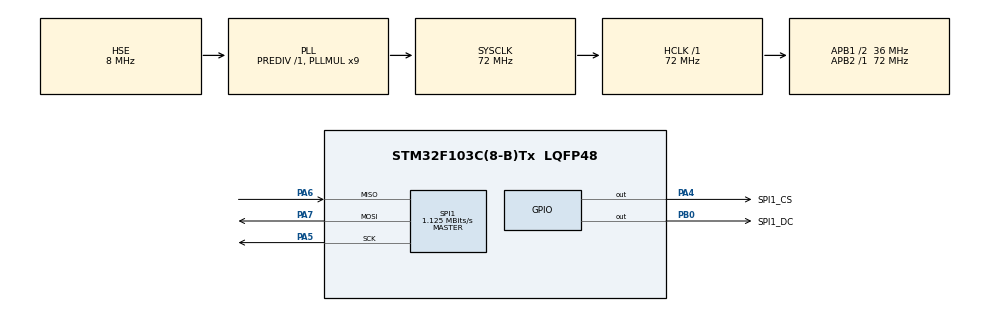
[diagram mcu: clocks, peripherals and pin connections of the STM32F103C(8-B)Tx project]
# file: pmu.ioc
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Mcu.Family=STM32F1
Mcu.Name=STM32F103C(8-B)Tx
Mcu.Package=LQFP48
NVIC.PriorityGroup=NVIC_PRIORITYGROUP_4
PA13.Mode=Serial_Wire
PA13.Signal=SYS_JTMS-SWDIO
PA14.Mode=Serial_Wire
PA14.Signal=SYS_JTCK-SWCLK
PA4.GPIO_Label=SPI1_CS
PA4.PinState=GPIO_PIN_RESET
PA4.Signal=GPIO_Output
PA5.Mode=Full_Duplex_Master
PA5.Signal=SPI1_SCK
PA6.Mode=Full_Duplex_Master
PA6.Signal=SPI1_MISO
PA7.Mode=Full_Duplex_Master
PA7.Signal=SPI1_MOSI
PB0.GPIO_Label=SPI1_DC
PB0.Signal=GPIO_Output
PD0-OSC_IN.Mode=HSE-External-Oscillator
PD0-OSC_IN.Signal=RCC_OSC_IN
PD1-OSC_OUT.Mode=HSE-External-Oscillator
PD1-OSC_OUT.Signal=RCC_OSC_OUT
ProjectManager.HeapSize=0x200
ProjectManager.StackSize=0x400
ProjectManager.TargetToolchain=MDK-ARM V5.32
RCC.AHBFreq_Value=72000000
RCC.APB1CLKDivider=RCC_HCLK_DIV2
RCC.APB1Freq_Value=36000000
RCC.APB1TimFreq_Value=72000000
RCC.APB2Freq_Value=72000000
RCC.APB2TimFreq_Value=72000000
RCC.HCLKFreq_Value=72000000
RCC.PLLMUL=RCC_PLL_MUL9
RCC.PLLSourceVirtual=RCC_PLLSOURCE_HSE
RCC.SYSCLKFreq_VALUE=72000000
RCC.SYSCLKSource=RCC_SYSCLKSOURCE_PLLCLK
RCC.USBFreq_Value=72000000
SPI1.BaudRatePrescaler=SPI_BAUDRATEPRESCALER_64
SPI1.CalculateBaudRate=1.125 MBits/s
SPI1.Direction=SPI_DIRECTION_2LINES
SPI1.Mode=SPI_MODE_MASTER
SPI1.VirtualType=VM_MASTER
board=custom

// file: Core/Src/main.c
/* USER CODE BEGIN Header */
/**
  ******************************************************************************
  * @file           : main.c
  * @brief          : Main program body
  ******************************************************************************
  * @attention
  *
  * Copyright (c) 2022 STMicroelectronics.
  * All rights reserved.
  *
  * This software is licensed under terms that can be found in the LICENSE file
  * in the root directory of this software component.
  * If no LICENSE file comes with this software, it is provided AS-IS.
  *
  ******************************************************************************
  */
/* USER CODE END Header */
#include "main.h"
#include "spi.h"
#include "gpio.h"

/* USER CODE BEGIN Includes */
//#include "struct_typedef.h"
/* USER CODE END Includes */

void SystemClock_Config(void);

/* USER CODE BEGIN 0 */
const unsigned uint8_t gImage_1[32768] = { /* 0X10,0X10,0X00,0X80,0X00,0X80,0X01,0X1B, */
0X49,0XE5,0X41,0XA5,0X41,0XA5,0X41,0XA5,0X41,0X84,0X39,0X43,0X39,0X44,0X39,0X64,
0X39,0X44,0X31,0X23,0X39,0X44,0X39,0X44,0X39,0X44,0X39,0X44,0X39,0X44,0X39,0X64,
0X31,0X23,0X31,0X23,0X31,0X23,0X31,0X23,0X31,0X23,0X31,0X23,0X31,0X43,0X39,0X64,
0X39,0X64,0X31,0X23,0X31,0X23,0X31,0X23,0X39,0X44,0X39,0X44,0X31,0X23,0X39,0X23,
0X41,0X85,0X41,0X64,0X39,0X64,0X39,0X64,0X41,0X64,0X39,0X64,0X39,0X84,0X39,0X84,
0X41,0X84,0X41,0XA5,0X39,0X84,0X31,0X43,0X31,0X43,0X31,0X43,0X31,0X43,0X31,0X43,
0X31,0X23,0X31,0X02,0X29,0X02,0X31,0X43,0X39,0X64,0X39,0X64,0X39,0X64,0X41,0X84,
0X41,0X64,0X39,0X23,0X39,0X43,0X39,0X23,0X39,0X64,0X39,0X64,0X39,0X64,0X39,0X43,
0X39,0X64,0X39,0X64,0X39,0X44,0X39,0X44,0X39,0X44,0X31,0X23,0X31,0X44,0X31,0X23,
0X31,0X03,0X31,0X03,0X31,0X23,0X31,0X23,0X31,0X23,0X31,0X23,0X31,0X03,0X31,0X23,
0X28,0XE2,0X20,0X81,0X28,0XE2,0X31,0X03,0X31,0X23,0X31,0X23,0X31,0X03,0X29,0X02,
0X31,0X03,0X31,0X03,0X29,0X03,0X29,0X03,0X29,0X02,0X29,0X03,0X31,0X03,0X31,0X23,
0X31,0X23,0X31,0X03,0X31,0X23,0X31,0X03,0X31,0X23,0X31,0X03,0X29,0X03,0X29,0X02,
0X29,0X02,0X29,0X23,0X21,0X22,0X29,0X23,0X29,0X23,0X29,0X03,0X29,0X03,0X20,0XE2,
0X20,0XC2,0X28,0XE2,0X29,0X02,0X39,0X64,0X39,0X44,0X31,0X44,0X29,0X03,0X28,0XE2,
0X28,0XE2,0X20,0XA1,0X20,0XA1,0X28,0XC2,0X28,0XE2,0X28,0XE2,0X28,0XE2,0X28,0XE2,
0X49,0XC5,0X39,0X64,0X39,0X63,0X39,0X64,0X39,0X43,0X31,0X23,0X31,0X03,0X31,0X03,
0X31,0X23,0X31,0X03,0X31,0X03,0X31,0X23,0X31,0X23,0X31,0X23,0X31,0X23,0X31,0X03,
0X29,0X02,0X28,0XE2,0X29,0X02,0X28,0XE2,0X28,0XE2,0X29,0X03,0X31,0X03,0X31,0X23,
0X39,0X44,0X31,0X23,0X39,0X23,0X39,0X23,0X39,0X44,0X31,0X23,0X31,0X03,0X31,0X03,
0X39,0X44,0X39,0X44,0X31,0X23,0X31,0X23,0X31,0X23,0X31,0X23,0X31,0X23,0X31,0X43,
0X31,0X23,0X31,0X43,0X31,0X23,0X31,0X23,0X29,0X02,0X31,0X23,0X31,0X23,0X29,0X02,
0X20,0XC1,0X20,0XC1,0X20,0XA1,0X31,0X02,0X31,0X03,0X31,0X43,0X41,0X84,0X39,0X43,
0X31,0X03,0X39,0X43,0X39,0X44,0X39,0X43,0X31,0X23,0X31,0X23,0X31,0X02,0X31,0X02,
0X31,0X03,0X31,0X03,0X31,0X02,0X31,0X02,0X31,0X03,0X28,0XE2,0X28,0XE2,0X28,0XE2,
0X28,0XC2,0X28,0XE2,0X28,0XE2,0X28,0XE2,0X28,0XE2,0X28,0XE2,0X28,0XE2,0X28,0XE2,
0X20,0XA1,0X10,0X40,0X20,0XA1,0X28,0XE2,0X28,0XE2,0X28,0XE2,0X20,0XC2,0X20,0XA1,
0X20,0XA1,0X28,0XC2,0X28,0XE2,0X28,0XE2,0X28,0XC2,0X28,0XE2,0X28,0XE2,0X28,0XE2,
0X28,0XE2,0X28,0XE2,0X28,0XE2,0X28,0XC2,0X20,0XC2,0X20,0XA1,0X20,0XA1,0X20,0XA1,
0X20,0XA1,0X20,0XA1,0X18,0XA1,0X18,0XC1,0X18,0XC1,0X18,0XC1,0X18,0XA1,0X20,0XA1,
0X18,0X80,0X20,0XC1,0X28,0XE2,0X31,0X03,0X29,0X03,0X28,0XE2,0X20,0XC2,0X28,0XE2,
0X28,0XE2,0X28,0XC2,0X20,0XA1,0X18,0X81,0X18,0X81,0X20,0X81,0X20,0X81,0X20,0XA1,
0X41,0X84,0X39,0X63,0X39,0X64,0X39,0X64,0X39,0X43,0X31,0X23,0X31,0X23,0X31,0X03,
0X31,0X03,0X31,0X03,0X31,0X23,0X31,0X23,0X31,0X03,0X31,0X23,0X39,0X23,0X31,0X03,
0X28,0XE2,0X28,0XE2,0X28,0XE2,0X29,0X03,0X29,0X02,0X29,0X02,0X31,0X03,0X31,0X23,
0X31,0X23,0X31,0X03,0X31,0X23,0X31,0X23,0X31,0X23,0X31,0X23,0X28,0XE2,0X28,0XE2,
0X39,0X44,0X39,0X44,0X31,0X23,0X39,0X23,0X39,0X23,0X31,0X23,0X31,0X23,0X31,0X43,
0X39,0X44,0X31,0X43,0X31,0X23,0X29,0X02,0X31,0X23,0X31,0X23,0X31,0X43,0X31,0X23,
0X28,0XE2,0X20,0XA1,0X20,0XA1,0X29,0X02,0X31,0X23,0X20,0XE1,0X52,0X67,0X29,0X23,
0X31,0X03,0X31,0X23,0X39,0X43,0X31,0X23,0X39,0X43,0X39,0X43,0X31,0X03,0X31,0X23,
0X31,0X03,0X31,0X03,0X31,0X03,0X31,0X03,0X31,0X03,0X31,0X02,0X31,0X03,0X28,0XE3,
0X28,0XE2,0X28,0XE2,0X28,0XE2,0X28,0XE2,0X28,0XE2,0X28,0XE2,0X28,0XE2,0X28,0XE2,
0X20,0XA1,0X10,0X40,0X20,0XA1,0X28,0XE2,0X28,0XE2,0X28,0XE2,0X20,0XC1,0X20,0XA1,
0X20,0XA1,0X28,0XE2,0X28,0XE2,0X28,0XE2,0X28,0XC2,0X28,0XE2,0X28,0XE2,0X28,0XE2,
0X28,0XE2,0X28,0XE2,0X28,0XE2,0X28,0XE2,0X20,0XC2,0X20,0XC2,0X20,0XC2,0X20,0XA1,
0X20,0XA1,0X20,0XA1,0X20,0XC1,0X18,0XE2,0X18,0XC2,0X20,0XC1,0X20,0XC1,0X20,0XA1,
0X18,0X81,0X18,0XA1,0X20,0XE2,0X31,0X03,0X29,0X03,0X28,0XE2,0X28,0XC2,0X20,0XC2,
0X20,0XA1,0X20,0X81,0X20,0X81,0X18,0XA1,0X18,0XA1,0X18,0XA1,0X18,0X81,0X18,0X81,
0X41,0X84,0X41,0X84,0X39,0X43,0X39,0X64,0X39,0X43,0X31,0X23,0X31,0X23,0X30,0XE2,
0X31,0X03,0X31,0X03,0X31,0X23,0X31,0X23,0X31,0X03,0X31,0X23,0X31,0X23,0X31,0X23,
0X31,0X03,0X28,0XE2,0X28,0XE2,0X28,0XE2,0X29,0X02,0X29,0X02,0X31,0X03,0X31,0X23,
0X31,0X23,0X31,0X03,0X31,0X23,0X31,0X23,0X31,0X03,0X31,0X23,0X28,0XE2,0X30,0XE2,
0X39,0X44,0X39,0X44,0X39,0X44,0X39,0X44,0X39,0X44,0X31,0X23,0X31,0X23,0X31,0X43,
0X39,0X44,0X31,0X43,0X31,0X23,0X29,0X02,0X31,0X23,0X31,0X23,0X31,0X43,0X29,0X02,
0X29,0X02,0X20,0XC1,0X18,0XA1,0X29,0X02,0X39,0X84,0X6B,0XAC,0X63,0X8B,0X29,0X43,
0X29,0X22,0X31,0X23,0X31,0X23,0X31,0X03,0X39,0X43,0X39,0X43,0X31,0X03,0X31,0X23,
0X31,0X23,0X31,0X23,0X31,0X03,0X31,0X03,0X31,0X03,0X31,0X02,0X28,0XE2,0X28,0XE2,
0X28,0XE2,0X28,0XE2,0X28,0XE2,0X28,0XE2,0X28,0XE2,0X28,0XE2,0X28,0XE2,0X28,0XE2,
0X20,0X81,0X10,0X20,0X20,0X81,0X28,0XE2,0X28,0XE2,0X28,0XE2,0X28,0XE2,0X20,0XC1,
0X28,0XC2,0X28,0XE2,0X28,0XE2,0X28,0XC2,0X28,0XC2,0X28,0XE2,0X28,0XE2,0X28,0XE2,
0X28,0XE2,0X28,0XE2,0X28,0XE2,0X28,0XC2,0X20,0XC2,0X20,0XC2,0X20,0XC2,0X20,0XA1,
0X20,0XC1,0X18,0XC1,0X18,0XC1,0X18,0XC1,0X18,0XC1,0X18,0XA1,0X18,0XA1,0X18,0XA1,
0X10,0X60,0X18,0X81,0X20,0XE2,0X29,0X03,0X29,0X03,0X29,0X03,0X28,0XE2,0X28,0XC2,
0X20,0XC2,0X20,0XA1,0X20,0XA1,0X18,0XA1,0X18,0XA1,0X18,0XA1,0X18,0X81,0X18,0X81,
0X41,0X84,0X39,0X44,0X39,0X44,0X39,0X44,0X39,0X43,0X31,0X23,0X31,0X23,0X31,0X02,
0X31,0X23,0X31,0X23,0X31,0X23,0X31,0X23,0X39,0X23,0X31,0X23,0X39,0X23,0X31,0X23,
0X31,0X23,0X29,0X03,0X28,0XE2,0X28,0XE2,0X28,0XE2,0X28,0XE2,0X31,0X03,0X31,0X23,
0X31,0X23,0X31,0X03,0X31,0X23,0X31,0X23,0X31,0X23,0X31,0X03,0X28,0XE2,0X29,0X02,
0X39,0X44,0X39,0X44,0X39,0X44,0X39,0X44,0X39,0X44,0X39,0X44,0X31,0X43,0X31,0X43,
0X39,0X43,0X39,0X44,0X39,0X23,0X31,0X03,0X31,0X23,0X31,0X23,0X31,0X23,0X31,0X03,
0X28,0XE2,0X20,0XA1,0X18,0XA1,0X29,0X23,0X29,0XC5,0X7C,0XAF,0X5B,0X8C,0X29,0XE6,
0X29,0X43,0X31,0X23,0X39,0X23,0X31,0X23,0X39,0X44,0X31,0X23,0X31,0X23,0X31,0X23,
0X31,0X03,0X31,0X03,0X39,0X03,0X31,0X03,0X31,0X23,0X31,0X03,0X28,0XE2,0X28,0XE2,
0X28,0XE2,0X28,0XC2,0X28,0XE2,0X28,0XE2,0X28,0XE2,0X28,0XE2,0X28,0XE2,0X28,0XE2,
0X18,0XA1,0X10,0X40,0X20,0X81,0X28,0XC2,0X28,0XC2,0X28,0XC2,0X20,0XC2,0X20,0XA1,
0X20,0XA1,0X20,0XC2,0X20,0XC1,0X20,0XC1,0X28,0XC2,0X28,0XE2,0X28,0XC2,0X28,0XE2,
0X28,0XE2,0X28,0XE2,0X28,0XC2,0X20,0XA1,0X28,0XC2,0X28,0XC2,0X20,0XC2,0X20,0XC1,
0X18,0XC1,0X18,0XC1,0X18,0XC1,0X18,0XA1,0X18,0XA2,0X18,0XA2,0X18,0XA2,0X18,0XA2,
0X10,0X61,0X18,0X81,0X29,0X03,0X31,0X23,0X29,0X03,0X29,0X03,0X28,0XE2,0X20,0XC2,
0X20,0XC2,0X18,0XA1,0X18,0XC1,0X18,0XC2,0X18,0XC2,0X18,0XA2,0X18,0XA1,0X18,0X81,
0X41,0X84,0X39,0X44,0X39,0X64,0X39,0X64,0X39,0X44,0X39,0X23,0X31,0X23,0X31,0X02,
0X31,0X03,0X31,0X03,0X31,0X03,0X31,0X23,0X31,0X23,0X31,0X23,0X31,0X03,0X31,0X03,
0X31,0X23,0X29,0X03,0X28,0XE2,0X28,0XE2,0X28,0XE2,0X29,0X03,0X31,0X03,0X31,0X23,
0X31,0X23,0X31,0X03,0X31,0X23,0X31,0X23,0X31,0X23,0X31,0X23,0X29,0X02,0X29,0X03,
0X31,0X44,0X39,0X44,0X39,0X44,0X39,0X44,0X39,0X44,0X31,0X43,0X31,0X23,0X39,0X44,
0X39,0X44,0X39,0X44,0X31,0X43,0X31,0X23,0X29,0X23,0X31,0X44,0X31,0X44,0X31,0X23,
0X29,0X02,0X20,0XC1,0X18,0XA1,0X29,0X23,0X31,0XE5,0X63,0XED,0X43,0X2A,0X53,0X2B,
0X31,0X84,0X39,0X23,0X39,0X03,0X39,0X23,0X39,0X23,0X39,0X03,0X31,0X03,0X31,0X03,
0X31,0X03,0X31,0X03,0X31,0X03,0X31,0X03,0X31,0X23,0X31,0X03,0X28,0XE3,0X28,0XE3,
0X28,0XE2,0X28,0XC2,0X28,0XE2,0X28,0XE2,0X28,0XE2,0X28,0XE2,0X28,0XE2,0X28,0XE2,
0X18,0XA1,0X10,0X40,0X18,0X81,0X28,0XE2,0X28,0XE2,0X20,0XC2,0X20,0XA2,0X20,0XA1,
0X20,0XA1,0X20,0XA2,0X20,0XA1,0X20,0XA1,0X20,0XC2,0X28,0XC2,0X28,0XC2,0X28,0XE2,
0X28,0XE2,0X28,0XE2,0X28,0XE2,0X20,0XC1,0X20,0XC2,0X20,0XC1,0X20,0XA1,0X18,0XA1,
0X18,0XC1,0X18,0XC1,0X18,0XC1,0X18,0XA1,0X18,0XA1,0X18,0XA2,0X18,0XA2,0X18,0XA1,
0X18,0X81,0X18,0X81,0X29,0X03,0X31,0X23,0X31,0X23,0X29,0X03,0X28,0XE2,0X20,0XE2,
0X18,0XA1,0X18,0XA1,0X18,0XA1,0X18,0XA1,0X18,0XA2,0X18,0XA2,0X18,0XA1,0X18,0XA1,
0X39,0X64,0X39,0X44,0X39,0X64,0X39,0X44,0X39,0X64,0X39,0X23,0X31,0X23,0X31,0X03,
0X31,0X03,0X31,0X03,0X31,0X03,0X31,0X03,0X31,0X03,0X39,0X23,0X39,0X23,0X31,0X23,
0X31,0X23,0X31,0X03,0X28,0XE2,0X28,0XE2,0X29,0X03,0X31,0X03,0X31,0X23,0X31,0X43,
0X31,0X23,0X31,0X23,0X39,0X23,0X31,0X23,0X39,0X23,0X31,0X23,0X31,0X23,0X31,0X23,
0X31,0X44,0X39,0X44,0X31,0X23,0X31,0X43,0X39,0X44,0X39,0X44,0X31,0X43,0X39,0X64,
0X39,0X64,0X39,0X44,0X31,0X43,0X29,0X02,0X29,0X23,0X31,0X43,0X31,0X23,0X31,0X23,
0X29,0X03,0X18,0XC1,0X18,0XA1,0X21,0X22,0X4A,0XA8,0X4B,0X29,0X4B,0X8B,0X42,0XE9,
0X39,0XC5,0X31,0X23,0X31,0X03,0X39,0X24,0X39,0X23,0X31,0X03,0X30,0XE2,0X39,0X24,
0X31,0X23,0X29,0X03,0X31,0X23,0X31,0X03,0X31,0X03,0X31,0X03,0X28,0XE2,0X28,0XE2,
0X28,0XE2,0X28,0XE2,0X28,0XE2,0X28,0XE2,0X28,0XE2,0X28,0XE2,0X28,0XE2,0X28,0XE2,
0X20,0XA1,0X10,0X40,0X18,0X81,0X28,0XC2,0X28,0XE2,0X20,0XC2,0X28,0XC2,0X20,0XA1,
0X20,0XC2,0X28,0XC2,0X20,0XC1,0X20,0XC1,0X28,0XC2,0X28,0XC2,0X28,0XE2,0X28,0XE2,
0X28,0XE2,0X28,0XE2,0X20,0XC2,0X20,0XC2,0X20,0XC2,0X20,0XC1,0X20,0XA1,0X20,0XA1,
0X20,0XC1,0X18,0XC1,0X18,0XC1,0X20,0XC1,0X20,0XA1,0X20,0XA2,0X18,0XA2,0X18,0XA2,
0X18,0X81,0X10,0X61,0X20,0XE3,0X31,0X03,0X31,0X03,0X29,0X03,0X28,0XE2,0X20,0XC2,
0X18,0XA1,0X18,0XA1,0X18,0XC1,0X18,0XA2,0X18,0X81,0X18,0XA2,0X18,0X81,0X18,0XA1,
0X39,0X64,0X39,0X44,0X39,0X64,0X39,0X64,0X39,0X64,0X31,0X23,0X31,0X23,0X31,0X03,
0X31,0X23,0X31,0X23,0X31,0X03,0X31,0X03,0X31,0X23,0X31,0X23,0X39,0X44,0X31,0X23,
0X31,0X23,0X31,0X23,0X29,0X02,0X28,0XE2,0X28,0XE2,0X29,0X02,0X31,0X03,0X31,0X23,
0X31,0X23,0X31,0X23,0X31,0X23,0X31,0X23,0X31,0X23,0X31,0X23,0X31,0X23,0X31,0X23,
0X39,0X44,0X31,0X44,0X39,0X64,0X39,0X64,0X39,0X44,0X31,0X43,0X39,0X44,0X39,0X64,
0X39,0X64,0X39,0X64,0X31,0X23,0X31,0X43,0X31,0X63,0X31,0X43,0X31,0X43,0X31,0X23,
0X29,0X02,0X18,0XC1,0X18,0XA1,0X21,0X43,0X74,0X0E,0X43,0X29,0X3B,0X09,0X4B,0X2B,
0X42,0X47,0X31,0X64,0X31,0X23,0X31,0X23,0X31,0X43,0X31,0X43,0X31,0X03,0X31,0X64,
0X31,0X84,0X29,0X23,0X31,0X64,0X31,0X23,0X31,0X03,0X30,0XE2,0X28,0XE2,0X28,0XE2,
0X28,0XE3,0X28,0XE3,0X28,0XE2,0X28,0XE2,0X28,0XE2,0X28,0XE2,0X28,0XE2,0X28,0XE2,
0X20,0XC1,0X10,0X40,0X18,0X60,0X28,0XC2,0X28,0XE2,0X20,0XC2,0X20,0XC2,0X20,0XA1,
0X20,0XA2,0X28,0XC2,0X28,0XC2,0X28,0XC2,0X28,0XE2,0X28,0XC2,0X28,0XE2,0X28,0XE2,
0X28,0XE2,0X28,0XE2,0X20,0XE2,0X20,0XE2,0X20,0XC2,0X20,0XC1,0X20,0XA1,0X20,0XA1,
0X20,0XC1,0X20,0XC1,0X18,0XC1,0X20,0XC1,0X20,0XC1,0X18,0X81,0X18,0XA1,0X18,0XA2,
0X18,0XA1,0X18,0X61,0X20,0XE3,0X29,0X03,0X31,0X23,0X31,0X23,0X28,0XC2,0X20,0XC1,
0X20,0XC2,0X20,0XC2,0X18,0XC1,0X18,0XA2,0X18,0X81,0X18,0XA2,0X20,0X81,0X18,0X81,
0X41,0X85,0X41,0X64,0X39,0X64,0X39,0X64,0X39,0X64,0X31,0X23,0X31,0X03,0X31,0X03,
0X31,0X23,0X31,0X23,0X31,0X23,0X31,0X23,0X31,0X23,0X31,0X23,0X39,0X44,0X31,0X03,
0X31,0X23,0X31,0X23,0X29,0X03,0X28,0XE3,0X31,0X03,0X31,0X03,0X31,0X23,0X31,0X23,
0X31,0X23,0X31,0X23,0X31,0X23,0X31,0X23,0X31,0X03,0X30,0XE3,0X31,0X23,0X39,0X44,
0X39,0X64,0X39,0X64,0X39,0X44,0X39,0X44,0X31,0X44,0X31,0X23,0X31,0X44,0X39,0X64,
0X39,0X64,0X39,0X64,0X31,0X84,0X29,0X84,0X29,0XA4,0X29,0X84,0X31,0XA4,0X29,0X23,
0X29,0X02,0X20,0XE2,0X20,0XC1,0X21,0X43,0X6C,0X0D,0X4B,0X6B,0X43,0X6B,0X43,0X4A,
0X52,0XEA,0X39,0XA5,0X31,0X43,0X31,0X64,0X29,0X43,0X21,0X22,0X31,0XA4,0X53,0X0A,
0X73,0XED,0X8C,0X6F,0X21,0X02,0X31,0X03,0X31,0X03,0X31,0X03,0X28,0XE2,0X28,0XE2,
0X28,0XC2,0X28,0XC2,0X28,0XE2,0X28,0XC2,0X28,0XC2,0X28,0XE2,0X28,0XE2,0X28,0XE2,
0X20,0XC2,0X10,0X60,0X10,0X40,0X20,0XA1,0X28,0XC2,0X20,0XC2,0X20,0XA1,0X20,0XA1,
0X20,0XC2,0X28,0XC2,0X28,0XE2,0X28,0XC2,0X28,0XE3,0X28,0XE2,0X28,0XC2,0X28,0XC2,
0X28,0XC2,0X28,0XE2,0X28,0XC2,0X20,0XC2,0X20,0XC1,0X20,0XC1,0X20,0XC1,0X20,0XA1,
0X20,0XA1,0X20,0XA1,0X20,0XA1,0X20,0XA1,0X20,0XA1,0X20,0XA1,0X20,0XA1,0X18,0X81,
0X18,0X81,0X18,0X61,0X20,0XE3,0X28,0XE2,0X31,0X23,0X28,0XE2,0X28,0XC2,0X28,0XC2,
0X20,0XA2,0X20,0XA2,0X20,0XA2,0X18,0XC2,0X18,0X81,0X18,0X82,0X20,0XA2,0X18,0X81,
0X41,0X85,0X41,0X85,0X39,0X64,0X39,0X64,0X39,0X64,0X31,0X23,0X31,0X23,0X31,0X23,
0X31,0X23,0X31,0X23,0X31,0X23,0X31,0X23,0X31,0X23,0X31,0X23,0X39,0X23,0X31,0X23,
0X31,0X23,0X31,0X43,0X31,0X23,0X29,0X03,0X31,0X03,0X31,0X03,0X31,0X23,0X31,0X03,
0X31,0X03,0X31,0X03,0X31,0X03,0X31,0X03,0X31,0X03,0X28,0XE2,0X31,0X23,0X31,0X23,
0X39,0X44,0X39,0X64,0X39,0X44,0X39,0X44,0X39,0X44,0X39,0X44,0X39,0X64,0X39,0X64,
0X39,0X64,0X39,0X64,0X5A,0XC9,0X74,0X2E,0X74,0X6F,0X74,0X6F,0X63,0XAC,0X3A,0X47,
0X29,0X84,0X21,0X02,0X18,0XC1,0X21,0X43,0X63,0XED,0X4B,0X4B,0X4B,0X6B,0X43,0X4A,
0X5B,0X8C,0X39,0XC5,0X29,0X43,0X29,0X43,0X31,0X84,0X4A,0XA9,0X84,0X90,0X5B,0XCC,
0X5B,0X4B,0X3A,0X06,0X29,0X43,0X31,0X23,0X31,0X03,0X31,0X03,0X29,0X03,0X28,0XE3,
0X28,0XE3,0X28,0XE2,0X28,0XE2,0X28,0XE2,0X28,0XC2,0X28,0XE2,0X28,0XC2,0X28,0XC2,
0X20,0XA2,0X18,0X80,0X10,0X40,0X20,0XC2,0X28,0XE2,0X28,0XC2,0X20,0XC2,0X20,0XA1,
0X20,0XA1,0X20,0XC2,0X28,0XE2,0X28,0XC2,0X28,0XC2,0X28,0XC2,0X28,0XC2,0X28,0XC2,
0X28,0XC2,0X28,0XE2,0X28,0XC2,0X20,0XC2,0X20,0XA1,0X20,0XA1,0X20,0XA1,0X20,0XA1,
0X20,0XA1,0X20,0XA1,0X20,0XA1,0X20,0XA1,0X20,0XA1,0X20,0XA1,0X20,0XA1,0X20,0XA2,
0X18,0X61,0X18,0X61,0X20,0XC2,0X28,0XE2,0X31,0X23,0X28,0XE2,0X28,0XE2,0X28,0XC2,
0X20,0XC2,0X20,0XA2,0X20,0XA2,0X18,0XC2,0X18,0XA2,0X18,0XA2,0X18,0XA2,0X18,0X82,
0X41,0X85,0X39,0X64,0X39,0X44,0X39,0X64,0X39,0X44,0X39,0X23,0X31,0X23,0X31,0X23,
0X31,0X03,0X31,0X23,0X39,0X44,0X39,0X44,0X31,0X23,0X39,0X23,0X39,0X43,0X39,0X44,
0X31,0X23,0X31,0X43,0X31,0X23,0X31,0X03,0X31,0X23,0X31,0X03,0X31,0X03,0X31,0X23,
0X31,0X23,0X31,0X03,0X29,0X03,0X31,0X03,0X31,0X03,0X28,0XE3,0X31,0X03,0X29,0X03,
0X31,0X23,0X39,0X64,0X39,0X64,0X39,0X64,0X39,0X64,0X39,0X44,0X39,0X44,0X39,0X64,
0X39,0X64,0X39,0X64,0X31,0X84,0X5B,0X6B,0X85,0X31,0X74,0XCF,0X6C,0XAF,0X6C,0X8F,
0X6C,0X6E,0X53,0X4A,0X19,0X42,0X32,0X26,0X53,0XAC,0X43,0X4B,0X3B,0X0A,0X43,0X2A,
0X4B,0X2A,0X42,0X68,0X31,0XA5,0X29,0X64,0X73,0XEE,0X5B,0XAC,0X43,0X4A,0X4B,0X4A,
0X53,0X0A,0X21,0X43,0X31,0X43,0X31,0X03,0X31,0X23,0X31,0X23,0X31,0X23,0X31,0X03,
0X29,0X03,0X28,0XE2,0X28,0XC2,0X28,0XC2,0X28,0XC2,0X28,0XE2,0X28,0XE2,0X28,0XE2,
0X28,0XE2,0X10,0X60,0X18,0X60,0X28,0XE2,0X28,0XE2,0X28,0XE2,0X20,0XC2,0X20,0XC2,
0X20,0XC2,0X20,0XC2,0X20,0XC2,0X20,0XA1,0X28,0XE2,0X28,0XC2,0X20,0XC2,0X28,0XC2,
0X28,0XE2,0X28,0XE2,0X20,0XC1,0X20,0XA1,0X20,0XA1,0X20,0XA1,0X20,0XA1,0X20,0XA1,
0X20,0XA1,0X20,0XA1,0X20,0XA1,0X20,0XA1,0X20,0XA1,0X20,0XA1,0X20,0XA1,0X20,0XA1,
0X18,0X80,0X18,0X60,0X20,0XC2,0X28,0XE2,0X29,0X03,0X28,0XE2,0X28,0XE2,0X28,0XE2,
0X28,0XC2,0X18,0XA2,0X18,0XA2,0X18,0XA2,0X18,0XA2,0X18,0X82,0X18,0X82,0X18,0X61,
0X41,0X85,0X39,0X64,0X39,0X44,0X39,0X64,0X39,0X64,0X39,0X44,0X31,0X23,0X31,0X23,
0X31,0X03,0X31,0X23,0X31,0X23,0X31,0X23,0X31,0X23,0X39,0X23,0X39,0X43,0X39,0X44,
0X31,0X23,0X31,0X43,0X31,0X23,0X31,0X03,0X31,0X03,0X31,0X03,0X31,0X03,0X31,0X23,
0X31,0X23,0X31,0X03,0X28,0XE3,0X29,0X03,0X28,0XE3,0X28,0XE2,0X29,0X03,0X29,0X03,
0X28,0XE2,0X31,0X03,0X39,0X64,0X39,0X64,0X39,0X64,0X39,0X44,0X39,0X44,0X39,0X64,
0X39,0X64,0X31,0X84,0X31,0X84,0X21,0X83,0X74,0X4E,0X6C,0XCF,0X6C,0XAF,0X64,0X6E,
0X64,0X2D,0X5C,0X2D,0X64,0X6E,0X5B,0XCC,0X4B,0XAB,0X43,0X4A,0X43,0X4B,0X43,0X4A,
0X4B,0X4A,0X4B,0X4A,0X53,0X4B,0X74,0X4F,0X53,0X8B,0X4B,0X6B,0X3B,0X2A,0X5B,0X6B,
0X31,0XA5,0X31,0X44,0X28,0XE2,0X31,0X03,0X31,0X03,0X29,0X23,0X31,0X03,0X31,0X03,
0X29,0X03,0X28,0XE2,0X28,0XC2,0X28,0XC2,0X28,0XE2,0X28,0XE2,0X28,0XE2,0X28,0XE2,
0X28,0XE2,0X18,0X80,0X18,0X60,0X20,0XC2,0X28,0XE2,0X20,0XC2,0X20,0XC2,0X20,0XC2,
0X20,0XC2,0X20,0XC2,0X20,0XA2,0X28,0XC2,0X28,0XC2,0X20,0XC2,0X20,0XA1,0X28,0XE2,
0X28,0XE2,0X28,0XE2,0X20,0XC1,0X20,0XA1,0X20,0XA1,0X20,0XA1,0X20,0XA1,0X20,0XA1,
0X20,0XA1,0X20,0XA1,0X20,0XA1,0X20,0XA1,0X20,0XA1,0X20,0XA1,0X20,0XA1,0X20,0XC2,
0X18,0X81,0X18,0X60,0X20,0XC1,0X28,0XE2,0X28,0XE2,0X28,0XE2,0X28,0XE2,0X28,0XE2,
0X28,0XE3,0X20,0XA2,0X18,0XA2,0X18,0XA2,0X18,0XA2,0X18,0X82,0X18,0X82,0X18,0X81,
0X41,0X85,0X39,0X64,0X39,0X44,0X39,0X64,0X39,0X64,0X39,0X44,0X31,0X23,0X31,0X23,
0X31,0X23,0X31,0X23,0X31,0X23,0X31,0X03,0X31,0X23,0X31,0X23,0X39,0X44,0X39,0X44,
0X39,0X23,0X39,0X44,0X31,0X44,0X31,0X23,0X31,0X23,0X31,0X23,0X31,0X23,0X31,0X23,
0X31,0X23,0X29,0X03,0X31,0X23,0X29,0X03,0X28,0XE2,0X28,0XE2,0X29,0X02,0X29,0X03,
0X28,0XE2,0X29,0X23,0X31,0X64,0X31,0X44,0X31,0X44,0X39,0X64,0X31,0X44,0X39,0X64,
0X41,0X64,0X39,0X64,0X39,0X64,0X31,0X84,0X31,0XE5,0X74,0XAF,0X64,0X4E,0X5C,0X0C,
0X4B,0X8B,0X5C,0X0C,0X4B,0XAB,0X4B,0X8B,0X43,0X6B,0X3A,0XE9,0X43,0X2A,0X4B,0X4B,
0X43,0X2A,0X43,0X2A,0X53,0X8C,0X4B,0X4B,0X3A,0XE9,0X43,0X2A,0X43,0X0A,0X52,0XC9,
0X39,0X44,0X39,0X44,0X28,0XE2,0X28,0XE2,0X29,0X03,0X29,0X03,0X29,0X03,0X29,0X03,
0X29,0X03,0X28,0XE2,0X28,0XE2,0X28,0XE2,0X28,0XE2,0X28,0XC2,0X28,0XC2,0X28,0XC2,
0X28,0XE2,0X18,0X81,0X10,0X40,0X20,0XA1,0X28,0XE2,0X20,0XC2,0X20,0XA1,0X20,0XA1,
0X20,0XA1,0X20,0XC2,0X28,0XC2,0X20,0XA1,0X28,0XC2,0X20,0XA1,0X20,0XA1,0X20,0XA2,
0X28,0XE2,0X28,0XC2,0X20,0XC2,0X20,0XA1,0X20,0XA1,0X20,0XC2,0X20,0XC2,0X20,0XA1,
0X20,0XA1,0X20,0XA1,0X20,0XC2,0X20,0XA1,0X20,0XA1,0X20,0XA2,0X20,0XA2,0X20,0XA1,
0X18,0X81,0X18,0X60,0X20,0XC2,0X28,0XE2,0X28,0XE2,0X29,0X02,0X28,0XE2,0X28,0XE2,
0X28,0XE2,0X20,0XA2,0X18,0XA2,0X18,0XA1,0X20,0XC2,0X18,0XA2,0X18,0XA2,0X18,0XA2,
0X41,0X85,0X39,0X44,0X39,0X64,0X39,0X64,0X39,0X64,0X39,0X44,0X31,0X23,0X31,0X23,
0X31,0X23,0X31,0X03,0X31,0X23,0X31,0X03,0X31,0X23,0X31,0X23,0X31,0X23,0X39,0X44,
0X39,0X23,0X39,0X44,0X39,0X64,0X31,0X23,0X31,0X43,0X31,0X23,0X31,0X23,0X31,0X23,
0X31,0X23,0X29,0X03,0X31,0X23,0X29,0X03,0X28,0XE2,0X28,0XE2,0X21,0X02,0X29,0X23,
0X29,0X03,0X29,0X23,0X31,0X44,0X31,0X44,0X31,0X44,0X39,0X64,0X31,0X44,0X39,0X64,
0X41,0X64,0X39,0X64,0X39,0X44,0X39,0X64,0X31,0X84,0X3A,0X67,0X6C,0X4E,0X4B,0X8A,
0X4B,0XAB,0X43,0X29,0X53,0XAB,0X4B,0XAB,0X43,0X4B,0X43,0X4B,0X43,0X2A,0X43,0X4B,
0X43,0X0A,0X43,0X6B,0X43,0X4B,0X43,0X4A,0X3B,0X0A,0X43,0X2A,0X4B,0X0A,0X31,0XC6,
0X31,0X24,0X31,0X23,0X28,0XE2,0X28,0XE3,0X31,0X03,0X31,0X03,0X29,0X03,0X29,0X03,
0X28,0XE2,0X28,0XE2,0X28,0XE2,0X28,0XE2,0X28,0XE2,0X28,0XC2,0X28,0XC2,0X28,0XE2,
0X28,0XE2,0X18,0X81,0X10,0X40,0X20,0XA1,0X28,0XC2,0X28,0XC2,0X20,0XA1,0X20,0XA1,
0X20,0XA1,0X20,0XC2,0X20,0XA2,0X20,0XA1,0X28,0XC2,0X20,0XA1,0X20,0XA1,0X20,0XA2,
0X28,0XC2,0X20,0XC2,0X20,0XC2,0X20,0XA1,0X20,0XA1,0X20,0XA1,0X20,0XA1,0X20,0XA1,
0X18,0X81,0X20,0X81,0X20,0XA1,0X20,0XA1,0X20,0XA1,0X20,0XA1,0X20,0X81,0X20,0XA1,
0X18,0X81,0X18,0X80,0X20,0XE2,0X28,0XE2,0X28,0XE2,0X29,0X02,0X28,0XE2,0X28,0XE2,
0X28,0XE2,0X20,0XA1,0X18,0X61,0X18,0XA1,0X20,0XA2,0X18,0XA2,0X18,0XA2,0X18,0X82,
0X39,0X64,0X39,0X64,0X39,0X44,0X39,0X44,0X39,0X64,0X39,0X44,0X39,0X44,0X31,0X23,
0X31,0X23,0X31,0X23,0X31,0X03,0X31,0X03,0X31,0X03,0X31,0X23,0X39,0X23,0X39,0X64,
0X39,0X44,0X39,0X44,0X39,0X64,0X31,0X03,0X29,0X03,0X31,0X23,0X31,0X23,0X31,0X03,
0X29,0X03,0X29,0X03,0X29,0X03,0X29,0X03,0X29,0X03,0X29,0X02,0X21,0X02,0X29,0X43,
0X29,0X23,0X29,0X43,0X31,0X43,0X31,0X43,0X31,0X44,0X39,0X64,0X39,0X64,0X39,0X64,
0X41,0X85,0X39,0X85,0X39,0X64,0X39,0X44,0X31,0X64,0X29,0X84,0X5B,0X6B,0X53,0XAB,
0X53,0XAB,0X53,0XCB,0X43,0X29,0X43,0X6A,0X4B,0X8B,0X43,0X2A,0X43,0X2A,0X3B,0X0A,
0X43,0X2A,0X43,0X0A,0X43,0X2B,0X3A,0XC9,0X43,0X2A,0X43,0X0A,0X4A,0XC9,0X29,0X44,
0X31,0X24,0X31,0X23,0X29,0X03,0X29,0X03,0X29,0X03,0X31,0X23,0X31,0X03,0X31,0X03,
0X28,0XE2,0X28,0XE2,0X28,0XE2,0X28,0XE2,0X28,0XE2,0X28,0XE2,0X28,0XE2,0X28,0XE2,
0X28,0XE2,0X18,0X81,0X10,0X40,0X20,0XC2,0X28,0XC2,0X28,0XC2,0X20,0XC2,0X20,0XA1,
0X20,0XA1,0X20,0XC2,0X20,0XC2,0X20,0XA2,0X20,0XC2,0X20,0XA1,0X20,0XA2,0X20,0XC2,
0X20,0XA2,0X20,0XA1,0X20,0XA1,0X20,0XA1,0X20,0XA1,0X20,0X81,0X18,0X81,0X18,0XA1,
0X18,0XA1,0X20,0XC1,0X18,0XA1,0X20,0XC1,0X18,0XA1,0X18,0XA1,0X18,0XA1,0X18,0XA1,
0X18,0X81,0X10,0X60,0X20,0XA1,0X28,0XE2,0X29,0X02,0X28,0XE2,0X20,0XC2,0X28,0XC2,
0X28,0XE2,0X20,0XC2,0X18,0X81,0X18,0X81,0X18,0XA1,0X18,0XA1,0X20,0XC2,0X18,0XA2,
0X39,0X64,0X39,0X64,0X39,0X44,0X39,0X44,0X39,0X64,0X39,0X44,0X39,0X23,0X31,0X03,
0X31,0X23,0X31,0X23,0X31,0X03,0X31,0X03,0X31,0X23,0X31,0X23,0X39,0X23,0X39,0X44,
0X39,0X44,0X39,0X44,0X31,0X44,0X31,0X23,0X29,0X02,0X29,0X03,0X31,0X23,0X31,0X23,
0X31,0X23,0X29,0X03,0X29,0X03,0X29,0X03,0X29,0X03,0X29,0X03,0X21,0X02,0X29,0X43,
0X29,0X23,0X29,0X43,0X31,0X43,0X31,0X23,0X31,0X44,0X39,0X64,0X31,0X44,0X39,0X64,
0X41,0X64,0X39,0X84,0X39,0X64,0X39,0X64,0X39,0X64,0X31,0X64,0X42,0X67,0X5B,0XAB,
0X4B,0X8B,0X43,0X4A,0X4B,0X8B,0X53,0XCC,0X43,0X4B,0X4B,0X6B,0X43,0X2A,0X43,0X0A,
0X43,0X2A,0X43,0X0A,0X4B,0X4B,0X43,0X2A,0X43,0X2A,0X42,0XEA,0X3A,0X27,0X31,0X65,
0X31,0X24,0X31,0X23,0X29,0X23,0X29,0X03,0X29,0X23,0X31,0X23,0X31,0X03,0X31,0X03,
0X28,0XE2,0X28,0XE2,0X28,0XE2,0X28,0XE2,0X28,0XE2,0X28,0XE2,0X28,0XE2,0X28,0XE2,
0X28,0XE2,0X18,0X81,0X10,0X40,0X20,0XC2,0X28,0XC2,0X28,0XC2,0X20,0XC2,0X20,0XA1,
0X20,0XA1,0X20,0XA1,0X20,0XA2,0X20,0XA1,0X20,0XA2,0X20,0XA1,0X20,0XC2,0X20,0XC2,
0X20,0XA1,0X20,0XA1,0X20,0XA1,0X20,0XA1,0X20,0X81,0X18,0X81,0X18,0X81,0X18,0X81,
0X18,0X81,0X20,0XC1,0X18,0XA1,0X18,0XC1,0X18,0XC1,0X18,0XA1,0X18,0XA1,0X20,0XA1,
0X18,0XA1,0X10,0X60,0X20,0XA1,0X28,0XE2,0X29,0X02,0X28,0XE2,0X28,0XE2,0X28,0XE2,
0X28,0XE2,0X28,0XE2,0X18,0X81,0X18,0X81,0X18,0XA1,0X18,0X81,0X18,0XA2,0X18,0XA2,
0X41,0X85,0X39,0X64,0X39,0X64,0X39,0X44,0X39,0X64,0X39,0X44,0X31,0X44,0X31,0X23,
0X31,0X23,0X29,0X03,0X31,0X23,0X31,0X03,0X31,0X23,0X31,0X23,0X31,0X44,0X31,0X24,
0X31,0X24,0X39,0X44,0X31,0X23,0X31,0X23,0X31,0X03,0X28,0XE2,0X28,0XE2,0X29,0X03,
0X31,0X23,0X29,0X03,0X29,0X03,0X28,0XE2,0X29,0X03,0X31,0X23,0X29,0X23,0X29,0X23,
0X29,0X23,0X31,0X23,0X31,0X23,0X31,0X43,0X31,0X44,0X31,0X64,0X31,0X43,0X39,0X64,
0X41,0X84,0X41,0X64,0X39,0X64,0X41,0X64,0X39,0X64,0X41,0XA5,0X39,0XC5,0X5B,0X6B,
0X4B,0X6B,0X4B,0X6B,0X43,0X4A,0X4B,0X4A,0X4B,0X4B,0X43,0X4A,0X43,0X4A,0X43,0X2A,
0X3B,0X09,0X3A,0XE9,0X43,0X2A,0X43,0X2A,0X43,0X2A,0X43,0X0A,0X31,0XE6,0X39,0X65,
0X31,0X24,0X21,0X23,0X29,0X43,0X29,0X64,0X39,0XA5,0X31,0X44,0X31,0X23,0X31,0X23,
0X29,0X03,0X29,0X03,0X28,0XE2,0X28,0XE2,0X28,0XE2,0X28,0XE2,0X28,0XE2,0X28,0XC2,
0X29,0X03,0X20,0XA1,0X10,0X40,0X20,0XC2,0X20,0XC2,0X28,0XE2,0X20,0XA1,0X20,0XA1,
0X20,0XA1,0X20,0XA1,0X20,0XA1,0X20,0XA1,0X20,0XA1,0X20,0XA1,0X20,0XA1,0X20,0XA1,
0X20,0XA2,0X20,0XA1,0X20,0XA2,0X18,0XA2,0X20,0XA2,0X18,0X81,0X18,0X81,0X18,0XA1,
0X18,0XA1,0X18,0XA1,0X18,0XA2,0X18,0XA2,0X18,0XA1,0X20,0XA2,0X20,0XA1,0X18,0XA1,
0X18,0X81,0X10,0X40,0X20,0XA1,0X20,0XE2,0X28,0XE2,0X28,0XE2,0X28,0XE2,0X28,0XE2,
0X28,0XE2,0X20,0XE2,0X18,0XA1,0X18,0XA1,0X18,0XA2,0X18,0XA2,0X20,0XA2,0X20,0XA2,
0X39,0X64,0X39,0X64,0X39,0X64,0X39,0X44,0X41,0X64,0X39,0X44,0X31,0X43,0X29,0X23,
0X29,0X03,0X29,0X02,0X31,0X03,0X31,0X03,0X31,0X03,0X31,0X23,0X31,0X23,0X31,0X23,
0X31,0X23,0X31,0X44,0X31,0X44,0X31,0X23,0X29,0X03,0X28,0XE2,0X28,0XE2,0X29,0X03,
0X31,0X23,0X31,0X03,0X28,0XE2,0X28,0XE2,0X31,0X03,0X31,0X23,0X29,0X23,0X29,0X03,
0X29,0X23,0X31,0X23,0X31,0X23,0X31,0X44,0X31,0X44,0X31,0X43,0X31,0X43,0X39,0X64,
0X41,0X84,0X39,0X84,0X39,0XA4,0X31,0X84,0X39,0X64,0X41,0XC5,0X29,0X84,0X63,0XAC,
0X53,0X8B,0X4B,0X8B,0X4B,0X8B,0X4B,0X6B,0X4B,0X6B,0X4B,0X8B,0X43,0X2A,0X43,0X2A,
0X43,0X2A,0X43,0X0A,0X3B,0X09,0X3B,0X09,0X43,0X0A,0X43,0X0A,0X29,0X85,0X29,0X24,
0X4A,0X68,0X63,0X8B,0X6B,0XCD,0X74,0X0E,0X73,0XCD,0X5A,0XEA,0X31,0X23,0X31,0X23,
0X29,0X03,0X28,0XE2,0X28,0XE2,0X28,0XE2,0X28,0XE2,0X28,0XE2,0X28,0XE2,0X28,0XE2,
0X28,0XE2,0X20,0XA1,0X10,0X40,0X20,0XC2,0X20,0XC2,0X20,0XC2,0X20,0XA1,0X20,0XA1,
0X20,0XA1,0X20,0XA1,0X20,0XA1,0X20,0X81,0X20,0XA1,0X20,0XA1,0X20,0XA1,0X20,0XC2,
0X28,0XC2,0X20,0XA1,0X20,0XA2,0X18,0XA2,0X18,0X81,0X18,0X82,0X20,0XA2,0X20,0XA1,
0X18,0X80,0X18,0X81,0X18,0X81,0X18,0X82,0X18,0XA1,0X20,0XA2,0X18,0XA1,0X18,0XA1,
0X18,0X81,0X10,0X40,0X18,0XA1,0X20,0XE2,0X28,0XC2,0X28,0XC2,0X28,0XE2,0X28,0XE2,
0X28,0XE2,0X20,0XE2,0X18,0XA1,0X18,0XA2,0X18,0XA2,0X20,0XA2,0X20,0XA2,0X20,0XA2,
0X39,0X44,0X39,0X64,0X39,0X64,0X39,0X64,0X41,0X64,0X39,0X64,0X31,0X43,0X29,0X23,
0X29,0X23,0X29,0X03,0X29,0X03,0X31,0X23,0X31,0X03,0X31,0X03,0X31,0X23,0X39,0X44,
0X31,0X23,0X31,0X44,0X31,0X44,0X31,0X44,0X29,0X03,0X28,0XE2,0X28,0XE2,0X29,0X03,
0X31,0X23,0X31,0X03,0X28,0XE2,0X28,0XE2,0X31,0X23,0X31,0X23,0X29,0X23,0X29,0X03,
0X29,0X23,0X29,0X23,0X29,0X23,0X31,0X64,0X31,0X44,0X31,0X23,0X31,0X23,0X31,0X43,
0X42,0X06,0X5B,0X2A,0X7C,0X4E,0X8C,0XD0,0X74,0X0D,0X5B,0X4A,0X3A,0X66,0X4B,0X4A,
0X53,0XEC,0X4B,0X8B,0X43,0X4A,0X4B,0X6B,0X4B,0X6B,0X43,0X2A,0X43,0X2A,0X3A,0XE9,
0X43,0X4A,0X43,0X2A,0X43,0X0A,0X4B,0X4B,0X43,0X2A,0X3A,0XE9,0X4A,0XEA,0X63,0XCD,
0X64,0X0D,0X53,0XCB,0X4B,0X2A,0X53,0X6B,0X63,0X8C,0X42,0X27,0X29,0X03,0X29,0X03,
0X29,0X03,0X29,0X03,0X28,0XE2,0X28,0XE2,0X28,0XE2,0X28,0XE2,0X28,0XE2,0X28,0XE2,
0X28,0XE2,0X20,0XA1,0X10,0X40,0X20,0XC2,0X20,0XC2,0X20,0XC2,0X20,0XA1,0X20,0XA1,
0X20,0XA1,0X20,0XA1,0X20,0X81,0X18,0X81,0X20,0XA1,0X20,0XA1,0X20,0X81,0X20,0XC2,
0X28,0XE2,0X20,0XA1,0X20,0XA1,0X18,0XA2,0X18,0X81,0X18,0X81,0X18,0XA2,0X18,0XA1,
0X18,0XA1,0X18,0XA1,0X20,0XA2,0X18,0XA2,0X18,0XA2,0X20,0XA2,0X18,0XA1,0X18,0XA1,
0X18,0X81,0X10,0X40,0X18,0X81,0X20,0XC2,0X28,0XC2,0X28,0XC2,0X28,0XE2,0X28,0XC2,
0X28,0XE2,0X28,0XC2,0X20,0XA2,0X18,0XA2,0X18,0XA2,0X20,0XA2,0X20,0XA2,0X20,0XA2,
0X39,0X64,0X39,0X64,0X39,0X64,0X39,0X64,0X39,0X64,0X39,0X64,0X29,0X23,0X21,0X02,
0X29,0X23,0X29,0X03,0X29,0X02,0X29,0X03,0X31,0X03,0X29,0X03,0X31,0X03,0X31,0X23,
0X31,0X03,0X31,0X23,0X31,0X44,0X31,0X23,0X31,0X23,0X28,0XE2,0X29,0X03,0X29,0X03,
0X31,0X23,0X29,0X03,0X28,0XE2,0X29,0X03,0X31,0X23,0X31,0X23,0X29,0X23,0X29,0X23,
0X29,0X03,0X29,0X03,0X31,0X23,0X31,0X44,0X31,0X44,0X31,0X23,0X31,0X23,0X39,0X84,
0X7C,0X4E,0X7C,0XD0,0X7C,0XF0,0X74,0XAF,0X6C,0X6E,0X63,0XEC,0X5C,0X0C,0X5C,0X2D,
0X53,0XEC,0X4B,0X8B,0X4B,0X8B,0X4B,0X6B,0X4B,0X8C,0X43,0X2A,0X43,0X0A,0X43,0X2A,
0X4B,0X4B,0X4B,0X6B,0X43,0X2A,0X43,0X0A,0X43,0X2A,0X43,0X2A,0X3A,0XE9,0X43,0X2A,
0X3B,0X4A,0X3B,0X49,0X4B,0X4A,0X53,0X2A,0X32,0X06,0X21,0X23,0X29,0X03,0X28,0XE2,
0X28,0XE2,0X28,0XE2,0X28,0XE2,0X28,0XE2,0X28,0XE2,0X28,0XC2,0X28,0XE2,0X28,0XE2,
0X20,0XC2,0X20,0XA1,0X10,0X40,0X20,0XA1,0X20,0XA1,0X20,0XA1,0X20,0XA1,0X20,0XA1,
0X20,0XA1,0X20,0XA1,0X20,0XA1,0X18,0X60,0X20,0XA1,0X20,0XA1,0X20,0X81,0X20,0X81,
0X28,0XC2,0X20,0XA1,0X20,0XA2,0X18,0XA1,0X18,0XA1,0X18,0X81,0X18,0X81,0X18,0X81,
0X18,0X80,0X18,0X81,0X18,0X81,0X18,0XA2,0X18,0XA2,0X18,0XA1,0X18,0XA1,0X18,0X81,
0X18,0X81,0X18,0X60,0X18,0XA1,0X20,0XC1,0X28,0XC2,0X28,0XC2,0X28,0XE2,0X28,0XE2,
0X28,0XA1,0X28,0XE2,0X20,0XA2,0X18,0XA2,0X18,0XA2,0X18,0XA2,0X18,0XA2,0X20,0XA2,
0X39,0X64,0X39,0X64,0X39,0X64,0X39,0X64,0X39,0X64,0X39,0X64,0X31,0X43,0X29,0X23,
0X29,0X23,0X29,0X23,0X29,0X23,0X29,0X03,0X29,0X03,0X31,0X23,0X31,0X23,0X31,0X23,
0X31,0X44,0X39,0X44,0X31,0X44,0X31,0X23,0X31,0X23,0X29,0X02,0X29,0X03,0X29,0X03,
0X29,0X03,0X28,0XE2,0X28,0XE2,0X29,0X03,0X31,0X23,0X31,0X23,0X29,0X23,0X29,0X23,
0X29,0X23,0X29,0X03,0X31,0X23,0X31,0X44,0X31,0X64,0X31,0X43,0X31,0X23,0X31,0X84,
0X32,0X05,0X85,0X10,0X74,0XCF,0X64,0X8E,0X5C,0X2D,0X53,0XEC,0X43,0X4A,0X43,0X4A,
0X4B,0X8B,0X4B,0XAB,0X43,0X4A,0X4B,0X6B,0X43,0X2A,0X43,0X2A,0X43,0X2A,0X43,0X2A,
0X3B,0X0A,0X43,0X2A,0X43,0X0A,0X3A,0XE9,0X3A,0XE9,0X43,0X2A,0X43,0X2A,0X43,0X6A,
0X3B,0X29,0X43,0X49,0X4A,0XE9,0X19,0X02,0X29,0X43,0X29,0X02,0X29,0X03,0X28,0XE2,
0X28,0XE2,0X28,0XE2,0X28,0XE2,0X28,0XE2,0X28,0XE2,0X28,0XC2,0X28,0XE2,0X28,0XE2,
0X20,0XC2,0X20,0XC2,0X10,0X40,0X20,0XA1,0X20,0XC2,0X20,0XA1,0X20,0XA1,0X20,0XA1,
0X20,0XC2,0X20,0XC2,0X20,0XA1,0X20,0XA1,0X20,0X81,0X20,0XA1,0X20,0XA1,0X20,0XA1,
0X28,0XC2,0X20,0XA1,0X20,0XA1,0X18,0XA1,0X18,0XA1,0X18,0X81,0X18,0X80,0X18,0X61,
0X18,0X60,0X18,0X81,0X18,0X81,0X18,0XA2,0X18,0XA2,0X18,0XA1,0X18,0XA1,0X18,0XA1,
0X18,0XA1,0X18,0X60,0X18,0XA1,0X20,0XC1,0X28,0XC2,0X28,0XC2,0X28,0XE2,0X30,0XE2,
0X20,0XA1,0X28,0XC2,0X20,0XA2,0X20,0XA2,0X18,0XA2,0X20,0XA2,0X20,0XA2,0X20,0XA2,
0X41,0X85,0X39,0X64,0X41,0X85,0X41,0X64,0X39,0X85,0X39,0X64,0X31,0X44,0X29,0X02,
0X29,0X03,0X31,0X23,0X29,0X23,0X29,0X03,0X31,0X23,0X31,0X23,0X29,0X03,0X31,0X23,
0X31,0X23,0X31,0X43,0X31,0X23,0X31,0X23,0X31,0X23,0X29,0X02,0X29,0X03,0X28,0XE2,
0X28,0XE3,0X28,0XE2,0X29,0X03,0X29,0X03,0X31,0X23,0X31,0X23,0X31,0X23,0X31,0X23,
0X31,0X03,0X31,0X23,0X31,0X23,0X31,0X23,0X31,0X43,0X31,0X43,0X31,0X43,0X31,0X43,
0X31,0X64,0X31,0XC4,0X74,0X4E,0X74,0XCF,0X74,0XAF,0X5C,0X0D,0X4B,0X8B,0X43,0X8B,
0X43,0X6A,0X4B,0X8B,0X43,0X4A,0X43,0X2A,0X4B,0X6B,0X4B,0X6B,0X43,0X2A,0X3A,0XE9,
0X4B,0X6B,0X43,0X4A,0X43,0X2A,0X3A,0XE9,0X4B,0X4B,0X3A,0XE9,0X43,0X29,0X43,0X29,
0X43,0X4A,0X4B,0X4A,0X21,0X63,0X21,0X03,0X29,0X03,0X29,0X03,0X28,0XE2,0X28,0XE2,
0X28,0XE2,0X28,0XE2,0X28,0XE2,0X28,0XE2,0X28,0XE2,0X20,0XC2,0X28,0XC2,0X20,0XC2,
0X20,0XA1,0X20,0XA1,0X10,0X40,0X18,0XA1,0X20,0XC2,0X20,0XA2,0X20,0XA1,0X20,0XA1,
0X20,0XA1,0X20,0XA1,0X20,0XA1,0X20,0XA1,0X18,0X81,0X20,0X81,0X20,0XA1,0X20,0XA1,
0X20,0XC2,0X20,0XA1,0X20,0XA1,0X18,0XA1,0X18,0XA1,0X18,0X81,0X18,0X81,0X18,0XA1,
0X18,0X81,0X18,0XA1,0X18,0XA1,0X18,0XA1,0X18,0XA1,0X18,0XA1,0X18,0XA1,0X18,0XA1,
0X18,0XA1,0X18,0X60,0X18,0X81,0X20,0XA1,0X28,0XE2,0X28,0XE2,0X28,0XE2,0X28,0XC2,
0X20,0XA1,0X28,0XC2,0X20,0XA1,0X20,0XA1,0X18,0X81,0X20,0XA2,0X20,0XA2,0X20,0XA2,
0X41,0X85,0X39,0X44,0X39,0X64,0X39,0X44,0X39,0X64,0X39,0X44,0X31,0X23,0X29,0X03,
0X29,0X23,0X31,0X23,0X31,0X23,0X31,0X23,0X31,0X23,0X29,0X03,0X31,0X23,0X31,0X03,
0X31,0X23,0X31,0X23,0X29,0X03,0X31,0X23,0X31,0X23,0X28,0XE2,0X28,0XE2,0X28,0XE2,
0X28,0XE2,0X28,0XE2,0X29,0X03,0X29,0X03,0X31,0X23,0X31,0X23,0X31,0X44,0X31,0X03,
0X29,0X03,0X29,0X03,0X29,0X03,0X31,0X23,0X31,0X43,0X31,0X43,0X31,0X23,0X31,0X43,
0X31,0X64,0X39,0X64,0X31,0X64,0X4A,0XE8,0X6C,0X2D,0X5C,0X2D,0X53,0XAB,0X3B,0X4A,
0X4B,0XAB,0X43,0X4A,0X43,0X2A,0X4B,0X6B,0X43,0X2A,0X4B,0X6B,0X43,0X2A,0X43,0X4B,
0X43,0X4B,0X4B,0X6B,0X4B,0X4B,0X43,0X2A,0X4B,0X6B,0X43,0X2A,0X3B,0X29,0X4B,0X2A,
0X53,0X2A,0X21,0X84,0X21,0X02,0X20,0XE2,0X29,0X03,0X29,0X03,0X28,0XE2,0X28,0XE2,
0X28,0XC2,0X20,0XC2,0X20,0XC2,0X20,0XC2,0X28,0XE2,0X20,0XA1,0X20,0XC2,0X20,0XC2,
0X20,0XA1,0X20,0XA1,0X10,0X40,0X18,0X81,0X20,0XA1,0X20,0XA1,0X20,0XA1,0X20,0XA1,
0X20,0XA1,0X20,0XA1,0X20,0XA1,0X20,0X81,0X18,0X60,0X20,0XA1,0X20,0XA1,0X20,0X81,
0X20,0XA1,0X20,0XA1,0X20,0XC2,0X20,0XC1,0X20,0XE2,0X18,0X81,0X18,0XA1,0X18,0X81,
0X18,0X80,0X20,0XA1,0X18,0XA1,0X18,0X81,0X18,0X81,0X18,0X81,0X18,0X81,0X18,0XA1,
0X18,0XA1,0X10,0X60,0X18,0X80,0X20,0XA1,0X20,0XA1,0X20,0XA1,0X20,0X81,0X20,0XA1,
0X20,0XA1,0X28,0XE2,0X20,0XA1,0X20,0XA1,0X18,0X81,0X20,0XA2,0X20,0XA2,0X20,0XA2,
0X39,0X64,0X39,0X64,0X39,0X44,0X39,0X44,0X39,0X64,0X39,0X44,0X31,0X43,0X29,0X23,
0X31,0X43,0X29,0X23,0X29,0X03,0X29,0X23,0X31,0X23,0X31,0X23,0X31,0X23,0X31,0X03,
0X31,0X03,0X31,0X23,0X31,0X23,0X29,0X03,0X31,0X23,0X29,0X02,0X28,0XC2,0X20,0XC2,
0X28,0XE2,0X28,0XC2,0X28,0XE2,0X28,0XE2,0X31,0X23,0X31,0X23,0X31,0X23,0X31,0X23,
0X29,0X03,0X31,0X03,0X31,0X23,0X31,0X23,0X31,0X43,0X39,0X23,0X31,0X23,0X31,0X43,
0X39,0X64,0X39,0X64,0X39,0X84,0X31,0XA4,0X42,0XC8,0X64,0X4E,0X53,0XCC,0X4B,0XAB,
0X43,0X6A,0X43,0X6A,0X43,0X6A,0X43,0X4A,0X43,0X4A,0X4B,0X6B,0X4B,0X6B,0X43,0X4A,
0X43,0X4A,0X4B,0X4B,0X43,0X2A,0X43,0X0A,0X43,0X2A,0X43,0X2A,0X43,0X4A,0X43,0X09,
0X32,0X26,0X21,0X83,0X29,0X64,0X31,0X64,0X29,0X03,0X29,0X02,0X28,0XE2,0X28,0XE2,
0X28,0XE2,0X28,0XC2,0X20,0XC2,0X20,0XC2,0X20,0XC1,0X20,0XA1,0X20,0XC2,0X20,0XC2,
0X20,0XA1,0X20,0XA1,0X10,0X40,0X10,0X60,0X20,0XA1,0X20,0XA1,0X20,0XA1,0X20,0XA1,
0X20,0XA1,0X20,0XA1,0X20,0XA1,0X18,0X81,0X18,0X81,0X20,0XA1,0X20,0XA1,0X20,0XA1,
0X20,0XA1,0X20,0XA1,0X20,0XA1,0X20,0XA1,0X20,0XA1,0X18,0X60,0X18,0X81,0X18,0XA1,
0X18,0X81,0X18,0XA1,0X18,0X81,0X18,0X81,0X18,0X81,0X18,0X60,0X20,0XA1,0X18,0XA1,
0X18,0X81,0X10,0X60,0X18,0X81,0X20,0XA1,0X20,0XA1,0X20,0XA1,0X20,0XA1,0X20,0XC1,
0X20,0XC1,0X28,0XE2,0X20,0XA1,0X20,0XA1,0X18,0XA1,0X20,0XA2,0X20,0XA2,0X20,0XA2,
0X39,0X64,0X39,0X64,0X39,0X44,0X39,0X44,0X39,0X64,0X39,0X44,0X31,0X23,0X31,0X23,
0X29,0X23,0X29,0X23,0X29,0X03,0X29,0X03,0X31,0X23,0X31,0X23,0X29,0X03,0X31,0X23,
0X31,0X23,0X31,0X23,0X31,0X23,0X29,0X03,0X31,0X03,0X29,0X02,0X28,0XE2,0X28,0XC2,
0X28,0XE2,0X28,0XE2,0X29,0X03,0X29,0X03,0X29,0X03,0X31,0X03,0X31,0X23,0X31,0X23,
0X31,0X03,0X31,0X23,0X31,0X23,0X31,0X23,0X31,0X23,0X39,0X23,0X39,0X23,0X31,0X43,
0X39,0X64,0X31,0X84,0X31,0X84,0X31,0XC4,0X4A,0XC8,0X64,0X2D,0X53,0XAB,0X4B,0X8A,
0X43,0X6A,0X43,0X6A,0X43,0X4A,0X4B,0X6B,0X43,0X4A,0X4B,0X4A,0X43,0X4A,0X43,0X4A,
0X43,0X4A,0X43,0X2A,0X43,0X0A,0X4B,0X6B,0X53,0X8C,0X53,0X8B,0X53,0XAB,0X4B,0X4A,
0X42,0XC8,0X53,0X4A,0X63,0X8C,0X31,0XA5,0X28,0XE2,0X20,0XE2,0X28,0XE2,0X28,0XE2,
0X28,0XE2,0X28,0XC2,0X20,0XC2,0X20,0XC2,0X20,0XA1,0X20,0XC2,0X20,0XC2,0X20,0XC2,
0X20,0XA1,0X20,0XA1,0X10,0X40,0X18,0X60,0X20,0XA1,0X20,0XA1,0X20,0XA1,0X20,0XA1,
0X20,0XA1,0X20,0XA1,0X20,0XA2,0X20,0XA1,0X20,0XA1,0X20,0X81,0X20,0XA1,0X20,0XA1,
0X20,0XA1,0X20,0XA1,0X20,0XA1,0X20,0XA1,0X20,0XC2,0X18,0X81,0X20,0XA1,0X20,0XC1,
0X18,0X60,0X18,0XA1,0X18,0X81,0X18,0X81,0X18,0X81,0X18,0X60,0X18,0X81,0X18,0XA1,
0X18,0X81,0X10,0X60,0X18,0X60,0X20,0X81,0X20,0XA1,0X20,0XA1,0X20,0XA1,0X20,0XC2,
0X20,0XC2,0X28,0XE2,0X20,0XA1,0X20,0XC1,0X20,0XA1,0X20,0XA2,0X20,0XA2,0X20,0XA2,
0X41,0X85,0X39,0X44,0X39,0X44,0X39,0X44,0X39,0X64,0X31,0X44,0X31,0X23,0X31,0X03,
0X29,0X03,0X31,0X23,0X29,0X03,0X29,0X02,0X31,0X23,0X31,0X03,0X29,0X03,0X29,0X03,
0X31,0X23,0X31,0X23,0X31,0X23,0X29,0X03,0X29,0X02,0X28,0XE2,0X28,0XE2,0X28,0XE2,
0X28,0XE2,0X28,0XE2,0X29,0X03,0X31,0X03,0X28,0XE2,0X28,0XE2,0X29,0X03,0X31,0X23,
0X29,0X03,0X31,0X03,0X31,0X23,0X31,0X23,0X31,0X23,0X31,0X23,0X31,0X23,0X31,0X43,
0X31,0X64,0X63,0X2B,0X84,0X90,0X7C,0X8F,0X6C,0X4E,0X53,0XCC,0X53,0XCC,0X4B,0XAB,
0X43,0X4A,0X43,0X6A,0X4B,0X6A,0X4B,0X6B,0X4B,0X6B,0X4B,0X8B,0X4B,0X6B,0X4B,0X6B,
0X43,0X2A,0X4B,0X6B,0X4B,0X6B,0X4B,0X8B,0X4B,0X6B,0X4B,0X8B,0X43,0X2A,0X4B,0X2A,
0X4B,0X4A,0X53,0X8B,0X5B,0X8C,0X29,0X84,0X29,0X03,0X29,0X03,0X29,0X03,0X28,0XE2,
0X28,0XC2,0X28,0XC2,0X20,0XC2,0X20,0XA1,0X20,0XC1,0X20,0XC2,0X20,0XA1,0X20,0XA1,
0X20,0XA1,0X20,0XA1,0X10,0X40,0X18,0X60,0X20,0XA1,0X20,0XA1,0X20,0XA1,0X20,0XA1,
0X20,0X81,0X20,0X82,0X20,0X82,0X20,0X81,0X20,0X81,0X20,0X81,0X20,0XA1,0X20,0XA1,
0X20,0XA1,0X20,0XA1,0X20,0XA1,0X20,0XA1,0X20,0XA1,0X20,0X81,0X20,0XA1,0X18,0XA1,
0X18,0X81,0X18,0XA1,0X18,0X81,0X10,0X60,0X18,0X81,0X18,0X81,0X18,0X81,0X18,0X81,
0X18,0X81,0X10,0X60,0X18,0X80,0X20,0XA1,0X20,0XA1,0X20,0XC1,0X20,0XC1,0X20,0XC1,
0X20,0XA1,0X28,0XE2,0X20,0XA1,0X20,0XA2,0X18,0X81,0X18,0XA2,0X18,0XA2,0X18,0XA2,
0X41,0XA5,0X39,0X23,0X39,0X64,0X39,0X64,0X39,0X44,0X31,0X43,0X31,0X23,0X31,0X03,
0X29,0X03,0X31,0X23,0X29,0X03,0X29,0X03,0X31,0X23,0X29,0X03,0X28,0XE2,0X31,0X03,
0X31,0X23,0X31,0X23,0X31,0X23,0X29,0X02,0X28,0XE2,0X28,0XE2,0X28,0XE2,0X28,0XE2,
0X28,0XE2,0X29,0X03,0X31,0X03,0X31,0X03,0X28,0XE2,0X28,0XE2,0X28,0XE2,0X31,0X23,
0X29,0X03,0X29,0X03,0X31,0X03,0X31,0X23,0X31,0X23,0X31,0X23,0X31,0X23,0X31,0X23,
0X39,0X44,0X5A,0XEA,0X7C,0X6F,0X5B,0XCC,0X4B,0XCB,0X53,0XAB,0X5B,0XEC,0X53,0XEC,
0X4B,0XAB,0X4B,0X8B,0X4B,0X8B,0X43,0X4A,0X43,0X4B,0X4B,0X4B,0X4B,0X4B,0X4B,0X4B,
0X4B,0X6B,0X43,0X2A,0X4B,0X4B,0X4B,0X4B,0X4B,0X4B,0X43,0X2A,0X43,0X6B,0X43,0X4B,
0X43,0X0A,0X53,0X6B,0X21,0X43,0X29,0X23,0X29,0X02,0X29,0X02,0X31,0X03,0X29,0X02,
0X28,0XE2,0X20,0XC2,0X20,0XC2,0X20,0XA1,0X20,0XC1,0X20,0XC2,0X20,0XA1,0X28,0XE2,
0X20,0XA1,0X20,0XA1,0X10,0X60,0X10,0X60,0X20,0XA1,0X20,0XA1,0X20,0XA1,0X20,0X81,
0X18,0X81,0X18,0X81,0X18,0X81,0X18,0X81,0X20,0XA1,0X20,0XA1,0X20,0XA1,0X20,0XA1,
0X20,0XA1,0X20,0XA1,0X20,0XA1,0X20,0XA1,0X20,0XA1,0X20,0XA1,0X20,0XA1,0X18,0X81,
0X18,0X81,0X18,0X81,0X18,0X81,0X18,0X60,0X18,0X61,0X18,0X61,0X18,0XA1,0X18,0X81,
0X18,0X81,0X10,0X40,0X18,0X61,0X20,0XA1,0X20,0XA1,0X18,0XA1,0X18,0XA1,0X20,0XC1,
0X20,0XA1,0X28,0XE2,0X20,0XA1,0X20,0XA2,0X18,0X81,0X18,0XA2,0X18,0XA2,0X18,0XA1,
0X39,0X64,0X39,0X44,0X39,0X44,0X39,0X44,0X31,0X44,0X31,0X43,0X31,0X23,0X31,0X03,
0X29,0X03,0X29,0X03,0X28,0XE2,0X28,0XE2,0X31,0X03,0X28,0XE2,0X29,0X02,0X29,0X03,
0X29,0X03,0X31,0X23,0X31,0X23,0X29,0X03,0X29,0X02,0X28,0XE2,0X28,0XE2,0X28,0XE2,
0X28,0XE2,0X29,0X03,0X29,0X03,0X29,0X03,0X28,0XE2,0X28,0XE2,0X28,0XE2,0X29,0X03,
0X29,0X03,0X29,0X03,0X29,0X03,0X31,0X03,0X31,0X23,0X31,0X23,0X31,0X23,0X31,0X23,
0X39,0X23,0X31,0X64,0X29,0XA4,0X5B,0X8B,0X5C,0X0C,0X5B,0XEC,0X53,0XCC,0X4B,0XAB,
0X4B,0X8B,0X4B,0X6A,0X4B,0X8B,0X43,0X4A,0X4B,0X6B,0X4B,0X8B,0X4B,0X8B,0X4B,0X8B,
0X53,0XAC,0X4B,0X4B,0X43,0X2A,0X4B,0X6B,0X4B,0X4B,0X43,0X2A,0X43,0X4B,0X43,0X2A,
0X4B,0X2B,0X21,0X84,0X21,0X02,0X28,0XE2,0X29,0X02,0X29,0X02,0X29,0X03,0X28,0XE2,
0X28,0XC2,0X20,0XC2,0X20,0XC2,0X20,0XC2,0X20,0XC1,0X20,0XC2,0X20,0XA1,0X20,0XC2,
0X20,0XC2,0X20,0XA1,0X10,0X20,0X10,0X60,0X20,0XA1,0X20,0XA1,0X20,0XA1,0X18,0XA1,
0X18,0X81,0X18,0X81,0X18,0X82,0X18,0X81,0X18,0X81,0X20,0XA1,0X20,0XA1,0X18,0X81,
0X18,0X80,0X20,0XA1,0X20,0XA1,0X20,0XA1,0X20,0XA1,0X20,0XA1,0X18,0X81,0X18,0XA2,
0X20,0XA2,0X18,0X81,0X18,0X81,0X18,0X81,0X18,0X61,0X18,0X61,0X18,0X81,0X18,0X81,
0X18,0XA2,0X18,0X61,0X18,0X61,0X20,0XA1,0X18,0XA1,0X20,0XA2,0X18,0XC2,0X20,0XC1,
0X18,0XA1,0X28,0XE2,0X20,0XA1,0X18,0XA2,0X18,0XA1,0X18,0XC2,0X18,0XA2,0X18,0XA2,
0X39,0X64,0X31,0X23,0X39,0X44,0X31,0X23,0X31,0X43,0X31,0X23,0X31,0X03,0X29,0X03,
0X28,0XE2,0X29,0X03,0X28,0XE2,0X28,0XE2,0X29,0X02,0X28,0XE2,0X28,0XE2,0X28,0XE2,
0X29,0X02,0X29,0X03,0X29,0X03,0X29,0X03,0X29,0X02,0X28,0XE2,0X28,0XE2,0X28,0XE2,
0X28,0XE2,0X28,0XE2,0X29,0X03,0X28,0XE2,0X29,0X03,0X28,0XE2,0X28,0XE2,0X29,0X03,
0X31,0X03,0X29,0X03,0X28,0XE2,0X28,0XE2,0X29,0X03,0X29,0X03,0X29,0X03,0X31,0X03,
0X31,0X03,0X31,0X23,0X31,0X84,0X29,0X84,0X3A,0X26,0X64,0X4E,0X53,0X8B,0X53,0XCB,
0X4B,0X8B,0X53,0XAB,0X53,0XAC,0X53,0XCC,0X53,0XAC,0X53,0XCC,0X4B,0X6B,0X53,0XAC,
0X53,0XAC,0X4B,0X6B,0X4B,0X6B,0X4B,0X4B,0X43,0X2A,0X4B,0X4B,0X43,0X2A,0X4A,0XE9,
0X29,0X43,0X31,0X23,0X29,0X02,0X28,0XE2,0X29,0X02,0X29,0X02,0X31,0X03,0X29,0X03,
0X28,0XC2,0X20,0XC1,0X20,0XC2,0X20,0XC2,0X20,0XA1,0X20,0XC1,0X20,0XA1,0X20,0XA1,
0X20,0XC2,0X20,0XA1,0X10,0X40,0X10,0X40,0X20,0X81,0X20,0XA1,0X18,0XA1,0X18,0XA1,
0X18,0X81,0X18,0XA1,0X18,0XA2,0X18,0XA1,0X18,0XA1,0X18,0XA1,0X20,0XA1,0X20,0X81,
0X18,0X81,0X20,0XA1,0X20,0XA1,0X20,0XA1,0X20,0XA1,0X20,0XA1,0X18,0X81,0X18,0XA2,
0X18,0X82,0X18,0X82,0X18,0XA2,0X18,0X81,0X18,0X82,0X18,0X81,0X18,0X81,0X18,0X81,
0X20,0XA2,0X18,0X61,0X10,0X41,0X20,0X82,0X18,0XA2,0X20,0XA2,0X18,0XC2,0X20,0XC1,
0X18,0XA1,0X28,0XE2,0X20,0XA1,0X20,0XA2,0X18,0XA2,0X18,0XC2,0X18,0XA2,0X18,0XA1,
0X39,0X44,0X39,0X44,0X31,0X23,0X31,0X23,0X31,0X23,0X31,0X23,0X29,0X03,0X29,0X03,
0X28,0XE2,0X28,0XE2,0X28,0XE2,0X28,0XE2,0X28,0XC2,0X28,0XC2,0X20,0XC2,0X28,0XC2,
0X28,0XE2,0X29,0X03,0X31,0X23,0X29,0X03,0X29,0X02,0X29,0X02,0X28,0XE2,0X28,0XC2,
0X28,0XC2,0X28,0XE3,0X29,0X03,0X28,0XE2,0X28,0XE2,0X20,0XC2,0X28,0XC2,0X28,0XE2,
0X29,0X03,0X28,0XE2,0X28,0XE2,0X28,0XE2,0X28,0XC2,0X28,0XE2,0X28,0XE2,0X29,0X03,
0X31,0X03,0X39,0X23,0X39,0X23,0X31,0X23,0X31,0X64,0X19,0X43,0X53,0X4A,0X5B,0XEC,
0X53,0XCC,0X4B,0X8B,0X5B,0XED,0X53,0XAC,0X5B,0XCC,0X5B,0XAC,0X53,0XAC,0X5B,0XAB,
0X53,0X8B,0X4B,0X69,0X53,0XAA,0X63,0XEC,0X5B,0XAB,0X4B,0X29,0X5B,0X6B,0X3A,0X26,
0X31,0X63,0X31,0X23,0X31,0X03,0X28,0XE2,0X29,0X02,0X29,0X03,0X29,0X02,0X29,0X03,
0X28,0XC2,0X28,0XA1,0X28,0XE2,0X20,0XC2,0X20,0XA1,0X20,0XA1,0X20,0XA1,0X20,0XA1,
0X20,0XC2,0X20,0XC1,0X18,0X80,0X10,0X40,0X18,0XA1,0X20,0XA1,0X20,0XA2,0X20,0X81,
0X18,0X81,0X20,0X82,0X18,0XA1,0X18,0X81,0X18,0X81,0X20,0X81,0X20,0X82,0X20,0X81,
0X20,0XA1,0X20,0XA1,0X20,0XA1,0X20,0XA1,0X20,0XA1,0X20,0X81,0X18,0X81,0X18,0XA2,
0X18,0XA2,0X18,0X81,0X18,0X81,0X18,0X81,0X18,0X80,0X18,0XA1,0X10,0X80,0X10,0X81,
0X18,0X81,0X18,0X60,0X10,0X40,0X20,0XA2,0X18,0XA2,0X20,0XA2,0X20,0XA2,0X20,0XA1,
0X20,0XA1,0X20,0XC2,0X20,0XA1,0X20,0XA1,0X20,0XA1,0X18,0X81,0X18,0X81,0X18,0X81,
0X39,0X44,0X39,0X44,0X31,0X23,0X31,0X03,0X31,0X23,0X31,0X23,0X29,0X03,0X29,0X03,
0X28,0XE2,0X20,0XC2,0X20,0XC2,0X20,0XE2,0X28,0XE2,0X28,0XC2,0X28,0XE2,0X28,0XE2,
0X29,0X02,0X29,0X03,0X28,0XE2,0X28,0XE2,0X29,0X02,0X28,0XE2,0X20,0XC2,0X20,0XA2,
0X20,0XC2,0X28,0XE3,0X29,0X03,0X28,0XE2,0X28,0XC2,0X20,0XA1,0X20,0XA1,0X28,0XC2,
0X28,0XE2,0X28,0XE2,0X28,0XE3,0X28,0XE3,0X28,0XC2,0X28,0XE2,0X28,0XC2,0X29,0X03,
0X31,0X03,0X31,0X23,0X31,0X03,0X31,0X03,0X31,0X44,0X31,0X43,0X29,0X64,0X4A,0XA8,
0X63,0X8B,0X6B,0XEC,0X6B,0XEC,0X74,0X0D,0X74,0X0D,0X8C,0XB0,0X9C,0XD0,0XAD,0X93,
0XBD,0XF3,0XBE,0X33,0XC6,0X33,0XC6,0X33,0XBD,0XF2,0XA5,0X50,0X7C,0X0C,0X6B,0X49,
0X52,0X46,0X49,0XE5,0X39,0X43,0X31,0X02,0X29,0X02,0X29,0X02,0X29,0X02,0X29,0X02,
0X28,0XE2,0X20,0XC1,0X28,0XE2,0X28,0XC2,0X20,0XA1,0X20,0XA1,0X20,0XA1,0X20,0XA1,
0X20,0XA1,0X20,0X81,0X18,0X80,0X10,0X40,0X18,0XA1,0X20,0XA1,0X20,0X81,0X18,0X81,
0X18,0X81,0X18,0X81,0X18,0X80,0X18,0X60,0X18,0X81,0X18,0X81,0X20,0X81,0X20,0X81,
0X20,0XA1,0X20,0XA1,0X20,0XA1,0X20,0XA1,0X20,0XA1,0X20,0XA1,0X20,0XA1,0X18,0X81,
0X18,0XA2,0X18,0XA1,0X18,0XA1,0X18,0X81,0X18,0X80,0X18,0XA1,0X10,0X80,0X10,0XA1,
0X18,0XA1,0X18,0X60,0X10,0X60,0X20,0XA2,0X20,0XA2,0X18,0XA2,0X18,0XA2,0X20,0XA1,
0X20,0XA1,0X20,0XC2,0X20,0XA1,0X20,0XA1,0X18,0XA1,0X20,0XE2,0X20,0XC2,0X18,0XA1,
0X31,0X43,0X31,0X44,0X31,0X23,0X29,0X02,0X31,0X03,0X31,0X03,0X28,0XE2,0X28,0XE3,
0X20,0XE2,0X20,0XC2,0X20,0XC2,0X20,0XE2,0X28,0XE2,0X28,0XC2,0X28,0XC2,0X28,0XE2,
0X28,0XE2,0X28,0XE2,0X29,0X02,0X29,0X03,0X29,0X03,0X29,0X02,0X28,0XC2,0X20,0XA2,
0X20,0XA2,0X28,0XC2,0X28,0XE2,0X28,0XE2,0X28,0XE2,0X20,0XA1,0X20,0XA1,0X20,0XC2,
0X28,0XE2,0X28,0XE2,0X28,0XE2,0X28,0XE2,0X28,0XC2,0X20,0XA2,0X20,0XC2,0X29,0X03,
0X31,0X03,0X31,0X23,0X31,0X23,0X29,0X03,0X39,0X64,0X39,0X43,0X31,0X42,0X52,0X26,
0XBD,0X93,0XDE,0X95,0XDE,0X95,0XDE,0XB6,0XCE,0X13,0XBD,0X31,0XDE,0X35,0XDE,0X55,
0XE6,0X74,0XE6,0X54,0XD5,0XF2,0XD5,0XD2,0XD6,0X13,0XAC,0XAE,0XCD,0XF3,0XDE,0X34,
0XD5,0XF4,0XD6,0X14,0XC5,0X92,0X73,0X29,0X41,0X83,0X39,0X43,0X31,0X23,0X28,0XE1,
0X28,0XE2,0X28,0XE2,0X28,0XC2,0X28,0XC2,0X28,0XC2,0X20,0XC2,0X20,0XA1,0X20,0XA1,
0X20,0XA1,0X18,0X81,0X10,0X60,0X10,0X40,0X18,0X81,0X18,0XA1,0X20,0X81,0X18,0X60,
0X18,0X60,0X18,0X60,0X18,0X80,0X18,0X80,0X18,0X81,0X18,0X81,0X18,0X81,0X20,0X81,
0X20,0XA1,0X20,0XC1,0X20,0XA1,0X20,0XA1,0X20,0XA1,0X20,0XA1,0X20,0XA1,0X18,0X82,
0X18,0XA1,0X18,0XA1,0X18,0XA1,0X18,0X80,0X10,0X80,0X10,0XA1,0X10,0X80,0X10,0XA1,
0X10,0XA1,0X10,0X80,0X10,0X60,0X18,0XA2,0X20,0XA2,0X20,0XA2,0X20,0XA2,0X20,0XA1,
0X20,0XA1,0X20,0XC2,0X20,0XA1,0X18,0XA1,0X18,0XA1,0X18,0XC2,0X18,0XC2,0X18,0XA2,
0X31,0X23,0X31,0X23,0X31,0X03,0X29,0X02,0X31,0X02,0X31,0X02,0X28,0XE2,0X28,0XE2,
0X20,0XC2,0X20,0XC2,0X20,0XE2,0X20,0XE3,0X20,0XC1,0X28,0XE2,0X28,0XE2,0X28,0XE2,
0X28,0XE2,0X28,0XE2,0X29,0X02,0X28,0XE2,0X28,0XE2,0X31,0X03,0X28,0XE2,0X20,0XA2,
0X20,0XA2,0X20,0XC2,0X28,0XC2,0X28,0XE2,0X28,0XE2,0X20,0XC2,0X20,0XC2,0X28,0XE2,
0X28,0XE2,0X28,0XE2,0X28,0XE2,0X28,0XC2,0X28,0XC2,0X28,0XC2,0X20,0XA2,0X28,0XE3,
0X31,0X23,0X31,0X23,0X31,0X23,0X31,0X23,0X52,0X07,0X62,0XA7,0XCD,0XF4,0XDE,0X75,
0XEE,0XB5,0XEE,0X95,0XE6,0X74,0XE6,0X33,0XE6,0X33,0XDD,0XF4,0XEE,0X55,0XEE,0X54,
0XD5,0X91,0XDD,0XD2,0XE5,0XF3,0XD5,0XB2,0XAC,0X6D,0XD5,0X92,0XDD,0XF4,0XDE,0X13,
0XD5,0XF2,0XE6,0X53,0XDE,0X53,0XD6,0X33,0XD6,0X14,0XB4,0XF0,0X62,0X68,0X31,0X23,
0X29,0X22,0X20,0XE1,0X28,0XC2,0X28,0XC2,0X20,0XC2,0X20,0XC1,0X20,0XA1,0X20,0XA1,
0X20,0XA1,0X20,0XA1,0X10,0X60,0X10,0X40,0X18,0X81,0X18,0XA1,0X20,0X81,0X18,0X60,
0X18,0X60,0X18,0X60,0X18,0X80,0X18,0X80,0X18,0X81,0X18,0X81,0X20,0X81,0X20,0X81,
0X20,0X81,0X20,0XC1,0X20,0XA1,0X20,0XA1,0X20,0XC2,0X20,0XC1,0X20,0XA1,0X18,0X82,
0X18,0XA1,0X18,0XA1,0X18,0X80,0X10,0X60,0X10,0X60,0X10,0X80,0X10,0XA0,0X10,0XA1,
0X10,0XA1,0X10,0X80,0X10,0X60,0X18,0X81,0X20,0XA2,0X20,0XA2,0X20,0XA2,0X20,0XC2,
0X20,0XC2,0X20,0XC2,0X20,0XA1,0X18,0XA1,0X18,0XA1,0X18,0XC1,0X18,0XA1,0X10,0X81,
0X29,0X03,0X31,0X23,0X29,0X03,0X29,0X03,0X29,0X03,0X28,0XE2,0X20,0XC2,0X20,0XE2,
0X20,0XE3,0X20,0XC3,0X18,0XA2,0X20,0XC3,0X20,0XC2,0X28,0XC2,0X28,0XE2,0X28,0XE2,
0X28,0XE2,0X28,0XE3,0X28,0XE2,0X28,0XE2,0X28,0XE2,0X28,0XE2,0X28,0XE2,0X20,0XC2,
0X20,0XA2,0X20,0XC2,0X28,0XC2,0X28,0XC2,0X28,0XC2,0X28,0XC2,0X20,0XA2,0X28,0XC2,
0X28,0XE2,0X28,0XE2,0X28,0XE2,0X28,0XE2,0X28,0XE2,0X28,0XE3,0X28,0XC2,0X28,0XE2,
0X31,0X03,0X29,0X22,0X31,0X22,0X39,0X42,0XB5,0X31,0XEE,0X75,0XE6,0X75,0XEE,0X74,
0XEE,0X94,0XEE,0X74,0XEE,0X74,0XEE,0X74,0XEE,0X54,0XE6,0X74,0XE6,0X54,0XE6,0X33,
0XC5,0X50,0XBC,0XEF,0XB4,0XAE,0XBC,0XEF,0XCD,0X91,0XDD,0XF3,0XDE,0X13,0XDE,0X13,
0XDE,0X12,0XDE,0X53,0XE6,0X73,0XE6,0X53,0XE6,0X54,0XDE,0X33,0XD6,0X14,0XA4,0X8F,
0X49,0XA4,0X31,0X02,0X39,0X64,0X31,0X23,0X28,0XE2,0X28,0XC2,0X28,0XA2,0X20,0XA2,
0X20,0XA1,0X20,0XA1,0X10,0X60,0X10,0X20,0X18,0X81,0X18,0X81,0X18,0XA1,0X18,0X81,
0X18,0X80,0X18,0X80,0X20,0X81,0X18,0X61,0X18,0X61,0X18,0X81,0X18,0X81,0X18,0XA1,
0X20,0XA1,0X20,0XA2,0X20,0XA1,0X20,0XA1,0X20,0XC1,0X20,0XA1,0X20,0XA1,0X18,0XA2,
0X18,0XA1,0X18,0XC1,0X10,0X80,0X08,0X60,0X10,0X60,0X10,0X80,0X10,0X80,0X10,0X80,
0X10,0X80,0X10,0X80,0X10,0X60,0X18,0X81,0X20,0XA1,0X20,0XA1,0X20,0XA1,0X20,0XA1,
0X20,0XC1,0X20,0XC2,0X20,0XC1,0X18,0XA1,0X18,0XA1,0X18,0XA1,0X18,0XA1,0X10,0X80,
0X29,0X03,0X31,0X03,0X28,0XE2,0X29,0X03,0X29,0X03,0X28,0XE2,0X20,0XC2,0X20,0XC2,
0X20,0XC2,0X20,0XE3,0X20,0XC2,0X18,0X81,0X20,0XA2,0X28,0XC2,0X28,0XE2,0X28,0XE2,
0X28,0XE2,0X28,0XE3,0X28,0XE2,0X28,0XC2,0X28,0XE2,0X28,0XE2,0X28,0XE3,0X20,0XC2,
0X20,0XA2,0X20,0XC2,0X28,0XC2,0X28,0XC2,0X28,0XE2,0X28,0XE2,0X28,0XE2,0X28,0XE2,
0X28,0XE2,0X28,0XE2,0X28,0XE2,0X28,0XE2,0X29,0X03,0X31,0X03,0X28,0XC2,0X28,0XE2,
0X28,0XE2,0X21,0X21,0X39,0X63,0XB4,0XF0,0XDE,0X14,0XE6,0X54,0XE6,0X74,0XEE,0X94,
0XEE,0X94,0XF6,0XB5,0XEE,0X74,0XCD,0X90,0XC5,0X2F,0XCD,0X70,0XC5,0X70,0XD5,0XD2,
0XDE,0X34,0XE6,0X33,0XDE,0X13,0XC5,0X30,0XD5,0XB2,0XDD,0XD3,0XDD,0XD2,0XDE,0X13,
0XE6,0X53,0XE6,0X74,0XE6,0X74,0XE6,0X53,0XDE,0X53,0XE6,0X53,0XE6,0X54,0XDE,0X13,
0XCD,0XB3,0X8B,0XCB,0X41,0X62,0X31,0X21,0X31,0X22,0X31,0X03,0X28,0XC2,0X20,0XA1,
0X20,0XA1,0X18,0X81,0X18,0X60,0X10,0X20,0X18,0X81,0X18,0X81,0X18,0X81,0X18,0X81,
0X18,0X81,0X18,0X81,0X18,0X81,0X18,0X60,0X18,0X61,0X18,0X81,0X18,0XA1,0X18,0XA1,
0X18,0XA1,0X20,0XA1,0X20,0XC2,0X20,0XA1,0X20,0XC1,0X20,0XA1,0X20,0XA1,0X18,0X81,
0X18,0XA1,0X18,0XA1,0X10,0X80,0X08,0X60,0X10,0X60,0X10,0X60,0X10,0X60,0X10,0X80,
0X18,0X80,0X10,0X60,0X10,0X60,0X18,0X81,0X20,0XA1,0X20,0XA1,0X18,0XA1,0X18,0XA1,
0X20,0XC1,0X20,0XC1,0X20,0XC1,0X18,0XA1,0X18,0XA1,0X18,0X81,0X18,0X81,0X18,0X81,
0X29,0X03,0X29,0X03,0X28,0XE2,0X29,0X02,0X28,0XE2,0X28,0XE2,0X28,0XE2,0X20,0XC2,
0X20,0XC2,0X20,0XC2,0X20,0XA2,0X18,0XA1,0X20,0XC2,0X28,0XC2,0X28,0XE2,0X28,0XE2,
0X29,0X03,0X28,0XE3,0X28,0XE2,0X28,0XE2,0X28,0XE2,0X28,0XE2,0X28,0XC2,0X20,0XA2,
0X20,0XA2,0X28,0XC2,0X28,0XE2,0X28,0XC2,0X28,0XC2,0X28,0XC2,0X28,0XE2,0X28,0XE2,
0X28,0XE2,0X28,0XE2,0X28,0XE2,0X28,0XE2,0X29,0X03,0X31,0X23,0X28,0XE2,0X29,0X02,
0X31,0X22,0X39,0X82,0XBD,0X52,0XE6,0X56,0XEE,0X55,0XEE,0X54,0XEE,0X74,0XEE,0X74,
0XF6,0X94,0XEE,0X74,0XE6,0X53,0XEE,0X94,0XEE,0X74,0XE6,0X74,0XE6,0X74,0XE6,0X94,
0XEE,0X95,0XEE,0X75,0XDE,0X13,0XD5,0XB2,0XD5,0X92,0XDD,0XF3,0XD5,0X91,0XC5,0X2F,
0XE6,0X33,0XE6,0X53,0XE6,0X54,0XE6,0X53,0XE6,0X53,0XE6,0X73,0XE6,0X33,0XDE,0X12,
0XBD,0X2F,0XD5,0XD2,0XCD,0XD2,0XB5,0X10,0XAC,0XD0,0X6A,0XC9,0X29,0X01,0X20,0XA0,
0X20,0XC1,0X18,0X81,0X18,0X60,0X08,0X20,0X18,0X81,0X18,0X80,0X18,0X81,0X18,0X81,
0X18,0X81,0X18,0X61,0X10,0X80,0X10,0X80,0X18,0X60,0X18,0X81,0X18,0XA1,0X18,0XA1,
0X18,0XA1,0X20,0XC1,0X20,0XA1,0X20,0XA1,0X20,0XC1,0X20,0XA1,0X20,0XA1,0X20,0X81,
0X18,0X81,0X18,0XA1,0X10,0X80,0X10,0X60,0X10,0X80,0X10,0X60,0X10,0X60,0X18,0X80,
0X18,0X80,0X10,0X40,0X10,0X40,0X18,0X81,0X20,0XA1,0X20,0XC2,0X20,0XC1,0X18,0XC1,
0X18,0XC1,0X20,0XC1,0X20,0XC1,0X18,0XA1,0X18,0X81,0X10,0X60,0X18,0X80,0X18,0X81,
0X29,0X03,0X31,0X03,0X28,0XE2,0X28,0XE2,0X28,0XE2,0X28,0XE2,0X20,0XE2,0X20,0XC2,
0X20,0XC2,0X20,0XC1,0X20,0XA1,0X18,0XA1,0X20,0XA1,0X20,0XC2,0X28,0XC2,0X28,0XE2,
0X28,0XE2,0X28,0XE2,0X28,0XE2,0X28,0XE2,0X28,0XE2,0X28,0XC2,0X20,0XC2,0X20,0XA2,
0X20,0XA2,0X28,0XC2,0X28,0XE2,0X28,0XE2,0X20,0XC2,0X20,0XC2,0X28,0XE2,0X28,0XE2,
0X28,0XE2,0X28,0XE2,0X28,0XE2,0X28,0XE2,0X28,0XE2,0X31,0X03,0X28,0XE2,0X29,0X02,
0X31,0X43,0X9C,0X2D,0XE6,0X77,0XBD,0X11,0XE6,0X34,0XE6,0X34,0XE6,0X54,0XE6,0X33,
0XEE,0X54,0XEE,0X74,0XEE,0X54,0XEE,0X74,0XEE,0X74,0XE6,0X94,0XE6,0X94,0XE6,0X94,
0XE6,0X95,0XEE,0X75,0XE6,0X13,0XDE,0X13,0XC5,0X30,0XD5,0XD2,0XCD,0X50,0XBC,0XEE,
0XCD,0X91,0XE6,0X33,0XE6,0X54,0XE6,0X54,0XE6,0X53,0XE6,0X33,0XE6,0X33,0XBC,0XCE,
0XE6,0X33,0XDE,0X33,0XDE,0X33,0XDE,0X13,0XC5,0X91,0XD5,0XD3,0XA4,0XAF,0X49,0XC5,
0X31,0X22,0X28,0XE2,0X18,0XA1,0X10,0X40,0X18,0X81,0X18,0X80,0X18,0X81,0X18,0X81,
0X18,0X61,0X18,0X61,0X10,0XA0,0X10,0X80,0X18,0X80,0X18,0X81,0X18,0X81,0X10,0X81,
0X18,0X81,0X20,0XA1,0X20,0XA1,0X20,0XA1,0X20,0XA1,0X20,0XC1,0X20,0XA2,0X20,0XA2,
0X18,0X81,0X18,0XA1,0X10,0X60,0X18,0XA1,0X18,0X80,0X18,0X60,0X10,0X60,0X18,0X60,
0X10,0X60,0X10,0X40,0X10,0X40,0X18,0X80,0X20,0XA1,0X20,0XA1,0X18,0XA1,0X18,0XC1,
0X18,0XC1,0X18,0XC1,0X20,0XE2,0X20,0XA1,0X10,0X60,0X10,0X40,0X10,0X40,0X10,0X61,
0X29,0X03,0X29,0X03,0X28,0XE2,0X28,0XE2,0X29,0X02,0X28,0XE2,0X28,0XC2,0X20,0XC1,
0X20,0XC1,0X18,0XA1,0X20,0XE2,0X18,0XA1,0X20,0XA1,0X20,0XC2,0X20,0XA1,0X28,0XC2,
0X28,0XE2,0X28,0XE2,0X28,0XE2,0X28,0XE2,0X28,0XE2,0X28,0XC2,0X28,0XC2,0X28,0XC2,
0X20,0XA1,0X20,0XC2,0X28,0XC2,0X20,0XC2,0X20,0XA1,0X20,0XA1,0X28,0XE2,0X28,0XE2,
0X28,0XE2,0X28,0XE3,0X28,0XE3,0X28,0XE3,0X28,0XE3,0X31,0X23,0X29,0X03,0X39,0X43,
0X94,0X0D,0XE6,0X76,0XE6,0X76,0XDE,0X34,0XC5,0X30,0XE6,0X54,0XEE,0X74,0XDE,0X13,
0XCD,0X91,0XE6,0X33,0XEE,0X74,0XEE,0X74,0XEE,0X94,0XEE,0X95,0XEE,0X74,0XEE,0X95,
0XE6,0X94,0XE6,0X74,0XDD,0XF2,0XCD,0X91,0XB4,0X8D,0XD5,0X91,0XBD,0X0F,0XCD,0X50,
0XD5,0XB1,0XCD,0X50,0XBC,0XEE,0XD5,0XB1,0XDD,0XF2,0XD5,0XB1,0XB4,0XCE,0XE6,0X33,
0XE6,0X33,0XE6,0X33,0XE6,0X33,0XE6,0X33,0XE6,0X33,0XDD,0XF2,0XCD,0XD3,0XCD,0XD2,
0XA4,0XAF,0X6A,0XE8,0X28,0XE2,0X18,0X60,0X18,0X80,0X18,0X80,0X20,0X82,0X18,0X61,
0X10,0X60,0X10,0X60,0X10,0X80,0X18,0X80,0X18,0X80,0X18,0X81,0X18,0XC1,0X18,0XC1,
0X18,0XA1,0X18,0XA1,0X18,0XA1,0X20,0XA1,0X20,0XA1,0X20,0XA1,0X20,0XC1,0X20,0XA1,
0X20,0XA1,0X18,0X81,0X10,0X40,0X18,0XA1,0X18,0XA1,0X18,0X60,0X10,0X60,0X10,0X60,
0X10,0X60,0X18,0X60,0X10,0X40,0X18,0X81,0X18,0XA1,0X20,0XC1,0X20,0XC1,0X20,0XE2,
0X18,0XC1,0X20,0XE2,0X20,0XE2,0X18,0X81,0X10,0X60,0X10,0X60,0X10,0X61,0X10,0X61,
0X29,0X03,0X29,0X03,0X28,0XE2,0X28,0XE2,0X28,0XE2,0X28,0XC2,0X20,0XC1,0X20,0XA1,
0X20,0XA1,0X18,0XA1,0X20,0XC2,0X18,0XA1,0X20,0XA1,0X20,0XA1,0X20,0XA1,0X28,0XC2,
0X28,0XE2,0X28,0XE2,0X28,0XE2,0X28,0XE2,0X28,0XE2,0X28,0XC2,0X28,0XC2,0X28,0XC2,
0X28,0XC2,0X20,0XA2,0X20,0XA1,0X20,0XA1,0X20,0XA2,0X20,0XC1,0X20,0XC2,0X28,0XA1,
0X28,0XC2,0X28,0XE2,0X28,0XE2,0X28,0XE2,0X28,0XE2,0X31,0X43,0X31,0X43,0X62,0XA8,
0XDE,0X55,0XE6,0X96,0XE6,0X75,0XE6,0X54,0XEE,0X75,0XEE,0X74,0XEE,0X74,0XE6,0X54,
0XDD,0XF2,0XBD,0X0F,0XE6,0X33,0XEE,0X74,0XEE,0X94,0XEE,0X95,0XEE,0X95,0XEE,0X94,
0XE6,0X74,0XE6,0X33,0XD5,0XB1,0XC5,0X0F,0XA4,0X0B,0XCD,0X71,0XBD,0X0F,0XD5,0XB1,
0XDD,0XF2,0XE6,0X13,0XE6,0X54,0XCD,0X91,0XB4,0XCE,0XA4,0X4C,0XCD,0X70,0XDD,0XF2,
0XE6,0X33,0XE6,0X33,0XE6,0X33,0XE6,0X33,0XE6,0X33,0XE6,0X33,0XDE,0X13,0XD5,0XF3,
0XD5,0XD3,0XD5,0XF4,0XB5,0X11,0X41,0X83,0X29,0X01,0X28,0XE2,0X18,0XA2,0X18,0X81,
0X10,0X61,0X10,0X61,0X10,0X80,0X18,0X80,0X18,0X81,0X18,0X81,0X18,0XA1,0X18,0XA1,
0X18,0XA1,0X18,0XA1,0X18,0X81,0X20,0X81,0X20,0XA1,0X20,0XA1,0X20,0XA1,0X18,0XA1,
0X18,0XA1,0X18,0X81,0X10,0X60,0X18,0XA1,0X18,0XA1,0X18,0X80,0X10,0X60,0X10,0X60,
0X10,0X60,0X18,0X60,0X10,0X20,0X18,0X61,0X18,0X81,0X20,0XC2,0X20,0XC2,0X20,0XC1,
0X20,0XC1,0X20,0XE2,0X20,0XC1,0X18,0X81,0X10,0X60,0X10,0X40,0X10,0X60,0X10,0X60,
0X29,0X03,0X29,0X03,0X28,0XE2,0X29,0X02,0X29,0X02,0X28,0XC2,0X20,0XA1,0X20,0XC1,
0X20,0XC1,0X20,0XA1,0X20,0XC2,0X20,0XA2,0X20,0XA2,0X20,0X81,0X20,0XA1,0X28,0XC2,
0X28,0XC2,0X28,0XE2,0X28,0XE2,0X28,0XE2,0X28,0XE2,0X28,0XE3,0X20,0XA2,0X20,0XA2,
0X20,0XC2,0X20,0XA2,0X20,0XA1,0X20,0XA1,0X20,0XC2,0X20,0XC2,0X20,0XA1,0X20,0XA1,
0X28,0XC2,0X28,0XE2,0X28,0XE2,0X29,0X03,0X31,0X03,0X41,0X84,0X73,0X09,0XDE,0X55,
0XEE,0XB5,0XE6,0X74,0XEE,0X95,0XEE,0X75,0XEE,0X75,0XEE,0X74,0XEE,0X95,0XEE,0X95,
0XEE,0X74,0XEE,0X74,0XE6,0X33,0XD5,0XB1,0XDD,0XF2,0XEE,0X74,0XEE,0X95,0XEE,0XB5,
0XE6,0X74,0XDE,0X12,0XC5,0X50,0XB4,0X8D,0X93,0XAA,0XCD,0X71,0XCD,0X71,0XE6,0X34,
0XE6,0X33,0XE6,0X53,0XE6,0X13,0XDD,0XF2,0XBC,0XEE,0XD5,0XB1,0XD5,0XB1,0XBD,0X0F,
0XC5,0X50,0XDD,0XF2,0XE6,0X33,0XE6,0X33,0XE6,0X54,0XE6,0X54,0XEE,0X53,0XE6,0X33,
0XD5,0XB2,0XCD,0XB2,0XC5,0X92,0XC5,0X92,0XB5,0X30,0X5A,0X87,0X28,0XE2,0X18,0X81,
0X18,0X81,0X10,0X61,0X18,0XA1,0X18,0X80,0X18,0X80,0X18,0X80,0X18,0X81,0X18,0XA1,
0X18,0X81,0X18,0XA1,0X20,0XA1,0X20,0XA1,0X20,0XA1,0X20,0XA1,0X20,0XC1,0X20,0XA1,
0X18,0X81,0X10,0X60,0X10,0X60,0X18,0XA1,0X18,0XC1,0X10,0X80,0X18,0XA1,0X10,0X80,
0X10,0X60,0X10,0X40,0X10,0X20,0X18,0X61,0X18,0X81,0X20,0XA1,0X18,0XA1,0X20,0XC1,
0X20,0XC1,0X20,0XC2,0X20,0XA1,0X18,0X81,0X10,0X60,0X10,0X40,0X10,0X61,0X10,0X80,
0X31,0X23,0X28,0XE2,0X28,0XC2,0X28,0XE2,0X28,0XE2,0X28,0XC2,0X28,0XC2,0X28,0XE2,
0X28,0XC2,0X20,0XC2,0X20,0XC2,0X20,0XC2,0X20,0XA2,0X20,0XC2,0X20,0XA1,0X28,0XC2,
0X28,0XC2,0X28,0XE2,0X28,0XE2,0X28,0XE2,0X28,0XE2,0X28,0XC2,0X20,0XC2,0X20,0XC2,
0X20,0XA1,0X20,0XA2,0X28,0XC2,0X20,0XA2,0X20,0XA1,0X20,0XC2,0X20,0XA1,0X20,0XA1,
0X28,0XC2,0X28,0XE2,0X29,0X02,0X29,0X02,0X39,0X64,0X9C,0X4F,0XDE,0X75,0XE6,0X94,
0XE6,0XB4,0XEE,0X94,0XEE,0X94,0XEE,0X95,0XEE,0X74,0XEE,0X74,0XEE,0X95,0XEE,0X95,
0XEE,0X74,0XF6,0XB5,0XEE,0X94,0XEE,0X74,0XEE,0X95,0XD5,0XB1,0XC5,0X2F,0XC5,0X70,
0XC5,0X90,0XCD,0X70,0XB4,0XAD,0XA4,0X2B,0XA3,0XEB,0XDD,0XF3,0XE6,0X13,0XE6,0X34,
0XE6,0X53,0XE6,0X54,0XDE,0X13,0XB4,0XAD,0XE6,0X33,0XE6,0X54,0XE6,0X54,0XE6,0X54,
0XE6,0X33,0XD5,0XD2,0XCD,0X70,0XBD,0X0F,0XCD,0X50,0XD5,0XD2,0XE6,0X13,0XEE,0X74,
0XE6,0X34,0XCD,0XB2,0XC5,0X51,0XDE,0X13,0XD6,0X13,0XB5,0X10,0XA4,0X8F,0X28,0XE1,
0X20,0XC1,0X18,0X81,0X18,0XA1,0X18,0X80,0X18,0X80,0X18,0X80,0X18,0X81,0X18,0X81,
0X18,0X81,0X20,0X81,0X20,0XA1,0X20,0XA1,0X20,0XA1,0X20,0XA1,0X20,0XA1,0X20,0XA1,
0X18,0X81,0X18,0X60,0X10,0X60,0X10,0XA1,0X10,0X80,0X18,0XA1,0X10,0XA1,0X18,0X81,
0X18,0X60,0X18,0X40,0X10,0X40,0X18,0X61,0X18,0X81,0X20,0XC1,0X20,0XA1,0X20,0XA1,
0X20,0XA1,0X20,0XC1,0X18,0X81,0X18,0X81,0X18,0X80,0X10,0X60,0X10,0X61,0X10,0X80,
0X31,0X23,0X28,0XE2,0X28,0XE2,0X28,0XE2,0X28,0XC2,0X20,0XC2,0X28,0XE2,0X28,0XE2,
0X20,0XE2,0X20,0XC2,0X20,0XC1,0X20,0XC2,0X18,0XA2,0X20,0XC2,0X20,0XC2,0X20,0XC2,
0X28,0XC3,0X28,0XE3,0X28,0XE3,0X28,0XE3,0X28,0XE2,0X28,0XC2,0X20,0XA1,0X20,0XA2,
0X20,0XC2,0X20,0XC2,0X20,0XA1,0X20,0XA1,0X20,0XC2,0X20,0XA2,0X20,0XA2,0X20,0XA1,
0X28,0XC2,0X28,0XE1,0X31,0X03,0X41,0X84,0XBD,0X32,0XE6,0XB5,0XEE,0XD5,0XE6,0X95,
0XE6,0X94,0XEE,0X94,0XEE,0X94,0XEE,0X74,0XEE,0X95,0XF6,0XB5,0XF6,0XB5,0XF6,0XB5,
0XEE,0X95,0XEE,0X74,0XEE,0X74,0XEE,0X94,0XD5,0XD2,0XCD,0X91,0XDD,0XF2,0XBD,0X0F,
0XDD,0XF2,0XDD,0XF2,0XCD,0X70,0XB4,0XAD,0XC5,0X2F,0XE6,0X33,0XE6,0X34,0XDD,0XF3,
0XB4,0XAE,0XC5,0X30,0XD5,0XB1,0XDE,0X13,0XE6,0X54,0XE6,0X33,0XE6,0X53,0XE6,0X53,
0XE6,0X53,0XE6,0X74,0XE6,0X53,0XE6,0X53,0XE6,0X53,0XD5,0XF2,0XC5,0X70,0XC5,0X50,
0XB4,0XCF,0XB4,0XCF,0XC5,0X50,0XD6,0X13,0XC5,0X71,0XD5,0XF3,0XD6,0X13,0XBD,0X71,
0X52,0X25,0X28,0XE1,0X20,0XA1,0X18,0X80,0X18,0X80,0X18,0X80,0X18,0X81,0X18,0X81,
0X18,0X81,0X20,0XA1,0X20,0XA1,0X20,0XA1,0X20,0XA1,0X20,0XA1,0X20,0XA1,0X20,0XC1,
0X18,0X81,0X18,0X60,0X10,0X80,0X10,0XA0,0X10,0X80,0X10,0XA0,0X10,0XA0,0X10,0X80,
0X10,0X60,0X10,0X40,0X10,0X40,0X10,0X61,0X18,0XA2,0X20,0XA2,0X18,0XA2,0X18,0XA1,
0X18,0XA1,0X18,0XA1,0X18,0XA1,0X18,0XA1,0X10,0X60,0X10,0X60,0X10,0X80,0X10,0X80,
0X31,0X23,0X28,0XE2,0X28,0XE2,0X28,0XE2,0X28,0XE2,0X28,0XC2,0X28,0XE2,0X28,0XC2,
0X20,0XE2,0X20,0XC2,0X20,0XC2,0X20,0XC2,0X20,0XC2,0X20,0XE3,0X20,0XC2,0X20,0XC2,
0X28,0XC2,0X20,0XC2,0X20,0XA2,0X28,0XE3,0X28,0XE2,0X28,0XC2,0X20,0XA1,0X20,0XA1,
0X20,0XA1,0X20,0XC2,0X20,0XC2,0X20,0XC2,0X20,0XC2,0X20,0XC2,0X20,0XA2,0X20,0XA1,
0X28,0XC2,0X31,0X23,0X39,0X23,0XCD,0XF4,0XEE,0XB6,0XEE,0XB5,0XE6,0X94,0XE6,0X94,
0XEE,0X94,0XEE,0X94,0XEE,0X94,0XF6,0XB5,0XF6,0XB5,0XF6,0XB5,0XF6,0XB5,0XEE,0X95,
0XEE,0X95,0XF6,0XB5,0XD5,0XB1,0XC5,0X50,0XDE,0X12,0XE6,0X54,0XE6,0X33,0XE6,0X33,
0XCD,0X91,0XBD,0X0F,0XDE,0X13,0XC5,0X2F,0XD5,0X91,0XDD,0XF3,0XBD,0X10,0XC5,0X30,
0XDD,0XF3,0XDD,0XF2,0XE6,0X33,0XE6,0X33,0XE6,0X54,0XE6,0X54,0XE6,0X54,0XEE,0X74,
0XEE,0X74,0XEE,0X74,0XE6,0X74,0XE6,0X53,0XE6,0X74,0XE6,0X74,0XE6,0X74,0XD5,0XD2,
0XCD,0X92,0XDE,0X14,0XDE,0X34,0XBD,0X0F,0XCD,0XB1,0XD6,0X33,0XD6,0X13,0XCD,0XF3,
0XC5,0XB3,0X5A,0X67,0X28,0XE2,0X20,0X81,0X18,0X60,0X18,0X61,0X18,0X61,0X18,0X81,
0X18,0XA1,0X20,0XA1,0X20,0XA1,0X20,0XA1,0X20,0XA1,0X20,0XA1,0X20,0X81,0X18,0XA1,
0X18,0X60,0X18,0X60,0X18,0X60,0X10,0X80,0X18,0XA1,0X10,0X80,0X10,0X80,0X10,0X80,
0X10,0X60,0X10,0X60,0X10,0X40,0X10,0X61,0X18,0X81,0X18,0XA2,0X18,0XA2,0X18,0XA1,
0X18,0XA1,0X18,0XA1,0X18,0XA1,0X18,0X81,0X10,0X60,0X08,0X40,0X10,0X80,0X10,0X80,
0X31,0X03,0X29,0X02,0X28,0XE2,0X28,0XE2,0X28,0XE2,0X28,0XE2,0X20,0XC2,0X20,0XC2,
0X20,0XA1,0X20,0XA1,0X20,0XC1,0X20,0XC1,0X20,0XA2,0X18,0XA2,0X20,0XA2,0X28,0XC2,
0X28,0XC2,0X20,0XA2,0X20,0XA2,0X28,0XE3,0X28,0XE3,0X28,0XC2,0X20,0X81,0X28,0XC2,
0X20,0XA1,0X20,0XC2,0X20,0XA1,0X20,0XC2,0X20,0XC2,0X28,0XC2,0X20,0XC2,0X20,0X81,
0X28,0XA1,0X39,0X23,0XB4,0XF1,0XE6,0X95,0XE6,0X94,0XE6,0X54,0XE6,0X74,0XE6,0X74,
0XE6,0X74,0XEE,0X95,0XEE,0X95,0XEE,0X95,0XEE,0X94,0XEE,0X95,0XEE,0X74,0XEE,0X95,
0XD5,0XD2,0XBD,0X0F,0XD5,0XB2,0XEE,0X54,0XEE,0X74,0XEE,0X74,0XEE,0X74,0XF6,0XB5,
0XEE,0X95,0XEE,0X74,0XCD,0X91,0XDD,0XF2,0XCD,0X70,0XAC,0X8D,0XB4,0XAE,0XE6,0X14,
0XDE,0X13,0XDD,0XF3,0XE6,0X13,0XE6,0X33,0XE6,0X54,0XE6,0X54,0XE6,0X74,0XEE,0X74,
0XEE,0X74,0XEE,0X74,0XEE,0X94,0XE6,0X74,0XE6,0X53,0XE6,0X53,0XDE,0X13,0XCD,0XB1,
0XE6,0X34,0XE6,0X74,0XE6,0X54,0XDE,0X34,0XDE,0X13,0XD5,0XF3,0XCD,0XB2,0XCD,0XB2,
0XCD,0XD3,0XC5,0X92,0X52,0X26,0X31,0X22,0X18,0X40,0X18,0X81,0X18,0X81,0X18,0X81,
0X20,0XA1,0X20,0XA1,0X20,0XA1,0X20,0XA1,0X20,0XA1,0X20,0XA1,0X20,0XA1,0X20,0XA1,
0X18,0X81,0X18,0X60,0X10,0X60,0X18,0XA1,0X18,0X80,0X18,0X80,0X18,0X80,0X10,0X80,
0X18,0X80,0X10,0X60,0X10,0X20,0X10,0X40,0X18,0X81,0X20,0XA2,0X18,0XA2,0X18,0XA1,
0X18,0X81,0X18,0XA1,0X18,0X81,0X10,0X60,0X10,0X80,0X10,0X80,0X10,0X80,0X08,0X40,
0X31,0X03,0X29,0X02,0X28,0XE2,0X20,0XC2,0X28,0XC2,0X28,0XE2,0X28,0XC2,0X20,0XC2,
0X20,0XA1,0X18,0XA1,0X20,0XA1,0X20,0XA1,0X18,0XA2,0X20,0XC2,0X20,0XA2,0X20,0XC2,
0X20,0XA2,0X20,0XA2,0X28,0XC2,0X28,0XE3,0X28,0XE3,0X28,0XE2,0X20,0XA1,0X20,0XA1,
0X20,0XA2,0X20,0XC2,0X20,0XA1,0X20,0XC2,0X20,0XC2,0X28,0XC2,0X28,0XC2,0X30,0XE2,
0X31,0X23,0XAC,0XD1,0XCD,0XB2,0XCD,0XF2,0XCD,0XB1,0XBD,0X2F,0XDE,0X13,0XE6,0X74,
0XEE,0XB5,0XEE,0X95,0XEE,0X94,0XEE,0X94,0XEE,0X94,0XEE,0X74,0XE6,0X33,0XD5,0XB1,
0XBD,0X0F,0XE6,0X13,0XE6,0X13,0XEE,0X54,0XEE,0X75,0XEE,0X95,0XEE,0X95,0XF6,0XB5,
0XEE,0X95,0XEE,0X54,0XE6,0X33,0XCD,0X70,0XDD,0XD2,0XDD,0XF2,0XE6,0X14,0XBC,0XEF,
0XD5,0XB2,0XDD,0XF3,0XE6,0X13,0XE6,0X33,0XDD,0XF2,0XDE,0X13,0XE6,0X33,0XE6,0X54,
0XE6,0X54,0XE6,0X53,0XE6,0X53,0XDE,0X33,0XDE,0X12,0XD5,0XF2,0XDE,0X13,0XDE,0X33,
0XE6,0X54,0XE6,0X53,0XE6,0X34,0XE6,0X33,0XE6,0X54,0XDE,0X33,0XDE,0X13,0XD5,0XF3,
0XBD,0X50,0XCD,0XD2,0XC5,0XB3,0X83,0X8A,0X28,0XE1,0X18,0X60,0X18,0X60,0X18,0X81,
0X20,0XA1,0X20,0XA1,0X20,0X81,0X20,0X81,0X28,0XA1,0X20,0XA1,0X20,0X81,0X20,0XA1,
0X20,0XA1,0X18,0X60,0X18,0X40,0X18,0X80,0X10,0X60,0X10,0X60,0X10,0X60,0X10,0X60,
0X10,0X60,0X10,0X40,0X10,0X20,0X10,0X20,0X18,0X81,0X18,0XA2,0X18,0X81,0X18,0X81,
0X18,0X81,0X18,0X81,0X18,0X81,0X10,0X60,0X10,0X80,0X10,0X80,0X08,0X60,0X08,0X60,
0X31,0X03,0X29,0X02,0X20,0XC2,0X20,0XA1,0X20,0XA2,0X28,0XC3,0X28,0XC2,0X20,0XC2,
0X20,0XC2,0X20,0XC1,0X18,0XC2,0X18,0XA2,0X18,0XA1,0X20,0XA1,0X20,0XA1,0X20,0XC2,
0X20,0XC1,0X20,0XC1,0X28,0XC2,0X28,0XE2,0X28,0XE2,0X28,0XE2,0X20,0XA1,0X20,0XA2,
0X20,0XA1,0X20,0XA2,0X28,0XC2,0X28,0XC3,0X20,0XA2,0X20,0XC2,0X28,0XE2,0X39,0X63,
0XAC,0XD0,0XDE,0X34,0XDE,0X54,0XE6,0X94,0XE6,0X74,0XDE,0X53,0XCD,0XB1,0XBD,0X0F,
0XDD,0XF2,0XEE,0X74,0XEE,0X95,0XEE,0X74,0XE6,0X54,0XE6,0X74,0XC5,0X2F,0XC5,0X50,
0XE6,0X13,0XEE,0X54,0XE6,0X34,0XE6,0X33,0XE6,0X33,0XE6,0X33,0XE6,0X33,0XE6,0X33,
0XE6,0X33,0XE6,0X53,0XE6,0X53,0XE6,0X33,0XE6,0X33,0XE6,0X33,0XD5,0X91,0XCD,0X50,
0XE6,0X13,0XCD,0X50,0XC5,0X2F,0XD5,0XB1,0XE6,0X33,0XE6,0X33,0XDE,0X33,0XDE,0X53,
0XE6,0X53,0XE6,0X53,0XDE,0X53,0XDE,0X53,0XDE,0X54,0XDE,0X33,0XCD,0X91,0XCD,0X91,
0XE6,0X54,0XDE,0X33,0XDE,0X53,0XDE,0X33,0XDE,0X33,0XDE,0X13,0XDD,0XF3,0XDD,0XF3,
0XDD,0XF3,0XC5,0X51,0XC5,0X71,0XC5,0XB2,0X73,0X29,0X20,0XC0,0X18,0X40,0X20,0XA1,
0X20,0XA1,0X20,0XA1,0X20,0X81,0X20,0X81,0X20,0X81,0X20,0X81,0X18,0X80,0X20,0XA1,
0X20,0XA1,0X18,0X60,0X10,0X40,0X18,0X80,0X18,0X60,0X18,0X60,0X10,0X60,0X10,0X40,
0X10,0X40,0X10,0X40,0X10,0X20,0X10,0X40,0X18,0X81,0X18,0XA2,0X18,0X81,0X18,0XA1,
0X18,0X81,0X18,0X81,0X18,0X81,0X18,0X80,0X10,0X80,0X10,0X80,0X08,0X60,0X10,0X60,
0X29,0X02,0X28,0XE2,0X20,0XC2,0X20,0XA1,0X28,0XC3,0X28,0XC3,0X20,0XA2,0X20,0XA1,
0X20,0XA1,0X18,0XA1,0X18,0XC2,0X18,0XA2,0X18,0X81,0X18,0XA1,0X20,0XA1,0X20,0XA2,
0X20,0XC2,0X20,0XC1,0X28,0XC2,0X28,0XE2,0X28,0XE2,0X28,0XC2,0X28,0XC2,0X20,0XA1,
0X20,0XA1,0X20,0XA1,0X20,0XC2,0X28,0XE3,0X20,0XA2,0X28,0XE3,0X39,0X43,0X6A,0XE8,
0XD6,0X13,0XE6,0X75,0XE6,0X95,0XE6,0X74,0XE6,0X73,0XE6,0X94,0XE6,0X74,0XDE,0X33,
0XCD,0X70,0XBC,0XEE,0XE6,0X33,0XE6,0X33,0XDE,0X13,0XBD,0X2F,0XC5,0X50,0XE6,0X33,
0XE6,0X34,0XEE,0X54,0XE6,0X33,0XE6,0X33,0XE6,0X33,0XE6,0X33,0XE6,0X33,0XDE,0X12,
0XE6,0X33,0XE6,0X33,0XE6,0X54,0XE6,0X33,0XE6,0X33,0XDE,0X13,0XDD,0XD2,0XCD,0X71,
0X9B,0XCA,0XBC,0XEF,0XDD,0XF2,0XDE,0X13,0XDD,0XF2,0XDD,0XF2,0XDD,0XF2,0XDE,0X13,
0XDE,0X13,0XDE,0X13,0XD6,0X12,0XD6,0X12,0XDE,0X13,0XD6,0X12,0XD5,0XF2,0XD5,0XD2,
0XBC,0XEE,0XDE,0X12,0XD6,0X12,0XD5,0XF2,0XD5,0XF2,0XD5,0XD2,0XD5,0XD2,0XD5,0XF3,
0XD5,0XF3,0XCD,0XB2,0XB4,0XEF,0XAC,0XEF,0XB5,0X11,0X6A,0XE9,0X20,0X81,0X20,0XA1,
0X20,0XA1,0X20,0XA1,0X20,0X61,0X20,0X61,0X18,0X60,0X18,0X81,0X18,0X81,0X20,0XA1,
0X18,0X81,0X18,0X60,0X10,0X40,0X18,0X60,0X10,0X60,0X10,0X60,0X10,0X60,0X10,0X40,
0X10,0X40,0X10,0X60,0X10,0X20,0X08,0X20,0X18,0X81,0X18,0XA2,0X18,0X81,0X10,0X81,
0X18,0X81,0X18,0X81,0X18,0X81,0X18,0X81,0X10,0X60,0X10,0X60,0X08,0X60,0X10,0X60,
0X31,0X03,0X28,0XC2,0X20,0XC2,0X20,0XC2,0X28,0XC2,0X28,0XC2,0X20,0XA1,0X20,0XA1,
0X20,0XA1,0X18,0XA1,0X18,0XA1,0X18,0XA2,0X18,0XA1,0X18,0XA1,0X20,0XA1,0X20,0XA1,
0X20,0XA1,0X28,0XC2,0X28,0XC2,0X28,0XE2,0X28,0XE2,0X28,0XE2,0X28,0XC2,0X20,0XA2,
0X20,0XA1,0X20,0XA1,0X20,0XC2,0X28,0XE3,0X28,0XC3,0X31,0X24,0X62,0X67,0XDE,0X75,
0XE6,0X94,0XE6,0X74,0XE6,0X94,0XE6,0X74,0XE6,0X74,0XEE,0X74,0XE6,0X74,0XE6,0X54,
0XEE,0X54,0XE6,0X33,0XC5,0X2F,0XC5,0X2F,0XB4,0XAD,0XCD,0XB1,0XE6,0X33,0XE6,0X33,
0XE6,0X34,0XEE,0X54,0XE6,0X54,0XE6,0X54,0XE6,0X54,0XE6,0X53,0XE6,0X53,0XE6,0X53,
0XEE,0X94,0XEE,0X54,0XE6,0X53,0XE6,0X13,0XDD,0XF2,0XD5,0XB1,0XBC,0XEE,0XAC,0X6D,
0XCD,0X70,0XA4,0X0B,0XDD,0XF2,0XD5,0XD2,0XD5,0XB1,0XCD,0X91,0XCD,0X91,0XD5,0XB1,
0XD5,0XB1,0XD5,0XB1,0XCD,0XB1,0XCD,0XB1,0XD5,0XD1,0XD5,0XD1,0XD5,0XD2,0XD5,0XD2,
0XCD,0X91,0XB4,0XCD,0XCD,0X90,0XCD,0XB1,0XCD,0XB1,0XD5,0XD2,0XD5,0XF2,0XDE,0X13,
0XD5,0XD2,0XB4,0XAE,0X9C,0X2C,0X93,0XEB,0X94,0X0C,0XA4,0X8F,0X41,0X85,0X39,0X23,
0X20,0XA1,0X20,0XA1,0X20,0XA1,0X20,0X81,0X18,0X81,0X18,0X80,0X18,0X80,0X18,0X81,
0X20,0X81,0X18,0X81,0X10,0X40,0X10,0X60,0X10,0X60,0X10,0X60,0X10,0X60,0X10,0X60,
0X10,0X60,0X10,0X40,0X08,0X20,0X08,0X20,0X18,0X81,0X18,0XA2,0X18,0X81,0X18,0XA1,
0X18,0XA1,0X18,0X81,0X18,0X81,0X10,0X60,0X10,0X60,0X10,0X60,0X10,0X60,0X10,0X60,
0X31,0X23,0X28,0XE2,0X28,0XC2,0X28,0XC2,0X28,0XE2,0X20,0XC2,0X20,0XA1,0X20,0X81,
0X20,0XA1,0X18,0XA1,0X18,0XA1,0X18,0XA2,0X18,0XA1,0X18,0X81,0X20,0XA1,0X20,0XA1,
0X20,0XA1,0X20,0XC1,0X28,0XE2,0X28,0XE2,0X28,0XE2,0X28,0XE2,0X28,0XC2,0X20,0XA1,
0X20,0XA1,0X20,0XA1,0X20,0XC2,0X28,0XC2,0X28,0XE3,0X39,0X23,0XCD,0XF4,0XD6,0X13,
0XE6,0XB4,0XE6,0X74,0XE6,0X53,0XE6,0X53,0XE6,0X54,0XE6,0X54,0XE6,0X54,0XE6,0X54,
0XEE,0X34,0XE6,0X54,0XCD,0X70,0XC5,0X2F,0XB4,0XCE,0XD5,0XB1,0XE6,0X33,0XE6,0X33,
0XEE,0X54,0XEE,0X54,0XEE,0X54,0XEE,0X74,0XEE,0X74,0XEE,0X74,0XEE,0X74,0XEE,0X94,
0XF6,0XB5,0XEE,0X74,0XE6,0X54,0XDD,0XF2,0XC5,0X4F,0X9B,0XEA,0XBC,0XEE,0XCD,0X50,
0XCD,0X70,0XBC,0XCE,0X93,0XCA,0XCD,0X50,0XC5,0X50,0XC5,0X50,0XCD,0X70,0XCD,0X91,
0XCD,0X91,0XD5,0XB1,0XCD,0XB1,0XCD,0XB1,0XD5,0XB1,0XD5,0XB1,0XD5,0XB1,0XD5,0XB1,
0XCD,0XB1,0XCD,0X90,0XA4,0X8C,0XD5,0XD1,0XD5,0XF2,0XCD,0XB2,0XAC,0XAD,0XB4,0XEE,
0XC5,0X70,0XCD,0XB1,0XC5,0X71,0XBD,0X30,0XA4,0X8E,0XA4,0X6F,0X49,0XC5,0X20,0XA1,
0X20,0XA1,0X20,0XA1,0X20,0XA1,0X20,0X81,0X20,0XA1,0X18,0X80,0X18,0X80,0X18,0X81,
0X20,0X81,0X18,0X81,0X10,0X60,0X10,0X60,0X10,0X60,0X10,0X80,0X10,0X60,0X10,0X40,
0X10,0X40,0X10,0X40,0X08,0X20,0X08,0X20,0X10,0X61,0X18,0X81,0X18,0X81,0X18,0X81,
0X18,0X81,0X18,0X81,0X18,0X81,0X18,0X81,0X10,0X61,0X10,0X60,0X10,0X61,0X10,0X80,
0X31,0X03,0X28,0XC2,0X28,0XC2,0X28,0XC2,0X28,0XE2,0X20,0XC1,0X20,0XA1,0X20,0XA1,
0X20,0XC1,0X18,0X81,0X18,0XA1,0X18,0XC1,0X18,0XA1,0X18,0X81,0X18,0XA1,0X20,0XA1,
0X20,0X81,0X20,0XC1,0X28,0XE2,0X28,0XC2,0X28,0XC2,0X28,0XE2,0X28,0XC2,0X20,0XA1,
0X20,0XA1,0X20,0XA1,0X20,0XA2,0X28,0XC2,0X31,0X04,0X62,0X88,0XCD,0XD3,0XE6,0X74,
0XE6,0X94,0XE6,0X74,0XE6,0X53,0XE6,0X33,0XE6,0X53,0XE6,0X33,0XE6,0X53,0XEE,0X74,
0XEE,0X94,0XDD,0XF2,0XDD,0XF2,0XE6,0X33,0XE6,0X33,0XBC,0XEE,0XDD,0XD2,0XEE,0X54,
0XEE,0X54,0XEE,0X74,0XEE,0X74,0XF6,0XB5,0XF6,0X95,0XF6,0X94,0XF6,0XD5,0XF6,0XB5,
0XF6,0XB5,0XEE,0X94,0XEE,0X74,0XC5,0X50,0XAC,0X6D,0XBC,0XCE,0XC5,0X10,0XC4,0XEF,
0XC4,0XEF,0XBC,0XCF,0XA4,0X2B,0X9C,0X0B,0XC5,0X2F,0XC5,0X50,0XC5,0X50,0XD5,0X91,
0XD5,0X91,0XDD,0XB2,0XDD,0XD2,0XDD,0XD2,0XDD,0XD2,0XDD,0XF3,0XDD,0XF2,0XD5,0XD2,
0XD5,0XB1,0XD5,0XB1,0XC5,0X70,0XAC,0X8D,0XBD,0X0F,0XB4,0XEF,0XDD,0XF2,0XDD,0XF3,
0XDE,0X13,0XDE,0X13,0XD5,0XD2,0XCD,0X71,0XC5,0X51,0XA4,0X6E,0X5A,0X67,0X28,0XE2,
0X20,0XA1,0X20,0X81,0X20,0XA1,0X18,0X81,0X18,0X81,0X18,0X81,0X20,0X81,0X18,0X81,
0X18,0X81,0X18,0X81,0X18,0X81,0X10,0X60,0X10,0X80,0X10,0X80,0X10,0X80,0X10,0X40,
0X10,0X40,0X10,0X40,0X10,0X40,0X08,0X20,0X10,0X41,0X18,0XA1,0X18,0X81,0X18,0X81,
0X18,0X61,0X18,0X61,0X18,0X81,0X18,0X61,0X10,0X41,0X10,0X61,0X10,0X61,0X10,0X81,
0X29,0X03,0X20,0XA2,0X20,0XA2,0X20,0XC2,0X20,0XC1,0X20,0XC1,0X20,0XA1,0X20,0XA1,
0X20,0XA1,0X18,0XA1,0X18,0XA1,0X18,0XA1,0X18,0XA1,0X18,0XA1,0X20,0XC1,0X20,0XC1,
0X20,0XC2,0X28,0XC2,0X28,0XE2,0X28,0XC2,0X28,0XC2,0X28,0XE2,0X28,0XC2,0X20,0XC1,
0X20,0XA1,0X20,0XA1,0X20,0XA1,0X20,0XA1,0X31,0X03,0XB5,0X11,0XDE,0X34,0XE6,0X74,
0XE6,0X53,0XDE,0X13,0XE6,0X53,0XE6,0X33,0XE6,0X53,0XE6,0X33,0XE6,0X33,0XEE,0X74,
0XDD,0XF2,0XD5,0XD2,0XEE,0X74,0XEE,0X95,0XEE,0X74,0XE6,0X54,0XDD,0XF2,0XBC,0XEE,
0XE6,0X33,0XEE,0X74,0XEE,0X94,0XEE,0X95,0XF6,0XB5,0XF6,0XB5,0XEE,0X94,0XF6,0XB5,
0XF6,0X95,0XCD,0X70,0XA4,0X4B,0XCD,0X91,0XC5,0X50,0XC5,0X30,0XC5,0X2F,0XC5,0X2F,
0XC5,0X2F,0XD5,0XB1,0XCD,0X70,0XCD,0X70,0XBC,0XCE,0XD5,0XB1,0XDE,0X13,0XDD,0XF2,
0XE6,0X13,0XE6,0X13,0XE6,0X13,0XE6,0X34,0XE6,0X34,0XE6,0X34,0XE6,0X33,0XDE,0X13,
0XD5,0XB1,0XD5,0XB1,0XC5,0X50,0XC5,0X50,0XCD,0X71,0XBD,0X30,0XDD,0XF3,0XE6,0X33,
0XDD,0XF2,0XD5,0XF2,0XD5,0XD2,0XCD,0X92,0XC5,0X71,0XAC,0XCF,0XA4,0X8F,0X28,0XC1,
0X28,0XA1,0X20,0XA1,0X18,0X81,0X18,0X60,0X18,0X81,0X20,0X81,0X20,0X81,0X18,0X81,
0X20,0XA1,0X18,0X81,0X18,0X81,0X10,0X60,0X10,0X80,0X10,0X80,0X10,0X80,0X10,0X60,
0X10,0X40,0X10,0X40,0X10,0X40,0X10,0X20,0X18,0X61,0X18,0X81,0X18,0XA1,0X18,0X81,
0X18,0X61,0X18,0X81,0X18,0X81,0X18,0X81,0X10,0X41,0X10,0X41,0X10,0X61,0X10,0X61,
0X20,0XC2,0X20,0XC1,0X20,0XA1,0X20,0XC2,0X20,0XA1,0X20,0XA1,0X20,0XC2,0X20,0XA1,
0X18,0XA1,0X18,0XA1,0X18,0XA1,0X10,0XA1,0X18,0XA1,0X18,0X81,0X20,0XA1,0X18,0X81,
0X20,0XC1,0X20,0XC1,0X28,0XE2,0X28,0XC2,0X28,0XC2,0X28,0XE2,0X20,0XC2,0X20,0XA1,
0X20,0XA1,0X20,0XA2,0X20,0XC2,0X28,0XE2,0X28,0XE2,0XCD,0XD3,0XD6,0X13,0XDE,0X53,
0XDE,0X13,0XE6,0X33,0XE6,0X33,0XE6,0X53,0XE6,0X53,0XE6,0X53,0XE6,0X33,0XD5,0XB1,
0XDD,0XF2,0XEE,0X74,0XEE,0X74,0XEE,0X74,0XEE,0X74,0XEE,0X74,0XEE,0X74,0XEE,0X54,
0XE6,0X53,0XCD,0X70,0XCD,0X90,0XF6,0XB5,0XF6,0XB5,0XF6,0XB5,0XEE,0X54,0XE6,0X33,
0XA4,0X2C,0XC5,0X30,0XC5,0X50,0XCD,0X50,0XCD,0X70,0XCD,0X91,0XDD,0XD1,0XDE,0X12,
0XE6,0X33,0XE6,0X33,0XE6,0X33,0XE6,0X33,0XE6,0X54,0XE6,0X33,0XC5,0X50,0XDE,0X33,
0XE6,0X33,0XEE,0X95,0XEE,0X74,0XEE,0X75,0XEE,0X54,0XE6,0X33,0XC5,0X2F,0XC5,0X50,
0XDD,0XF2,0XE6,0X33,0XE6,0X33,0XE6,0X33,0XDE,0X13,0XDD,0XF3,0XC5,0X50,0XD5,0XB1,
0XDD,0XF2,0XCD,0XB1,0XD5,0XB2,0XD5,0XB2,0XC5,0X91,0XBD,0X30,0X9C,0X4D,0X41,0X83,
0X28,0XC2,0X20,0XA1,0X20,0X81,0X18,0X81,0X18,0X81,0X20,0XA1,0X18,0X81,0X20,0X81,
0X18,0X81,0X18,0X81,0X18,0X60,0X18,0X60,0X18,0X80,0X10,0X60,0X10,0X60,0X10,0X40,
0X18,0X81,0X10,0X40,0X10,0X20,0X08,0X20,0X10,0X41,0X18,0X81,0X18,0XA1,0X18,0X81,
0X18,0X81,0X18,0X81,0X18,0X81,0X18,0X61,0X10,0X61,0X10,0X61,0X10,0X61,0X10,0X61,
0X20,0XC2,0X20,0XA1,0X18,0XA1,0X20,0XC1,0X18,0XA1,0X18,0XA1,0X18,0XA1,0X18,0X81,
0X18,0X81,0X18,0X81,0X10,0X80,0X10,0XA1,0X18,0XC1,0X18,0XA1,0X20,0XC2,0X20,0XC1,
0X20,0XC1,0X20,0XC1,0X20,0XE2,0X28,0XC2,0X28,0XE2,0X28,0XC2,0X20,0XA1,0X20,0XA1,
0X20,0XA1,0X20,0XA2,0X20,0XC2,0X28,0XE1,0X41,0XA4,0XC5,0XB2,0XD6,0X13,0XDE,0X33,
0XDE,0X13,0XE6,0X33,0XE6,0X33,0XE6,0X53,0XE6,0X33,0XDE,0X12,0XDD,0XF2,0XDD,0XF2,
0XEE,0X74,0XEE,0X74,0XEE,0X74,0XEE,0X74,0XEE,0X74,0XEE,0X94,0XEE,0X94,0XF6,0XB5,
0XEE,0X94,0XEE,0X94,0XF6,0XB5,0XDE,0X12,0XC5,0X4F,0XE6,0X13,0XBC,0XEE,0XAC,0X4C,
0XC5,0X30,0XC5,0X50,0XC5,0X50,0XCD,0X71,0XD5,0XB1,0XDD,0XF2,0XE6,0X13,0XE6,0X34,
0XEE,0X54,0XEE,0X54,0XEE,0X54,0XEE,0X74,0XEE,0X74,0XE6,0X54,0XE6,0X74,0XCD,0XD1,
0XCD,0X91,0XDE,0X13,0XEE,0X54,0XE6,0X13,0XC5,0X2F,0XC5,0X0F,0XDD,0XF2,0XE6,0X33,
0XE6,0X33,0XE6,0X33,0XE6,0X54,0XE6,0X33,0XE6,0X13,0XDD,0XF3,0XDD,0XF2,0XCD,0X71,
0XCD,0X70,0XD5,0XB1,0XD5,0XB2,0XCD,0X91,0XBD,0X50,0XB5,0X0F,0X9C,0X0C,0X83,0X6A,
0X28,0XC1,0X20,0XC1,0X18,0X81,0X18,0X60,0X20,0X81,0X20,0X81,0X18,0X60,0X18,0X60,
0X20,0X81,0X18,0X81,0X18,0X81,0X18,0X60,0X18,0X60,0X10,0X40,0X10,0X40,0X10,0X40,
0X10,0X40,0X10,0X40,0X10,0X40,0X08,0X20,0X10,0X41,0X18,0X81,0X18,0XA1,0X18,0X81,
0X18,0XA2,0X18,0XA2,0X18,0X81,0X18,0X61,0X10,0X61,0X10,0X61,0X10,0X61,0X10,0X61,
0X20,0XC2,0X20,0XA1,0X18,0XA1,0X18,0XA1,0X18,0XA1,0X18,0XA1,0X18,0XA1,0X18,0X80,
0X18,0XA1,0X18,0XA1,0X10,0X80,0X10,0X80,0X18,0XA1,0X18,0XA1,0X18,0XA1,0X18,0XA1,
0X20,0XC1,0X20,0XC1,0X20,0XA1,0X20,0XC2,0X20,0XC2,0X20,0XA1,0X20,0XA1,0X28,0XA2,
0X20,0XA2,0X20,0XA1,0X20,0XA2,0X20,0XA1,0X31,0X22,0XCD,0XF3,0XD6,0X34,0XD6,0X13,
0XDE,0X13,0XE6,0X33,0XE6,0X33,0XE6,0X13,0XE6,0X33,0XDE,0X12,0XD5,0X91,0XEE,0X74,
0XEE,0X74,0XEE,0X74,0XEE,0X74,0XEE,0X74,0XEE,0X95,0XF6,0XB5,0XF6,0XB5,0XF6,0XB5,
0XF6,0XB5,0XEE,0X74,0XEE,0X74,0XE6,0X53,0XD5,0X91,0X93,0XA9,0XBC,0XEF,0XC5,0X10,
0XCD,0X71,0XCD,0X71,0XD5,0XB1,0XDD,0XF3,0XDD,0XF2,0XE6,0X33,0XE6,0X53,0XEE,0X54,
0XF6,0X94,0XF6,0X74,0XEE,0X74,0XF6,0X94,0XEE,0X94,0XEE,0X74,0XE6,0X74,0XE6,0X74,
0XE6,0X53,0XC5,0X2F,0XBD,0X0F,0XC5,0X0F,0XD5,0XB2,0XE6,0X33,0XE6,0X54,0XE6,0X33,
0XE6,0X54,0XE6,0X33,0XE6,0X13,0XE6,0X33,0XE6,0X13,0XE6,0X13,0XDD,0XF3,0XDD,0XF3,
0XD5,0XB2,0XBC,0XEE,0XC5,0X71,0XCD,0X71,0XBD,0X2F,0XB5,0X0E,0XB4,0XEE,0X94,0X0D,
0X28,0XC1,0X20,0XA1,0X18,0X81,0X18,0X41,0X18,0X61,0X18,0X81,0X18,0X61,0X18,0X60,
0X18,0X60,0X18,0X80,0X18,0X60,0X10,0X60,0X10,0X60,0X10,0X60,0X10,0X20,0X10,0X20,
0X18,0X61,0X10,0X61,0X10,0X40,0X08,0X00,0X10,0X40,0X18,0X61,0X18,0X81,0X18,0X81,
0X18,0XA2,0X18,0X81,0X18,0X81,0X18,0X61,0X10,0X61,0X10,0X61,0X10,0X61,0X10,0X40,
0X20,0XC1,0X18,0XA1,0X18,0XA1,0X18,0XA1,0X18,0XA1,0X18,0XA1,0X18,0XA1,0X18,0X81,
0X18,0XA1,0X18,0XC2,0X18,0XA1,0X18,0XA1,0X18,0XA1,0X18,0XA1,0X18,0XA1,0X18,0XA1,
0X18,0XC1,0X18,0XC1,0X20,0XC1,0X20,0XC1,0X20,0XC1,0X20,0XA1,0X20,0XA1,0X20,0XA1,
0X20,0XA1,0X20,0XA1,0X20,0X82,0X20,0XA1,0X31,0X43,0XB5,0X30,0XCD,0XF3,0XD5,0XF2,
0XD5,0XF2,0XE6,0X33,0XE6,0X33,0XDE,0X13,0XDD,0XF2,0XCD,0X70,0XEE,0X54,0XEE,0X74,
0XEE,0X74,0XEE,0X74,0XEE,0X74,0XEE,0X74,0XEE,0X95,0XEE,0X95,0XF6,0XB5,0XF6,0X95,
0XEE,0X94,0XE6,0X53,0XE6,0X54,0XBC,0XEE,0XB4,0XAD,0XBD,0X0F,0XAC,0X6C,0XC5,0X10,
0XD5,0X92,0XDD,0XD3,0XE6,0X54,0XEE,0X74,0XEE,0X94,0XEE,0X95,0XEE,0X74,0XEE,0X74,
0XF6,0X94,0XF6,0X74,0XF6,0X94,0XEE,0X74,0XEE,0X54,0XEE,0X74,0XE6,0X74,0XCD,0X70,
0XBD,0X2F,0XCD,0XB1,0XDE,0X13,0XDD,0XD2,0XD5,0X91,0XDD,0XD2,0XE6,0X54,0XE6,0X33,
0XE6,0X54,0XE6,0X33,0XE6,0X13,0XDD,0XF3,0XE6,0X13,0XDD,0XF3,0XDD,0XF3,0XDD,0XD2,
0XD5,0XB2,0XD5,0XB2,0XBC,0XEF,0XC5,0X51,0XBD,0X2F,0XB5,0X0F,0XB4,0XEF,0X93,0XEC,
0X49,0XA5,0X20,0XA1,0X18,0X40,0X18,0X40,0X18,0X81,0X18,0X81,0X18,0X81,0X18,0X81,
0X18,0X81,0X18,0X81,0X18,0X60,0X18,0X61,0X18,0X61,0X18,0X61,0X10,0X61,0X10,0X40,
0X10,0X61,0X10,0X61,0X10,0X40,0X10,0X20,0X18,0X61,0X18,0X61,0X18,0X81,0X18,0X81,
0X18,0X81,0X18,0X81,0X18,0X81,0X18,0X61,0X10,0X61,0X10,0X40,0X10,0X40,0X10,0X40,
0X20,0XA1,0X20,0XA1,0X18,0XA1,0X18,0XA1,0X18,0XA1,0X18,0XA1,0X18,0X81,0X18,0X81,
0X18,0X81,0X18,0XA2,0X18,0X81,0X18,0X81,0X18,0XA1,0X18,0XA2,0X18,0XA2,0X18,0XA1,
0X18,0XC1,0X18,0XC1,0X18,0XC1,0X20,0XC1,0X20,0XC1,0X20,0XA1,0X20,0XA1,0X20,0XA1,
0X20,0XA1,0X20,0XA1,0X18,0X81,0X20,0XA1,0X31,0X22,0XA4,0XCF,0XA4,0X8E,0XBD,0X50,
0XD6,0X13,0XDE,0X13,0XDD,0XF2,0XDE,0X13,0XC5,0X0F,0XE6,0X33,0XEE,0X74,0XEE,0X54,
0XEE,0X74,0XEE,0X74,0XEE,0X74,0XEE,0X74,0XEE,0X74,0XEE,0X94,0XF6,0XB5,0XEE,0X94,
0XE6,0X53,0XDE,0X12,0XC5,0X0F,0XD5,0XB1,0XD5,0XB1,0XDE,0X13,0XDD,0XF2,0XCD,0X91,
0XCD,0X50,0XEE,0X75,0XEE,0X74,0XEE,0X75,0XEE,0X95,0XEE,0X74,0XEE,0X74,0XEE,0X74,
0XF6,0X94,0XF6,0X74,0XF6,0X95,0XEE,0X75,0XE6,0X54,0XC5,0X30,0XC5,0X50,0XDE,0X13,
0XE6,0X54,0XE6,0X54,0XEE,0X74,0XE6,0X33,0XE6,0X54,0XD5,0X91,0XCD,0X70,0XE6,0X33,
0XE6,0X33,0XE6,0X54,0XE6,0X33,0XE6,0X33,0XE6,0X13,0XDE,0X13,0XDD,0XF3,0XD5,0XD2,
0XD5,0XD2,0XD5,0XD2,0XD5,0XD2,0XBC,0XEF,0XBD,0X30,0XBD,0X30,0XB5,0X0F,0XAC,0XCF,
0X83,0X8B,0X28,0XC1,0X18,0X41,0X10,0X40,0X18,0X81,0X18,0X81,0X18,0X81,0X18,0X61,
0X18,0X60,0X18,0X81,0X18,0X81,0X10,0X40,0X10,0X20,0X10,0X41,0X18,0X61,0X10,0X60,
0X18,0X61,0X18,0X60,0X10,0X40,0X08,0X20,0X10,0X40,0X18,0X61,0X18,0X81,0X18,0XA1,
0X18,0XA1,0X18,0X81,0X18,0X81,0X18,0X61,0X10,0X61,0X10,0X40,0X10,0X40,0X10,0X40,
0X20,0XA1,0X20,0XA1,0X18,0XA1,0X18,0XA1,0X18,0X82,0X18,0XA2,0X18,0X81,0X18,0X82,
0X18,0X82,0X20,0XA2,0X18,0X82,0X18,0X82,0X18,0X82,0X18,0X82,0X18,0XA2,0X18,0X82,
0X18,0XC1,0X18,0XC1,0X18,0XC1,0X20,0XC1,0X20,0XC1,0X20,0XA1,0X20,0XA1,0X20,0XA1,
0X20,0XA1,0X20,0XA1,0X20,0X82,0X20,0XA1,0X31,0X22,0XAC,0XF0,0XC5,0XB3,0XC5,0X71,
0XAC,0X8D,0XC5,0X50,0XE6,0X33,0XC5,0X50,0XD5,0X91,0XEE,0X54,0XE6,0X54,0XE6,0X54,
0XEE,0X54,0XEE,0X74,0XEE,0X74,0XEE,0X74,0XEE,0X74,0XEE,0X74,0XEE,0X74,0XE6,0X54,
0XBC,0XCE,0XCD,0X70,0XDE,0X12,0XE6,0X33,0XEE,0X54,0XEE,0X54,0XEE,0X74,0XE6,0X54,
0XE6,0X54,0XCD,0X71,0XCD,0X91,0XDD,0XF2,0XEE,0X54,0XEE,0X94,0XEE,0X74,0XEE,0X74,
0XF6,0X94,0XF6,0X75,0XEE,0X75,0XC5,0X30,0XCD,0X71,0XDE,0X13,0XE6,0X34,0XEE,0X75,
0XEE,0X75,0XEE,0X75,0XEE,0X74,0XEE,0X74,0XE6,0X54,0XE6,0X33,0XDE,0X13,0XCD,0X91,
0XD5,0XB1,0XDE,0X13,0XE6,0X33,0XDE,0X13,0XE6,0X33,0XE6,0X33,0XDE,0X13,0XDD,0XF2,
0XD5,0XD2,0XD5,0XD2,0XD5,0XD2,0XD5,0XD2,0XB4,0XEF,0XBD,0X31,0XBD,0X30,0XB4,0XEF,
0X9C,0X4E,0X31,0X23,0X18,0X61,0X18,0X61,0X18,0X61,0X18,0X81,0X18,0XA2,0X18,0X81,
0X18,0X61,0X18,0X61,0X18,0X61,0X10,0X40,0X10,0X60,0X18,0X61,0X18,0X81,0X10,0X60,
0X18,0X60,0X18,0X60,0X10,0X40,0X08,0X20,0X10,0X40,0X18,0X61,0X18,0X61,0X18,0X81,
0X18,0X81,0X18,0X81,0X18,0X81,0X18,0X61,0X10,0X61,0X10,0X61,0X18,0X61,0X10,0X61,
0X20,0XA1,0X20,0XC2,0X18,0XA1,0X20,0XC1,0X18,0X81,0X18,0X81,0X18,0X82,0X18,0X82,
0X18,0XA2,0X18,0XA2,0X18,0XC2,0X18,0XA2,0X18,0X81,0X18,0X81,0X18,0X81,0X18,0X81,
0X20,0XC1,0X20,0XC1,0X20,0XC2,0X20,0XC1,0X20,0XC1,0X20,0XC1,0X20,0XA1,0X18,0XA1,
0X20,0XA1,0X20,0XA1,0X20,0XA1,0X28,0XC2,0X41,0X84,0XBD,0X72,0XCD,0XD2,0XCD,0XD2,
0XD5,0XF3,0XD5,0XF3,0XAC,0X6D,0XA4,0X2C,0XDE,0X13,0XE6,0X34,0XE6,0X33,0XE6,0X54,
0XE6,0X53,0XE6,0X53,0XE6,0X33,0XE6,0X33,0XE6,0X54,0XEE,0X74,0XEE,0X54,0XBC,0XEE,
0XE6,0X33,0XE6,0X53,0XEE,0X53,0XEE,0X74,0XEE,0X74,0XEE,0X94,0XEE,0X94,0XF6,0XB5,
0XEE,0X95,0XEE,0X95,0XEE,0X95,0XEE,0X74,0XDD,0XD2,0XBC,0XEE,0XCD,0X91,0XE6,0X54,
0XEE,0X74,0XD5,0X91,0XCD,0X70,0XDD,0XF3,0XE6,0X34,0XEE,0X75,0XEE,0X75,0XEE,0X75,
0XEE,0X75,0XEE,0X95,0XEE,0X95,0XEE,0X74,0XEE,0X74,0XEE,0X74,0XE6,0X54,0XEE,0X54,
0XEE,0X34,0XE6,0X34,0XD5,0XB1,0XD5,0XD2,0XE6,0X33,0XE6,0X33,0XDE,0X13,0XDE,0X13,
0XD5,0XF2,0XD5,0XD2,0XD5,0XD2,0XD5,0XD2,0XD5,0XB2,0XA4,0X4D,0XAC,0X6D,0XB4,0XCF,
0XB4,0XD0,0X6A,0X89,0X20,0X61,0X18,0X60,0X18,0X81,0X18,0X81,0X18,0X81,0X18,0X61,
0X10,0X61,0X18,0X61,0X18,0X81,0X18,0X61,0X18,0X61,0X18,0X60,0X18,0X80,0X10,0X60,
0X18,0X60,0X18,0X60,0X10,0X20,0X08,0X00,0X10,0X40,0X10,0X61,0X18,0X81,0X18,0X81,
0X18,0X81,0X18,0X81,0X18,0X61,0X10,0X61,0X10,0X61,0X10,0X41,0X10,0X40,0X10,0X41,
0X20,0XC1,0X20,0XE2,0X20,0XC2,0X20,0XC1,0X18,0X81,0X18,0X81,0X18,0X81,0X18,0X81,
0X18,0XA2,0X18,0XA2,0X18,0XC2,0X18,0XA2,0X18,0X81,0X18,0X81,0X18,0X81,0X18,0X81,
0X20,0XA1,0X20,0XA1,0X18,0XA1,0X20,0XA1,0X20,0XC1,0X20,0XA1,0X20,0XA1,0X20,0XA1,
0X20,0XA1,0X20,0XA1,0X20,0XA1,0X28,0XE2,0X41,0XA4,0XC5,0XB3,0XCD,0XD2,0XD6,0X33,
0XDE,0X33,0XDE,0X34,0XAC,0X8D,0XCD,0X50,0XBC,0XEF,0XDD,0XD2,0XE6,0X34,0XE6,0X33,
0XE6,0X53,0XE6,0X53,0XE6,0X53,0XE6,0X53,0XE6,0X33,0XE6,0X33,0XBC,0XCE,0XDD,0XF2,
0XEE,0X54,0XEE,0X74,0XEE,0X74,0XEE,0X94,0XEE,0X94,0XF6,0X94,0XF6,0XB5,0XF6,0XB5,
0XF6,0XB5,0XEE,0X95,0XEE,0X95,0XEE,0X95,0XEE,0X74,0XE6,0X54,0XE6,0X54,0XC5,0X50,
0XAC,0X8D,0XDD,0XD2,0XEE,0X54,0XEE,0X74,0XEE,0X75,0XEE,0X75,0XEE,0X75,0XEE,0X95,
0XEE,0X95,0XEE,0XB5,0XEE,0XB5,0XF6,0XD5,0XEE,0XB5,0XEE,0XB5,0XEE,0X95,0XEE,0X95,
0XEE,0X75,0XEE,0X54,0XE6,0X33,0XE6,0X33,0XCD,0X91,0XDE,0X13,0XDE,0X13,0XDE,0X14,
0XDE,0X13,0XCD,0X92,0XB4,0XEE,0XB4,0XCE,0XC5,0X51,0XD5,0XD3,0XCD,0X72,0XB4,0XCE,
0X8B,0XAB,0X83,0X6B,0X28,0XE2,0X10,0X40,0X10,0X81,0X18,0X81,0X18,0X81,0X10,0X61,
0X10,0X61,0X10,0X61,0X18,0X61,0X18,0X61,0X18,0X61,0X10,0X60,0X10,0X60,0X10,0X60,
0X10,0X60,0X10,0X60,0X10,0X40,0X08,0X00,0X10,0X40,0X18,0X61,0X18,0X81,0X18,0X81,
0X18,0X61,0X18,0X61,0X18,0X61,0X10,0X61,0X10,0X61,0X10,0X41,0X10,0X41,0X10,0X41,
0X20,0XC2,0X20,0XE2,0X18,0XA1,0X20,0XC1,0X18,0XA1,0X18,0XA1,0X18,0XA2,0X18,0X81,
0X18,0XA1,0X18,0XA1,0X18,0XC2,0X18,0XA2,0X18,0X81,0X18,0X81,0X18,0X81,0X18,0X81,
0X18,0XA1,0X18,0XA1,0X18,0X81,0X20,0XA1,0X20,0XC1,0X20,0XA1,0X20,0XA1,0X20,0XA1,
0X20,0XA1,0X20,0XA1,0X20,0XA1,0X20,0XA1,0X49,0XC5,0XC5,0XB2,0XCD,0XD2,0XD6,0X12,
0XDE,0X33,0XD5,0XD2,0XC5,0X50,0XDD,0XF2,0XDD,0XF2,0XB4,0XCE,0XBD,0X0F,0XE6,0X33,
0XE6,0X53,0XE6,0X53,0XDE,0X12,0XDE,0X12,0XE6,0X33,0XDD,0XD2,0XD5,0X90,0XE6,0X33,
0XEE,0X54,0XEE,0X74,0XEE,0X74,0XEE,0X94,0XEE,0X94,0XEE,0X94,0XF6,0X94,0XF6,0XB5,
0XEE,0X94,0XEE,0X95,0XF6,0X95,0XF6,0X95,0XEE,0X95,0XEE,0X74,0XD5,0X91,0XD5,0XD2,
0XDE,0X13,0XD5,0X91,0XDE,0X13,0XDD,0XF3,0XE6,0X54,0XEE,0X96,0XEE,0X96,0XEE,0X95,
0XEE,0X95,0XEE,0X95,0XEE,0X95,0XEE,0XB5,0XEE,0X95,0XE6,0X74,0XE6,0X54,0XE6,0X34,
0XE6,0X54,0XEE,0X54,0XE6,0X34,0XBD,0X10,0XBC,0XCF,0XCD,0X92,0XC5,0X50,0XB4,0XAE,
0XBC,0XEF,0XBD,0X10,0XD5,0XB2,0XD5,0XD2,0XDD,0XF3,0XDD,0XF3,0XDD,0XD3,0XBD,0X30,
0XB4,0XF0,0XA4,0X8F,0X28,0XE2,0X18,0X80,0X18,0XA1,0X18,0XA1,0X18,0X81,0X10,0X61,
0X10,0X41,0X10,0X61,0X18,0X61,0X10,0X61,0X18,0X61,0X10,0X40,0X10,0X40,0X10,0X40,
0X10,0X60,0X10,0X60,0X10,0X40,0X08,0X00,0X10,0X40,0X18,0X61,0X18,0X61,0X18,0X81,
0X18,0X61,0X18,0X61,0X10,0X41,0X10,0X41,0X10,0X41,0X10,0X41,0X10,0X40,0X10,0X20,
0X20,0XC2,0X20,0XC2,0X20,0XA1,0X18,0XA1,0X18,0X81,0X18,0XA1,0X18,0XA1,0X18,0XA1,
0X18,0XA1,0X18,0XA1,0X18,0XA1,0X18,0X81,0X18,0X81,0X18,0X81,0X10,0X60,0X18,0X81,
0X20,0XA1,0X20,0XA1,0X18,0XA1,0X18,0XA1,0X18,0XA1,0X20,0XC1,0X20,0XC1,0X18,0XA1,
0X18,0X80,0X18,0X80,0X18,0XA1,0X20,0XC1,0X5A,0X88,0XCD,0XF3,0XD6,0X13,0XDE,0X53,
0XDE,0X54,0XBC,0XEF,0XD5,0XD2,0XE6,0X33,0XE6,0X33,0XE6,0X34,0XE6,0X13,0XC5,0X2F,
0XBD,0X0F,0XDD,0XD2,0XDE,0X12,0XDD,0XF2,0XDE,0X13,0XC5,0X0F,0XE6,0X33,0XEE,0X74,
0XEE,0X74,0XEE,0X74,0XEE,0X74,0XEE,0X74,0XEE,0X94,0XEE,0X94,0XEE,0X94,0XEE,0X74,
0XEE,0X94,0XEE,0X74,0XEE,0X95,0XEE,0X95,0XEE,0X95,0XD5,0XD2,0XEE,0X95,0XEE,0X95,
0XF6,0XB5,0XF6,0X95,0XEE,0X95,0XF6,0X96,0XE6,0X55,0XE6,0X55,0XD5,0XB3,0XE6,0X55,
0XDE,0X35,0XCD,0XD3,0XB5,0X10,0XA4,0X8D,0X9C,0X4C,0X9C,0X4D,0XAC,0X6E,0XA4,0X2D,
0X9C,0X0D,0X93,0X8B,0X93,0X8B,0X9B,0XCC,0XB4,0XCF,0XC5,0X31,0XC5,0X51,0XBD,0X10,
0XCD,0X92,0XD5,0XD3,0XDE,0X14,0XDE,0X34,0XDE,0X13,0XDD,0XF3,0XDD,0XD3,0XD5,0XF3,
0XBD,0X30,0XB4,0XF0,0X52,0X26,0X20,0XE1,0X10,0X80,0X10,0X80,0X18,0X81,0X10,0X41,
0X10,0X61,0X10,0X61,0X18,0X61,0X10,0X41,0X10,0X40,0X10,0X40,0X10,0X40,0X10,0X60,
0X10,0X60,0X10,0X60,0X10,0X40,0X08,0X00,0X10,0X20,0X18,0X61,0X18,0X61,0X18,0X61,
0X10,0X61,0X18,0X61,0X18,0X61,0X18,0X61,0X18,0X81,0X10,0X61,0X10,0X61,0X10,0X40,
0X20,0XC2,0X20,0XC2,0X20,0XC1,0X18,0XA1,0X10,0X81,0X18,0XA1,0X10,0X81,0X10,0X81,
0X18,0XA1,0X18,0XA2,0X18,0XC2,0X18,0X81,0X18,0X81,0X18,0X81,0X18,0X60,0X18,0XA1,
0X18,0X81,0X18,0X81,0X18,0X81,0X18,0XA1,0X18,0XA1,0X18,0XC1,0X18,0XC1,0X10,0XA0,
0X10,0X60,0X18,0X80,0X18,0X81,0X20,0XC1,0X62,0XC8,0XCD,0XD3,0XD6,0X33,0XDE,0X74,
0XBD,0X70,0XD5,0XF2,0XDD,0XF2,0XDE,0X13,0XE6,0X33,0XE6,0X34,0XE6,0X33,0XDD,0XF2,
0XD5,0XB1,0XBC,0XEE,0XC5,0X0F,0XDD,0XF2,0XBC,0XCE,0XE6,0X13,0XF6,0X94,0XEE,0X54,
0XEE,0X54,0XE6,0X54,0XE6,0X53,0XEE,0X74,0XEE,0X94,0XEE,0X74,0XEE,0X74,0XEE,0X74,
0XEE,0X94,0XEE,0X94,0XF6,0XB5,0XF6,0X95,0XCD,0X50,0XEE,0X95,0XF6,0XB5,0XF6,0XB5,
0XF6,0X95,0XEE,0X75,0XF6,0X96,0XE6,0X35,0XCD,0X72,0XC5,0X31,0XA4,0X2E,0X8B,0X8B,
0X8B,0XCC,0X49,0XA3,0X39,0X42,0X5A,0X66,0X5A,0X46,0X5A,0X46,0X72,0XC9,0X8B,0X6B,
0X8B,0X6B,0X93,0XAC,0X8B,0X6B,0X8B,0X8B,0X8B,0X8B,0X8B,0X4A,0X8B,0X6A,0X83,0X69,
0XBD,0X10,0XD5,0XB3,0XDE,0X14,0XDE,0X14,0XDE,0X14,0XDD,0XF3,0XDD,0XF3,0XDE,0X13,
0XCD,0X91,0XAC,0XAE,0X94,0X4E,0X20,0XE1,0X10,0X80,0X10,0X80,0X18,0X80,0X10,0X61,
0X10,0X61,0X10,0X61,0X18,0X61,0X10,0X61,0X10,0X40,0X18,0X60,0X18,0X60,0X10,0X60,
0X10,0X60,0X10,0X40,0X10,0X40,0X08,0X20,0X10,0X40,0X18,0X61,0X18,0X61,0X18,0X81,
0X10,0X40,0X18,0X61,0X18,0X61,0X10,0X60,0X18,0X81,0X10,0X40,0X10,0X40,0X18,0X61,
0X18,0XE2,0X10,0XA1,0X18,0XC1,0X18,0XC1,0X10,0XA0,0X18,0XA1,0X18,0XA1,0X18,0XA2,
0X18,0XA1,0X18,0XA1,0X18,0XA1,0X10,0X81,0X10,0X60,0X18,0X81,0X18,0X60,0X18,0X81,
0X18,0X81,0X18,0X82,0X18,0X81,0X18,0XA1,0X20,0XA1,0X18,0XA1,0X18,0XA1,0X10,0X60,
0X10,0X60,0X18,0X80,0X18,0XA1,0X20,0XC1,0X6A,0XE9,0XCD,0XD3,0XCE,0X12,0XD6,0X12,
0XC5,0X70,0XDE,0X13,0XE6,0X33,0XE6,0X33,0XEE,0X74,0XE6,0X54,0XE6,0X54,0XE6,0X33,
0XDE,0X13,0XDD,0XF2,0XD5,0XD2,0XB4,0XAD,0XBD,0X0F,0XDE,0X13,0XDE,0X13,0XE6,0X33,
0XE6,0X33,0XE6,0X53,0XE6,0X54,0XE6,0X53,0XEE,0X74,0XE6,0X53,0XEE,0X73,0XEE,0X73,
0XEE,0X73,0XEE,0X53,0XDD,0XD2,0XDD,0XF2,0XF6,0XB5,0XF6,0XD6,0XF6,0X75,0XE6,0X34,
0XE6,0X35,0XD5,0XB3,0X9B,0XCC,0X6A,0X87,0X51,0XE5,0X41,0X63,0X39,0X23,0X41,0X84,
0X49,0XC5,0X29,0X02,0X39,0X43,0X5A,0X67,0X62,0X88,0X49,0XE5,0X62,0X47,0X7B,0X0A,
0X93,0XCD,0X93,0XCD,0X8B,0X8C,0X7B,0X2A,0X7B,0X0A,0X7B,0X09,0X83,0X2A,0X83,0X2A,
0X7A,0XE9,0X9B,0XCC,0XC5,0X71,0XD5,0XD3,0XDE,0X13,0XE6,0X13,0XDE,0X13,0XDD,0XF2,
0XD5,0XF3,0XC5,0X71,0XAC,0XAF,0X49,0XE5,0X18,0X80,0X18,0X80,0X18,0XA1,0X18,0X61,
0X18,0X61,0X18,0X61,0X10,0X41,0X10,0X40,0X10,0X61,0X10,0X61,0X10,0X61,0X10,0X61,
0X10,0X61,0X10,0X61,0X10,0X40,0X08,0X20,0X08,0X20,0X10,0X41,0X10,0X61,0X10,0X41,
0X18,0X61,0X10,0X61,0X10,0X61,0X10,0X60,0X10,0X60,0X18,0X81,0X10,0X60,0X10,0X40,
0X18,0XE2,0X10,0X80,0X18,0XC1,0X10,0XA1,0X10,0XA1,0X18,0XC1,0X18,0XA1,0X18,0XA2,
0X18,0XA1,0X18,0XA1,0X10,0X60,0X10,0X60,0X10,0X60,0X18,0X81,0X18,0X60,0X18,0X81,
0X18,0XA2,0X18,0XA2,0X18,0XA2,0X18,0XA1,0X18,0XA1,0X18,0XA1,0X18,0XA1,0X18,0X80,
0X10,0X60,0X10,0X60,0X10,0X60,0X20,0XC1,0X6A,0XE9,0XCD,0XD3,0XD6,0X33,0XBD,0X70,
0XDE,0X33,0XD5,0XD2,0XE6,0X33,0XE6,0X54,0XE6,0X33,0XE6,0X33,0XE6,0X33,0XE6,0X33,
0XE6,0X33,0XE6,0X13,0XD5,0X91,0XDD,0XF2,0XE6,0X54,0XBD,0X0F,0XC5,0X2F,0XDE,0X13,
0XE6,0X33,0XE6,0X33,0XE6,0X33,0XE6,0X54,0XE6,0X53,0XEE,0X74,0XEE,0X94,0XEE,0X74,
0XEE,0X53,0XE6,0X32,0XF6,0XB5,0XE6,0X54,0XE6,0X33,0XD5,0X91,0XB4,0X8E,0X9B,0XEC,
0X83,0X2A,0X5A,0X05,0X31,0X02,0X41,0X84,0X39,0X84,0X20,0XC1,0X18,0XE2,0X29,0X03,
0X28,0XE2,0X41,0X85,0X62,0XAA,0X6A,0XEA,0X62,0X88,0X49,0XE6,0X5A,0X27,0X7B,0X6B,
0X9C,0X2F,0X9C,0X4F,0X94,0X0E,0X83,0X8C,0X8B,0XAC,0X83,0X6B,0X8B,0X8B,0X8B,0X6B,
0X83,0X6B,0X7B,0X2A,0X83,0X29,0X8B,0X8B,0XA4,0X2D,0XC5,0X11,0XD5,0XD3,0XDD,0XF4,
0XDE,0X34,0XCD,0XB2,0XAC,0X6F,0X8B,0XCC,0X18,0X80,0X10,0X80,0X18,0XA1,0X18,0X61,
0X10,0X61,0X18,0X61,0X10,0X61,0X10,0X61,0X18,0X61,0X10,0X61,0X10,0X61,0X10,0X61,
0X10,0X61,0X10,0X20,0X10,0X40,0X10,0X20,0X08,0X20,0X10,0X40,0X10,0X41,0X10,0X61,
0X18,0X61,0X10,0X60,0X10,0X40,0X10,0X60,0X10,0X40,0X10,0X61,0X10,0X40,0X10,0X61,
0X18,0XE2,0X10,0XA1,0X10,0XA1,0X10,0XA1,0X10,0X80,0X18,0XA1,0X18,0XC2,0X10,0X81,
0X18,0XA1,0X18,0XA1,0X10,0X80,0X10,0X80,0X18,0X80,0X18,0X80,0X18,0X80,0X18,0X81,
0X18,0X81,0X18,0X82,0X18,0XA2,0X18,0XA1,0X18,0X81,0X20,0XA1,0X18,0X60,0X20,0X81,
0X20,0XA1,0X18,0X80,0X18,0XA1,0X18,0X80,0X7B,0X4B,0XCD,0XF4,0XCD,0XF2,0XC5,0X90,
0XD5,0XF2,0XD5,0XD2,0XE6,0X33,0XE6,0X54,0XEE,0X95,0XE6,0X54,0XE6,0X33,0XE6,0X33,
0XE6,0X33,0XDE,0X13,0XC5,0X2F,0XEE,0X74,0XEE,0X74,0XDD,0XF2,0XDE,0X13,0XC5,0X2F,
0XCD,0X70,0XE6,0X53,0XE6,0X13,0XE6,0X54,0XE6,0X53,0XE6,0X53,0XE6,0X33,0XEE,0X74,
0XEE,0X94,0XE6,0X54,0XBC,0XEF,0XA4,0X2C,0X7A,0XE7,0X6A,0X86,0X72,0X87,0X7B,0X0A,
0X83,0X2B,0X72,0XEA,0X52,0X06,0X29,0X02,0X39,0XA4,0X39,0XC5,0X29,0X64,0X29,0X23,
0X4A,0X07,0X73,0X2C,0X83,0XAD,0X83,0XCD,0X73,0X4B,0X52,0X47,0X5A,0X68,0X8B,0XEE,
0X9C,0X90,0XA4,0XB0,0XA4,0XD1,0X9C,0X70,0X9C,0X70,0X6A,0XC9,0X83,0X8C,0X7B,0X4B,
0X83,0X6B,0X7B,0X2A,0X72,0XE9,0X7B,0X2A,0X83,0X2A,0X7A,0XC9,0X7A,0XC8,0X83,0X29,
0XAC,0X8E,0XC5,0X51,0XB4,0XF0,0X9C,0X4E,0X41,0XA4,0X18,0X81,0X18,0X81,0X18,0X60,
0X18,0X60,0X18,0X81,0X18,0X61,0X18,0X61,0X10,0X40,0X10,0X61,0X18,0X81,0X18,0X61,
0X18,0X61,0X10,0X40,0X10,0X40,0X10,0X20,0X08,0X20,0X10,0X40,0X10,0X61,0X10,0X60,
0X18,0X61,0X18,0X61,0X18,0X61,0X10,0X60,0X10,0X60,0X10,0X61,0X10,0X61,0X10,0X40,
0X18,0XE2,0X10,0XA1,0X10,0XA1,0X18,0XC1,0X10,0XA1,0X18,0XA1,0X10,0XA1,0X10,0X81,
0X10,0X81,0X18,0XA1,0X18,0XA1,0X18,0X81,0X18,0X80,0X18,0X80,0X18,0X80,0X18,0X81,
0X18,0X81,0X18,0X82,0X18,0XA2,0X18,0XA1,0X18,0X81,0X18,0X81,0X20,0XA1,0X20,0XA1,
0X20,0XA1,0X18,0XA1,0X10,0X60,0X20,0XA1,0X62,0X87,0XCD,0XF3,0XC5,0XB1,0XD5,0XF2,
0XD5,0XF2,0XD5,0XD2,0XDE,0X33,0XE6,0X54,0XEE,0X54,0XE6,0X54,0XE6,0X54,0XE6,0X33,
0XE6,0X13,0XC5,0X2F,0XE6,0X33,0XEE,0X74,0XEE,0X74,0XEE,0X74,0XEE,0X74,0XEE,0X95,
0XDE,0X13,0XC5,0X50,0XBD,0X0E,0XEE,0X74,0XE6,0X53,0XE6,0X53,0XE6,0X33,0XCD,0X91,
0XC5,0X30,0XA4,0X0C,0XA4,0X0C,0X93,0XAB,0X72,0XC8,0X62,0X46,0X6A,0X88,0X83,0X2B,
0X83,0X6C,0X7B,0X4B,0X62,0X68,0X62,0XA8,0X41,0XC5,0X5A,0XA8,0X39,0XA4,0X39,0X84,
0X8C,0X0E,0X9C,0X90,0XAC,0XF2,0X9C,0X90,0X83,0XED,0X83,0XCD,0X8C,0X2E,0X94,0X90,
0X9C,0X90,0X94,0X70,0X83,0XCE,0X8B,0XEE,0X7B,0X4C,0X8B,0XCE,0X94,0X4F,0X94,0X2F,
0X8B,0XCD,0X7B,0X4B,0X7B,0X0B,0X7B,0X0A,0X72,0XE9,0X72,0XC9,0X72,0X88,0X6A,0X66,
0X51,0XC4,0X51,0XE4,0X94,0X0C,0XA4,0XAF,0X6A,0XC9,0X28,0XE2,0X20,0XA1,0X18,0X80,
0X18,0X61,0X18,0X61,0X10,0X61,0X18,0X61,0X10,0X61,0X18,0X61,0X10,0X61,0X10,0X61,
0X10,0X61,0X10,0X40,0X08,0X20,0X08,0X00,0X08,0X00,0X10,0X40,0X10,0X61,0X10,0X60,
0X18,0X60,0X10,0X60,0X10,0X60,0X10,0X60,0X10,0X60,0X10,0X61,0X10,0X61,0X10,0X60,
0X21,0X02,0X10,0X80,0X10,0X80,0X10,0X80,0X10,0XA0,0X18,0XA1,0X10,0XA1,0X10,0XA0,
0X10,0X80,0X10,0X81,0X18,0X61,0X10,0X61,0X18,0X61,0X18,0X80,0X18,0X80,0X18,0X80,
0X18,0X81,0X18,0X82,0X18,0X81,0X18,0X81,0X18,0X81,0X18,0X80,0X18,0X81,0X20,0XA1,
0X20,0X81,0X20,0XA1,0X10,0X40,0X18,0XA1,0X49,0XE5,0XCD,0XF3,0XBD,0X70,0XD6,0X12,
0XD5,0XF2,0XD6,0X13,0XDE,0X13,0XE6,0X53,0XE6,0X53,0XE6,0X54,0XE6,0X33,0XE6,0X54,
0XBC,0XEE,0XE6,0X54,0XF6,0XB5,0XEE,0X95,0XEE,0X74,0XEE,0X74,0XEE,0X74,0XEE,0X74,
0XEE,0X54,0XEE,0X54,0XE6,0X33,0XC5,0X4F,0XDD,0XD1,0XEE,0X74,0XEE,0X54,0XC5,0X10,
0X93,0X6A,0X83,0X29,0X93,0XAB,0X93,0XAC,0X8B,0X8B,0X6A,0XC8,0X6A,0XA8,0X6A,0XE9,
0X83,0X8C,0X7B,0X6B,0X8B,0XCD,0X94,0X0E,0X9C,0X6F,0X94,0X6F,0X73,0X6C,0X84,0X0E,
0XBD,0XB5,0X94,0X90,0XA4,0XF2,0XA4,0XB1,0XA4,0XB1,0XB5,0X53,0XA4,0XF1,0X83,0XCD,
0X6B,0X0B,0X31,0X44,0X18,0XA1,0X18,0XC2,0X20,0XE2,0X4A,0X07,0X62,0XC9,0X73,0X2B,
0X73,0X0A,0X7B,0X4B,0X7B,0X2B,0X83,0X4B,0X7B,0X0A,0X6A,0XC9,0X6A,0XC8,0X62,0X46,
0X49,0XA4,0X39,0X01,0X51,0XE5,0X9C,0X0D,0X8B,0XCC,0X20,0X80,0X18,0X80,0X18,0X80,
0X18,0X60,0X18,0X60,0X10,0X40,0X18,0X41,0X18,0X61,0X10,0X61,0X10,0X61,0X10,0X40,
0X10,0X40,0X10,0X40,0X10,0X20,0X08,0X20,0X08,0X20,0X10,0X60,0X10,0X60,0X10,0X60,
0X10,0X60,0X10,0X60,0X10,0X60,0X10,0X40,0X10,0X40,0X10,0X61,0X10,0X61,0X10,0X61,
0X21,0X02,0X10,0X80,0X10,0X80,0X10,0XA0,0X10,0X80,0X10,0XA1,0X10,0XA0,0X10,0X80,
0X10,0X80,0X10,0X80,0X18,0X81,0X18,0X61,0X18,0X61,0X18,0X80,0X18,0X60,0X18,0X60,
0X18,0X81,0X18,0X81,0X18,0X81,0X18,0X81,0X18,0X81,0X18,0X81,0X18,0XA1,0X20,0XA1,
0X20,0X81,0X20,0XA1,0X10,0X40,0X18,0XA1,0X49,0XE5,0XB5,0X31,0XCD,0XF2,0XD5,0XF2,
0XD5,0XD2,0XDE,0X13,0XDE,0X13,0XE6,0X54,0XE6,0X54,0XE6,0X54,0XE6,0X13,0XC5,0X2F,
0XDD,0XD2,0XEE,0X74,0XE6,0X54,0XEE,0X54,0XEE,0X74,0XEE,0X74,0XEE,0X74,0XEE,0X74,
0XEE,0X54,0XE6,0X33,0XEE,0X54,0XE6,0X54,0XEE,0X74,0XEE,0X75,0XDD,0XD3,0X93,0XAB,
0X83,0X2A,0X7B,0X0A,0X83,0X4B,0X8B,0X8C,0X8B,0XAD,0X8B,0XAD,0X83,0XAD,0X83,0XAD,
0X83,0XCD,0X94,0X2F,0XA4,0X91,0XBD,0X74,0XB5,0X33,0XB5,0X53,0X94,0X70,0X9C,0XB1,
0XB5,0X74,0X9C,0X90,0XA4,0XB1,0XA4,0XB1,0XA4,0XF2,0XBD,0X74,0X9C,0X91,0X31,0X44,
0X10,0X60,0X10,0X80,0X00,0X20,0X08,0X20,0X18,0XA1,0X10,0X60,0X31,0X64,0X5A,0X88,
0X6B,0X0A,0X7B,0X8C,0X8B,0XAD,0X83,0X8C,0X7B,0X6C,0X62,0XA8,0X62,0X88,0X52,0X26,
0X41,0X84,0X31,0X01,0X31,0X22,0X52,0X26,0X6A,0XE9,0X39,0X43,0X20,0XA1,0X18,0X80,
0X18,0X81,0X18,0X60,0X18,0X61,0X18,0X41,0X10,0X40,0X10,0X60,0X10,0X60,0X10,0X60,
0X10,0X40,0X10,0X40,0X08,0X20,0X08,0X20,0X08,0X20,0X10,0X40,0X10,0X40,0X10,0X60,
0X18,0X81,0X18,0X61,0X18,0X61,0X10,0X61,0X10,0X61,0X10,0X61,0X10,0X61,0X10,0X40,
0X20,0XE2,0X18,0X81,0X18,0X80,0X10,0X80,0X10,0X80,0X10,0X80,0X10,0XA0,0X10,0X80,
0X10,0XA0,0X10,0X80,0X10,0X81,0X18,0X81,0X18,0X80,0X18,0X60,0X18,0X60,0X18,0X60,
0X18,0X61,0X18,0X81,0X18,0X61,0X18,0X61,0X18,0X60,0X18,0X81,0X20,0XA1,0X20,0XA1,
0X20,0XA1,0X20,0XA1,0X20,0XA2,0X20,0XC2,0X52,0X06,0XB5,0X31,0XB5,0X0F,0XD6,0X13,
0XCD,0XB2,0XD5,0XF3,0XDE,0X34,0XE6,0X54,0XE6,0X54,0XE6,0X13,0XCD,0X70,0XDD,0XF2,
0XEE,0X74,0XEE,0X95,0XF6,0X95,0XEE,0X54,0XEE,0X74,0XEE,0X74,0XEE,0X74,0XEE,0X74,
0XE6,0X54,0XE6,0X54,0XEE,0X74,0XEE,0X75,0XEE,0X75,0XD5,0XF4,0X93,0XCC,0X41,0X84,
0X28,0XE2,0X18,0X80,0X21,0X02,0X41,0XC5,0X6B,0X2B,0X7B,0X8D,0X8C,0X0E,0X83,0XAD,
0X94,0X4F,0XA4,0XD1,0XBD,0X74,0XC5,0XB5,0XBD,0X54,0XCD,0XD6,0XA4,0XD2,0XA4,0XD2,
0XB5,0X33,0XA4,0XD1,0X9C,0X90,0X9C,0X90,0XAD,0X13,0XB5,0X74,0X41,0XA5,0X18,0X81,
0X10,0X61,0X18,0XE2,0X08,0X81,0X08,0X61,0X08,0X40,0X21,0X23,0X18,0X80,0X41,0XC6,
0X6B,0X0B,0X83,0XCD,0X94,0X70,0X9C,0XB1,0X94,0X70,0X62,0XC9,0X52,0X47,0X4A,0X06,
0X31,0X63,0X29,0X22,0X20,0XE1,0X41,0XA4,0X6A,0XE9,0X6A,0XA9,0X28,0XC2,0X20,0X81,
0X18,0X80,0X18,0X60,0X18,0X60,0X10,0X40,0X10,0X40,0X10,0X60,0X10,0X60,0X10,0X60,
0X10,0X40,0X10,0X40,0X08,0X20,0X08,0X00,0X08,0X20,0X10,0X40,0X10,0X40,0X10,0X40,
0X10,0X60,0X18,0X61,0X10,0X61,0X10,0X61,0X10,0X60,0X10,0X40,0X10,0X40,0X10,0X40,
0X28,0XE3,0X18,0X60,0X18,0X60,0X10,0X60,0X10,0X80,0X10,0X80,0X10,0X81,0X10,0X80,
0X10,0X80,0X10,0X80,0X10,0X80,0X10,0X81,0X18,0X81,0X18,0X61,0X18,0X61,0X18,0X61,
0X18,0X61,0X18,0X82,0X18,0X81,0X18,0X61,0X18,0X60,0X18,0X61,0X20,0XA1,0X20,0XA1,
0X20,0XA1,0X18,0X61,0X20,0XA2,0X18,0X60,0X39,0X43,0XBD,0X72,0XC5,0X71,0XA4,0X8D,
0XBD,0X30,0XD5,0XF3,0XDE,0X34,0XE6,0X54,0XE6,0X54,0XD5,0XB2,0XBD,0X0F,0XE6,0X54,
0XEE,0X54,0XEE,0X74,0XF6,0X95,0XEE,0X54,0XEE,0X74,0XEE,0X74,0XEE,0X74,0XEE,0X74,
0XEE,0X54,0XE6,0X53,0XEE,0X74,0XEE,0X75,0XE6,0X14,0X8B,0XAB,0X31,0X02,0X10,0X40,
0X08,0X40,0X00,0X40,0X00,0X20,0X00,0X00,0X10,0X60,0X42,0X07,0X8B,0XEE,0X94,0X4F,
0XA4,0XF2,0XBD,0X95,0XB5,0X74,0XBD,0X95,0XBD,0X54,0XBD,0X74,0XBD,0X74,0XAC,0XD2,
0XB5,0X33,0XA4,0XD2,0X94,0X50,0X9C,0X70,0XB5,0X74,0XA4,0XB1,0X20,0XA2,0X20,0XC2,
0XC5,0XF7,0X31,0X85,0X08,0XA2,0X10,0XA2,0X08,0X61,0X10,0XA1,0X18,0XA1,0X41,0XE6,
0X7B,0X8D,0XA4,0XD2,0XB5,0X54,0XBD,0X95,0XBD,0X94,0X83,0XED,0X5A,0XA9,0X4A,0X06,
0X41,0XE5,0X39,0XA4,0X20,0XC1,0X20,0XC1,0X73,0X2A,0X8B,0XCE,0X31,0X03,0X20,0XA1,
0X18,0X60,0X18,0X60,0X18,0X61,0X18,0X80,0X10,0X60,0X10,0X60,0X10,0X60,0X10,0X60,
0X08,0X40,0X08,0X40,0X08,0X40,0X08,0X20,0X08,0X20,0X10,0X40,0X08,0X20,0X10,0X40,
0X10,0X60,0X18,0X61,0X10,0X61,0X10,0X60,0X10,0X60,0X10,0X40,0X10,0X40,0X10,0X20,
0X28,0XC2,0X20,0XA1,0X18,0X60,0X18,0X60,0X18,0X61,0X18,0X61,0X10,0X81,0X10,0X80,
0X10,0X81,0X10,0X81,0X10,0X81,0X10,0X81,0X18,0X61,0X18,0X61,0X18,0X61,0X10,0X61,
0X18,0X61,0X18,0X82,0X18,0X81,0X18,0X81,0X10,0X61,0X18,0X61,0X20,0XA2,0X20,0XA2,
0X20,0XA1,0X20,0X81,0X18,0X81,0X18,0X60,0X28,0XC1,0XC5,0X93,0XCD,0XD3,0XBD,0X50,
0XAC,0XAE,0XB4,0XEF,0XD5,0XF2,0XDE,0X13,0XD5,0XF3,0XC5,0X0F,0XEE,0X54,0XEE,0X75,
0XEE,0X74,0XEE,0X75,0XEE,0X74,0XEE,0X74,0XEE,0X74,0XF6,0X75,0XEE,0X74,0XEE,0X74,
0XD5,0XB1,0XE6,0X74,0XF6,0XD5,0XE6,0X54,0XB4,0XCF,0X39,0X03,0X18,0X20,0X08,0X00,
0X08,0X20,0X00,0X20,0X00,0X20,0X00,0X20,0X08,0X40,0X10,0X81,0X62,0XEA,0X9C,0X90,
0XBD,0X94,0XC5,0XD6,0XC6,0X16,0XB5,0X74,0XB5,0XB5,0XC5,0XF6,0XBD,0XB5,0XA4,0XF2,
0XAD,0X33,0XA4,0XD2,0X94,0X70,0XA4,0XD1,0XC5,0XB5,0X83,0XEE,0X18,0XA1,0X18,0XA2,
0X18,0X82,0X18,0XA2,0X08,0X81,0X10,0X81,0X08,0X61,0X08,0X61,0X31,0X85,0X6B,0X2C,
0X9C,0XB2,0XBD,0X95,0XC5,0XD7,0XCD,0XF7,0XCE,0X38,0XBD,0XB5,0X7B,0X8C,0X4A,0X27,
0X39,0XA5,0X41,0XC5,0X29,0X02,0X18,0X80,0X4A,0X06,0X7B,0X4C,0X49,0XC5,0X20,0XA1,
0X18,0X81,0X18,0X81,0X18,0X81,0X18,0X61,0X10,0X40,0X08,0X60,0X08,0X60,0X08,0X60,
0X08,0X40,0X08,0X40,0X08,0X40,0X08,0X20,0X08,0X20,0X10,0X40,0X10,0X20,0X10,0X40,
0X18,0X60,0X18,0X60,0X18,0X60,0X10,0X60,0X10,0X60,0X10,0X40,0X10,0X20,0X10,0X20,
0X20,0XC2,0X20,0XA1,0X18,0X60,0X18,0X60,0X18,0X61,0X18,0X61,0X10,0X61,0X10,0X60,
0X18,0X61,0X18,0X61,0X18,0X61,0X18,0X61,0X18,0X61,0X18,0X62,0X18,0X62,0X10,0X62,
0X10,0X61,0X18,0X61,0X18,0X61,0X18,0X61,0X10,0X61,0X18,0X82,0X18,0X81,0X20,0X81,
0X20,0X81,0X20,0XA1,0X20,0X81,0X20,0X81,0X28,0XC1,0XC5,0X93,0XCD,0XD3,0XCD,0XD2,
0XCD,0X92,0XCD,0XB2,0XBD,0X0F,0XD5,0XD2,0XC5,0X50,0XE6,0X34,0XEE,0X54,0XEE,0X74,
0XEE,0X74,0XEE,0X74,0XEE,0X74,0XEE,0X74,0XEE,0X74,0XEE,0X74,0XEE,0X95,0XD5,0XB1,
0XE6,0X54,0XEE,0XB5,0XE6,0X54,0XD5,0XB2,0X52,0X05,0X28,0XC2,0X18,0X60,0X08,0X40,
0X08,0X40,0X08,0X40,0X08,0X40,0X08,0X40,0X08,0X61,0X18,0XA2,0X31,0X64,0X94,0X70,
0XBD,0XB5,0XD6,0X78,0XC6,0X16,0XBD,0XB5,0XC5,0XF6,0XAD,0X33,0XAD,0X74,0XA5,0X12,
0XA4,0XF2,0X9C,0XB1,0X9C,0XB1,0XB5,0X54,0XC5,0XB5,0X8C,0X0E,0X20,0XE2,0X18,0X81,
0X10,0X81,0X10,0X81,0X08,0X40,0X00,0X40,0X00,0X00,0X08,0X61,0X4A,0X28,0X8C,0X30,
0XCE,0X18,0XD6,0X38,0XDE,0X79,0XD6,0X59,0XD6,0X58,0XB5,0X95,0X73,0X6C,0X6B,0X2B,
0X42,0X06,0X39,0X84,0X31,0X64,0X20,0XA1,0X29,0X02,0X6B,0X0A,0X49,0XE6,0X20,0XA1,
0X20,0X81,0X18,0X61,0X20,0XA2,0X10,0X61,0X10,0X40,0X08,0X40,0X08,0X40,0X08,0X60,
0X08,0X40,0X08,0X40,0X08,0X40,0X08,0X20,0X08,0X40,0X10,0X60,0X10,0X40,0X10,0X60,
0X18,0X81,0X18,0X60,0X18,0X81,0X10,0X60,0X10,0X40,0X10,0X60,0X10,0X20,0X10,0X20,
0X28,0XC2,0X20,0X81,0X18,0X60,0X18,0X40,0X18,0X61,0X10,0X61,0X10,0X61,0X10,0X61,
0X10,0X61,0X18,0X61,0X10,0X41,0X18,0X61,0X18,0X62,0X18,0X62,0X18,0X61,0X10,0X61,
0X10,0X61,0X18,0X81,0X18,0X82,0X18,0X61,0X10,0X61,0X18,0X81,0X20,0X81,0X20,0X81,
0X20,0XA1,0X20,0XA1,0X20,0X81,0X20,0X81,0X28,0XC1,0XC5,0X93,0XCD,0XD3,0XD5,0XF3,
0XDE,0X14,0XDE,0X34,0XDE,0X14,0XBD,0X30,0XB4,0XCF,0XE6,0X34,0XE6,0X54,0XEE,0X74,
0XEE,0X94,0XEE,0X74,0XEE,0X74,0XEE,0X74,0XEE,0X74,0XEE,0X74,0XDD,0XF2,0XD5,0XD2,
0XE6,0X74,0XEE,0XB6,0XD5,0XD3,0X8B,0X6A,0X31,0X22,0X10,0X60,0X10,0X60,0X10,0X61,
0X08,0X60,0X08,0X40,0X08,0X40,0X08,0X40,0X08,0X40,0X10,0XA2,0X10,0X60,0X94,0X90,
0XC6,0X16,0XE6,0XFA,0XCE,0X57,0XBD,0XB5,0XBD,0XD5,0XBD,0XD5,0XBD,0XD5,0XB5,0X94,
0XA5,0X12,0XA4,0XF2,0X9C,0X91,0XBD,0XB5,0XCE,0X16,0X8C,0X0F,0X29,0X44,0X10,0X81,
0X10,0XA2,0X10,0XA1,0X10,0X81,0X10,0X81,0X10,0X81,0X21,0X24,0X42,0X27,0X8C,0X50,
0XD6,0X99,0XDE,0X99,0XD6,0X59,0XCE,0X38,0XC5,0XF7,0XB5,0X95,0X83,0XEE,0X6B,0X4C,
0X42,0X06,0X39,0XC6,0X41,0XC5,0X29,0X23,0X20,0XA1,0X6A,0XE9,0X52,0X47,0X20,0X60,
0X20,0X81,0X18,0X81,0X18,0X81,0X10,0X61,0X10,0X60,0X08,0X40,0X08,0X60,0X08,0X60,
0X08,0X40,0X08,0X60,0X08,0X40,0X08,0X20,0X08,0X20,0X10,0X40,0X10,0X40,0X18,0X60,
0X18,0X80,0X18,0X81,0X18,0X80,0X10,0X60,0X10,0X60,0X10,0X60,0X10,0X20,0X10,0X20,
0X20,0XA2,0X20,0X81,0X18,0X61,0X18,0X60,0X18,0X61,0X10,0X61,0X10,0X61,0X10,0X61,
0X10,0X61,0X10,0X61,0X10,0X61,0X10,0X61,0X18,0X61,0X10,0X40,0X18,0X81,0X18,0X81,
0X18,0X81,0X18,0X81,0X18,0X61,0X18,0X61,0X18,0X61,0X18,0X61,0X18,0X81,0X20,0X81,
0X20,0X81,0X18,0X60,0X18,0X61,0X20,0X81,0X31,0X43,0XC5,0X93,0XCD,0XF3,0XD6,0X13,
0XDE,0X34,0XDE,0X34,0XDE,0X34,0XC5,0X51,0XCD,0X92,0XBD,0X0F,0XD5,0XD2,0XE6,0X54,
0XEE,0X94,0XEE,0X54,0XEE,0X54,0XEE,0X74,0XEE,0X54,0XDE,0X13,0XD5,0XD1,0XE6,0X94,
0XE6,0X94,0XE6,0X55,0XB4,0XAF,0X62,0X46,0X20,0XA1,0X10,0X60,0X08,0X40,0X08,0X61,
0X08,0X61,0X00,0X00,0X00,0X20,0X00,0X20,0X10,0X81,0X20,0XE3,0X10,0X81,0X84,0X0E,
0XD6,0X78,0XDE,0XFA,0XD6,0X98,0XCE,0X57,0XD6,0X78,0XC6,0X37,0XC6,0X37,0XBD,0XD5,
0XAD,0X13,0XB5,0X54,0XB5,0X53,0XC5,0XD6,0XCE,0X17,0X9C,0X91,0X31,0XA5,0X39,0XC6,
0X10,0X81,0X10,0X81,0X08,0X61,0X08,0X61,0X08,0X40,0X5A,0XEB,0X42,0X07,0XBD,0XD6,
0XDE,0XDA,0XD6,0X79,0XCD,0XF7,0XC5,0XB6,0XBD,0X95,0XA5,0X13,0X83,0XEE,0X73,0X6C,
0X5A,0XA9,0X4A,0X48,0X52,0X68,0X49,0XE6,0X28,0XE2,0X62,0XC8,0X52,0X46,0X18,0X60,
0X18,0X60,0X18,0X60,0X18,0X61,0X10,0X60,0X10,0X60,0X08,0X60,0X08,0X40,0X08,0X60,
0X08,0X40,0X08,0X60,0X08,0X40,0X08,0X20,0X08,0X20,0X10,0X40,0X10,0X40,0X18,0X60,
0X18,0X80,0X18,0X81,0X18,0XA1,0X18,0X80,0X10,0X60,0X10,0X60,0X10,0X20,0X10,0X40,
0X28,0XC2,0X18,0X60,0X18,0X80,0X18,0X60,0X18,0X60,0X18,0X61,0X18,0X61,0X10,0X41,
0X18,0X61,0X18,0X41,0X10,0X41,0X10,0X61,0X18,0XA2,0X18,0X81,0X18,0X81,0X18,0X81,
0X18,0X61,0X10,0X41,0X10,0X41,0X10,0X41,0X18,0X61,0X18,0X61,0X18,0X82,0X18,0X81,
0X20,0X81,0X18,0X81,0X20,0XA1,0X20,0XC2,0X39,0X64,0XBD,0X73,0XD5,0XD3,0XDE,0X14,
0XDE,0X34,0XDE,0X34,0XD5,0XF3,0XCD,0XB2,0XDE,0X34,0XD5,0XD3,0XB4,0XEF,0XBD,0X0F,
0XD5,0XF2,0XDE,0X13,0XE6,0X54,0XE6,0X54,0XDE,0X13,0XD5,0X91,0XEE,0X74,0XEE,0X94,
0XE6,0X74,0XCD,0X51,0X7B,0X09,0X6A,0XA8,0X31,0X02,0X10,0X81,0X08,0X40,0X08,0X40,
0X08,0X61,0X08,0X40,0X08,0X60,0X08,0X40,0X10,0X61,0X39,0XA5,0X20,0XE2,0X5A,0XC9,
0XD6,0X78,0XDE,0XD9,0XD6,0XB9,0XDE,0XB9,0XCE,0X78,0XC6,0X37,0XC6,0X37,0XBD,0XF6,
0XAD,0X53,0XB5,0X74,0XBD,0X95,0XC5,0XD6,0XCE,0X17,0X94,0X50,0X31,0X84,0X5A,0XC9,
0X4A,0X47,0X31,0XA5,0X18,0XC2,0X18,0XC2,0X5A,0XEA,0X83,0XEE,0XAD,0X33,0XDE,0X98,
0XD6,0X78,0XB5,0X74,0XAD,0X13,0XB5,0X54,0XB5,0X35,0XAD,0X33,0X73,0XAD,0X73,0X8D,
0X73,0X8D,0X63,0X0B,0X63,0X0B,0X5A,0XA9,0X39,0X84,0X62,0XC8,0X41,0XE5,0X18,0X61,
0X18,0X61,0X18,0X60,0X18,0X60,0X10,0X40,0X10,0X60,0X08,0X60,0X08,0X60,0X08,0X40,
0X08,0X40,0X08,0X40,0X08,0X40,0X08,0X40,0X08,0X20,0X08,0X40,0X10,0X61,0X18,0X60,
0X18,0X81,0X18,0X81,0X20,0X82,0X10,0X61,0X10,0X60,0X10,0X61,0X08,0X20,0X10,0X40,
0X28,0XA2,0X20,0X60,0X20,0X81,0X20,0X61,0X18,0X80,0X18,0X80,0X18,0X80,0X18,0X61,
0X18,0X61,0X18,0X41,0X10,0X40,0X10,0X61,0X10,0X61,0X18,0X81,0X18,0X81,0X18,0X81,
0X10,0X61,0X18,0X61,0X18,0X61,0X10,0X41,0X10,0X61,0X18,0X61,0X18,0XA2,0X20,0XA1,
0X20,0XA1,0X20,0XA1,0X20,0X81,0X20,0XA1,0X29,0X02,0XBD,0X73,0XD5,0XF4,0XDE,0X13,
0XDE,0X34,0XDE,0X14,0XC5,0X51,0XDE,0X34,0XDE,0X34,0XD5,0XF3,0XDD,0XF3,0XD5,0XB2,
0XB4,0XEE,0XBD,0X0F,0XD5,0XF2,0XDE,0X13,0XBD,0X0F,0XE6,0X54,0XEE,0X75,0XEE,0X75,
0XCD,0X71,0X83,0X4A,0X83,0X4A,0X83,0X6B,0X62,0XA9,0X21,0X02,0X10,0XA1,0X00,0X20,
0X08,0X20,0X00,0X20,0X08,0X41,0X10,0X82,0X39,0X86,0X39,0XC6,0X5A,0XA9,0X52,0X88,
0XB5,0X94,0XDE,0XDA,0XDE,0XB9,0XD6,0X78,0XCE,0X37,0XCE,0X57,0XC6,0X16,0XC5,0XF6,
0XBD,0X95,0XB5,0X74,0XB5,0X54,0XAD,0X12,0XB5,0X74,0X9C,0X91,0X94,0X90,0X73,0X6C,
0XBD,0XB5,0X9C,0XD1,0X83,0XEE,0X8C,0X50,0X63,0X0B,0XB5,0X74,0XD6,0X58,0XCE,0X17,
0X9C,0X90,0X94,0X50,0X9C,0X91,0XAC,0XF3,0XAD,0X34,0X8C,0X50,0X6B,0X4C,0X73,0X6C,
0X6B,0X4B,0X63,0X0B,0X63,0X0B,0X7B,0XAD,0X62,0XEA,0X5A,0X88,0X52,0X47,0X20,0XA1,
0X18,0X60,0X18,0X40,0X18,0X61,0X10,0X40,0X10,0X60,0X10,0X60,0X10,0X60,0X08,0X40,
0X08,0X40,0X08,0X40,0X08,0X40,0X08,0X40,0X08,0X20,0X10,0X40,0X18,0X81,0X18,0X81,
0X18,0X81,0X18,0X61,0X18,0X81,0X10,0X61,0X10,0X60,0X18,0X61,0X10,0X20,0X10,0X40,
0X20,0X81,0X18,0X61,0X20,0X81,0X18,0X61,0X18,0X80,0X18,0X80,0X18,0X61,0X10,0X61,
0X18,0X41,0X10,0X40,0X10,0X40,0X10,0X61,0X10,0X61,0X10,0X61,0X18,0X81,0X18,0X61,
0X18,0X61,0X18,0X61,0X10,0X61,0X18,0X61,0X18,0X61,0X18,0X81,0X18,0X81,0X20,0XA1,
0X20,0XA1,0X20,0XA1,0X20,0XA1,0X20,0XA1,0X28,0XE2,0XBD,0X73,0XCD,0XD3,0XD5,0XF3,
0XD6,0X13,0XDD,0XF4,0XBD,0X30,0XDE,0X14,0XDE,0X14,0XDE,0X14,0XDE,0X13,0XD5,0XF2,
0XDD,0XF2,0XD5,0XD2,0XAC,0XAE,0XB4,0XEF,0XDE,0X13,0XE6,0X54,0XE6,0X35,0XDD,0XF4,
0X83,0X29,0X72,0XA8,0X73,0X0A,0X73,0X2A,0X73,0X8C,0X6B,0X4B,0X31,0X84,0X21,0X23,
0X18,0XC1,0X18,0XC2,0X39,0XA6,0X6B,0X4C,0X52,0X49,0X9C,0X71,0X62,0XEA,0X83,0XEE,
0X9C,0XB1,0XCE,0X57,0XCE,0X78,0XCE,0X57,0XC6,0X37,0XCE,0X57,0XC6,0X16,0XC5,0XD6,
0XC5,0XD6,0XBD,0X95,0XAD,0X13,0X9C,0X70,0X9C,0X90,0XA4,0XF2,0X9C,0XB1,0XBD,0XD5,
0XD6,0X58,0XDE,0XD9,0XE6,0XFA,0XDE,0XB9,0XD6,0X78,0XCE,0X37,0XBD,0XB5,0X9C,0XB1,
0X9C,0XB1,0XAD,0X13,0XB5,0X54,0XB5,0X75,0X94,0X71,0X83,0XEF,0X7B,0XCD,0X6B,0X4B,
0X84,0X0E,0X94,0X70,0X9C,0XF2,0X94,0X70,0X84,0X0F,0X5A,0XA9,0X52,0X27,0X18,0X61,
0X18,0X61,0X10,0X61,0X10,0X60,0X10,0X40,0X10,0X60,0X08,0X60,0X08,0X60,0X08,0X40,
0X08,0X40,0X08,0X40,0X08,0X40,0X08,0X40,0X00,0X20,0X10,0X60,0X10,0X60,0X18,0X80,
0X10,0X60,0X18,0X60,0X18,0X81,0X10,0X61,0X10,0X60,0X10,0X61,0X10,0X61,0X10,0X60,
0X18,0X81,0X18,0X61,0X18,0XA1,0X10,0X81,0X18,0X81,0X18,0X61,0X10,0X41,0X10,0X41,
0X10,0X41,0X18,0X41,0X10,0X40,0X10,0X61,0X10,0X61,0X18,0X61,0X18,0X61,0X10,0X61,
0X18,0X60,0X18,0X61,0X18,0X61,0X18,0X61,0X18,0X61,0X10,0X60,0X18,0X81,0X20,0X81,
0X20,0XA1,0X18,0X80,0X18,0X60,0X18,0X60,0X28,0XE2,0XAD,0X11,0XCD,0XB3,0XD5,0XD3,
0XD5,0XF3,0XCD,0X92,0XD5,0XD3,0XDD,0XF4,0XD5,0XF3,0XD5,0XF3,0XDD,0XF3,0XD5,0XF2,
0XDE,0X13,0XD5,0XF3,0XC5,0X71,0XC5,0X51,0XD5,0XD3,0XB4,0XAE,0XCD,0X51,0XA4,0X2E,
0X6A,0X88,0X5A,0X06,0X52,0X06,0X5A,0X67,0X6B,0X2A,0XAD,0X32,0XBD,0XB4,0X9C,0XD1,
0X8C,0X2F,0X84,0X2F,0X9C,0XB1,0XC5,0XD5,0XDE,0X98,0XCE,0X37,0XAD,0X12,0XB5,0X54,
0XA4,0XF2,0XC5,0XD6,0XB5,0XB5,0XBD,0XD5,0XBD,0XF6,0XBD,0XB5,0XBD,0XB5,0XBD,0XB5,
0XBD,0XB5,0XBD,0XB5,0XA4,0XB1,0X8C,0X0F,0X8C,0X0E,0X94,0X70,0X9C,0X91,0XC5,0XD6,
0XD6,0X78,0XDE,0X99,0XDE,0X98,0XC5,0XD5,0XA4,0XF2,0XAD,0X33,0XBD,0X95,0XBD,0X95,
0XAD,0X13,0XBD,0X74,0XC5,0XB6,0XC5,0XB6,0XA4,0XD3,0X8C,0X30,0X84,0X0E,0X73,0XAD,
0X94,0X90,0XA5,0X33,0XAD,0X53,0X8C,0X4F,0X5A,0XCA,0X6B,0X2B,0X41,0XE7,0X18,0X81,
0X18,0X61,0X10,0X41,0X10,0X60,0X10,0X40,0X10,0X40,0X08,0X60,0X08,0X60,0X08,0X40,
0X08,0X60,0X08,0X40,0X08,0X40,0X08,0X40,0X00,0X20,0X10,0X60,0X10,0X80,0X10,0X80,
0X10,0X80,0X10,0X60,0X10,0X80,0X18,0X81,0X10,0X40,0X10,0X40,0X10,0X40,0X10,0X40,
0X18,0X81,0X18,0X81,0X18,0XA1,0X18,0X81,0X18,0X61,0X18,0X61,0X18,0X61,0X18,0X61,
0X10,0X60,0X10,0X40,0X10,0X60,0X18,0X61,0X18,0X61,0X10,0X61,0X10,0X61,0X10,0X61,
0X18,0X61,0X18,0X81,0X18,0X81,0X10,0X60,0X18,0X80,0X18,0X60,0X18,0X60,0X18,0X81,
0X18,0X81,0X18,0X80,0X10,0X60,0X10,0X60,0X20,0XC2,0X9C,0X4F,0XCD,0XB3,0XD5,0XD3,
0XD5,0XF3,0XBC,0XF0,0XD5,0XD3,0XD5,0XF3,0XD5,0XF3,0XD5,0XF3,0XD5,0XF3,0XD5,0XF3,
0XDE,0X13,0XD5,0XD3,0XC5,0X50,0XDE,0X13,0XE6,0X54,0XDE,0X34,0XAC,0XAE,0X6A,0XA7,
0X6A,0X88,0X62,0X47,0X62,0X89,0X73,0X0A,0X7B,0XAD,0X84,0X0E,0XAD,0X33,0XB5,0X94,
0XBD,0XD5,0XCE,0X57,0XDE,0XD9,0XE6,0XFA,0XDE,0XD9,0XDE,0XD9,0XD6,0X37,0XC5,0XD6,
0XB5,0X74,0XB5,0X94,0X94,0X70,0XB5,0X74,0XAD,0X53,0XB5,0X74,0XAD,0X53,0XB5,0X74,
0XB5,0X74,0XBD,0X75,0XA4,0XD2,0X83,0XEE,0X7B,0X6C,0X9C,0X91,0X8C,0X0F,0XAD,0X13,
0XCE,0X17,0XD6,0X58,0XCE,0X17,0XB5,0X54,0XB5,0X33,0XA4,0XD1,0XA4,0XD2,0XA4,0XD2,
0XBD,0X95,0XC5,0XD6,0XC5,0XF7,0XBD,0XB6,0X9C,0XB2,0X9C,0XB2,0X7B,0XCD,0X84,0X0E,
0XAD,0X33,0XAD,0X33,0X8C,0X70,0X84,0X0F,0X73,0X8D,0X62,0XEB,0X31,0X65,0X20,0XC3,
0X18,0X82,0X10,0X41,0X10,0X41,0X10,0X60,0X08,0X60,0X08,0X60,0X08,0X40,0X10,0X40,
0X10,0X40,0X08,0X60,0X08,0X40,0X08,0X20,0X08,0X40,0X08,0X40,0X10,0X80,0X10,0X80,
0X10,0X80,0X10,0X80,0X10,0X81,0X18,0X81,0X10,0X40,0X10,0X20,0X10,0X20,0X10,0X40,
0X18,0XA2,0X10,0X61,0X18,0X81,0X18,0X81,0X18,0X81,0X10,0X61,0X18,0X81,0X18,0X61,
0X10,0X61,0X10,0X40,0X10,0X60,0X18,0X61,0X18,0X61,0X10,0X40,0X10,0X60,0X10,0X61,
0X10,0X60,0X10,0X60,0X10,0X60,0X10,0X60,0X10,0X60,0X10,0X60,0X10,0X60,0X18,0X81,
0X18,0X81,0X18,0X81,0X10,0X40,0X10,0X60,0X20,0XA1,0X8B,0XCD,0XC5,0X72,0XCD,0X72,
0XCD,0X92,0XB4,0XAF,0XD5,0XD2,0XD5,0XD2,0XD5,0XD2,0XD5,0XD2,0XD5,0XD2,0XD5,0XD2,
0XD5,0XD2,0XCD,0X91,0XD5,0XF3,0XE6,0X54,0XE6,0X55,0XCD,0X92,0X7B,0X08,0X6A,0XA8,
0X72,0XC9,0X73,0X2B,0X9C,0X50,0XAC,0XF2,0XB5,0X53,0XA5,0X12,0XB5,0X94,0XB5,0X74,
0XB5,0X74,0XC5,0XD5,0XBD,0XB5,0XC5,0XD6,0XCE,0X16,0XDE,0X78,0XD6,0X17,0XBD,0X95,
0XB5,0X53,0XAD,0X33,0XAD,0X33,0XA5,0X12,0XA4,0XF2,0X8C,0X0E,0X83,0XEE,0X8C,0X0E,
0X94,0X70,0X94,0X50,0X94,0X4F,0X7B,0X8D,0X5A,0X89,0X9C,0X90,0XB5,0X74,0X9C,0X91,
0XAD,0X53,0XC5,0XF6,0XC5,0XF6,0XBD,0XB5,0XB5,0X74,0XAD,0X13,0XAD,0X33,0XA4,0XF3,
0XB5,0X54,0XBD,0X95,0XC6,0X17,0XBD,0XB6,0XB5,0X54,0XA4,0XD3,0X7B,0XCD,0X8C,0X2F,
0XA5,0X33,0XB5,0X94,0XA4,0XF2,0X94,0X91,0X9C,0XB2,0X83,0XEF,0X6B,0X2C,0X18,0X82,
0X18,0X61,0X10,0X20,0X10,0X41,0X10,0X60,0X10,0X40,0X08,0X40,0X08,0X40,0X10,0X40,
0X10,0X40,0X08,0X60,0X08,0X20,0X08,0X20,0X08,0X20,0X08,0X40,0X10,0X80,0X10,0X80,
0X10,0X60,0X10,0X60,0X10,0X81,0X10,0X61,0X10,0X61,0X10,0X40,0X10,0X40,0X10,0X40,
0X18,0XA2,0X18,0X61,0X18,0X81,0X18,0X81,0X18,0X81,0X18,0X61,0X18,0X61,0X18,0X81,
0X10,0X60,0X10,0X40,0X10,0X40,0X10,0X60,0X10,0X60,0X10,0X40,0X10,0X40,0X10,0X40,
0X10,0X40,0X10,0X60,0X10,0X60,0X10,0X60,0X10,0X61,0X10,0X60,0X18,0X60,0X18,0X81,
0X18,0X81,0X18,0X81,0X10,0X60,0X18,0X61,0X20,0XA2,0X73,0X0A,0XBD,0X51,0XC5,0X71,
0XC5,0X51,0XBD,0X0F,0XCD,0XB2,0XD5,0XD2,0XD5,0XD2,0XD5,0XD2,0XCD,0XB2,0XCD,0XB2,
0XCD,0X91,0XC5,0X50,0XD5,0XF3,0XE6,0X75,0XDD,0XF4,0X93,0X8B,0X72,0XE8,0X7B,0X4A,
0X7B,0X6C,0X8C,0X0E,0XB5,0X33,0XC5,0XD5,0XC5,0XD6,0XC5,0XD5,0XC5,0XF6,0XB5,0X94,
0XBD,0XB5,0XBD,0XB5,0XB5,0X54,0XAD,0X13,0XA4,0XF2,0XBD,0X95,0XC5,0XB6,0XBD,0X95,
0XBD,0XB5,0XC5,0XD6,0XC5,0XD5,0X9C,0X90,0X8C,0X0E,0X5A,0X88,0X52,0X68,0X62,0XEA,
0X6A,0XEA,0X6A,0XEA,0X6A,0XA9,0X52,0X27,0X52,0X68,0X9C,0XB1,0XBD,0X95,0XC5,0XD5,
0XB5,0X74,0XB5,0XB5,0XBD,0XD6,0XCE,0X17,0XB5,0X95,0XBD,0XB5,0XBD,0X95,0XB5,0X34,
0XBD,0X75,0XBD,0X96,0XB5,0X95,0XB5,0X55,0XAD,0X14,0X94,0X71,0X7B,0XEE,0X8C,0X4F,
0XB5,0X94,0XA4,0XF2,0XAD,0X33,0XBD,0XB5,0XB5,0X55,0X8C,0X10,0X52,0X49,0X18,0X82,
0X10,0X41,0X10,0X41,0X10,0X40,0X10,0X40,0X10,0X40,0X08,0X40,0X10,0X60,0X10,0X20,
0X10,0X40,0X08,0X60,0X08,0X40,0X08,0X20,0X08,0X20,0X08,0X20,0X10,0X60,0X10,0X60,
0X10,0X60,0X10,0X40,0X10,0X41,0X10,0X61,0X10,0X60,0X08,0X40,0X10,0X40,0X10,0X40,
0X18,0XA2,0X18,0X61,0X18,0X81,0X18,0X81,0X10,0X60,0X18,0X60,0X18,0X60,0X18,0X80,
0X10,0X61,0X10,0X61,0X10,0X40,0X10,0X40,0X10,0X60,0X10,0X60,0X10,0X60,0X10,0X40,
0X10,0X60,0X10,0X60,0X10,0X60,0X10,0X40,0X10,0X41,0X10,0X61,0X18,0X61,0X18,0X61,
0X18,0X61,0X18,0X61,0X10,0X60,0X18,0X81,0X20,0XA2,0X62,0XA8,0XA4,0X8E,0XBD,0X30,
0XBD,0X30,0XC5,0X50,0XD5,0XD2,0XCD,0XB1,0XD5,0XD2,0XCD,0XD1,0XCD,0XD1,0XD5,0XD2,
0XC5,0X70,0XBD,0X2F,0XDE,0X33,0XDE,0X14,0XCD,0X92,0X7A,0XC8,0X72,0XE9,0X83,0XAC,
0XA4,0XB1,0XB5,0X74,0XBD,0X95,0XC5,0XF6,0XCE,0X17,0XD6,0X78,0XCE,0X37,0XC5,0XF6,
0XC5,0XF6,0XBD,0X95,0XB5,0X34,0XB5,0X34,0XAD,0X13,0XA4,0XB2,0XCD,0XF7,0XBD,0X95,
0XC5,0XD6,0XCE,0X17,0XC5,0XF6,0XA4,0XF2,0X7B,0X8D,0X41,0XC6,0X4A,0X06,0X5A,0X88,
0X73,0X2B,0X73,0X4B,0X72,0XCA,0X49,0XE6,0X31,0X43,0X5A,0XA9,0XCE,0X16,0XCE,0X37,
0XBD,0XF6,0XBD,0XB5,0XB5,0X95,0XB5,0X95,0XB5,0X75,0XB5,0X75,0XB5,0X75,0XBD,0X96,
0XC5,0XB6,0XC5,0XB6,0XA5,0X13,0X9C,0X92,0X9C,0X92,0X8C,0X10,0X7B,0XCD,0X94,0XB1,
0X94,0X70,0X9C,0XF2,0XA4,0XF2,0XB5,0X75,0XBD,0X96,0XA4,0XD3,0X5A,0X8A,0X20,0XA2,
0X18,0X61,0X18,0X61,0X10,0X41,0X18,0X61,0X10,0X40,0X10,0X40,0X08,0X40,0X10,0X20,
0X10,0X40,0X08,0X60,0X08,0X40,0X08,0X20,0X08,0X20,0X10,0X20,0X10,0X40,0X10,0X40,
0X10,0X60,0X10,0X40,0X10,0X41,0X10,0X61,0X08,0X40,0X08,0X20,0X08,0X40,0X10,0X40,
0X18,0XA2,0X10,0X61,0X18,0X81,0X18,0X81,0X18,0X80,0X18,0X81,0X18,0X81,0X10,0X60,
0X10,0X61,0X10,0X40,0X10,0X20,0X10,0X40,0X10,0X40,0X10,0X60,0X18,0X60,0X10,0X60,
0X10,0X61,0X10,0X40,0X10,0X40,0X10,0X40,0X10,0X60,0X10,0X61,0X10,0X61,0X18,0X61,
0X10,0X61,0X10,0X40,0X18,0X60,0X10,0X40,0X18,0X81,0X39,0X64,0XAC,0XEF,0XAC,0XAE,
0XB4,0XD0,0XC5,0X71,0XD5,0XF2,0XCD,0XB1,0XCD,0XB1,0XD5,0XD2,0XCD,0XB1,0XD5,0XD2,
0XC5,0X70,0XC5,0X50,0XCD,0XB1,0XCD,0XB2,0XAC,0XAF,0X72,0XC9,0X7B,0X2A,0X94,0X2E,
0XBD,0X74,0XCD,0XF6,0XD6,0X58,0XCE,0X37,0XD6,0X38,0XD6,0X98,0XD6,0X78,0XCE,0X36,
0XC6,0X16,0XC5,0XD6,0XBD,0X75,0XBD,0X75,0XB5,0X33,0XAC,0XF3,0XC5,0XB6,0XD6,0X38,
0XD6,0X58,0XCE,0X37,0XC5,0XB5,0X9C,0X91,0X39,0X85,0X41,0XA5,0X4A,0X06,0X49,0XE6,
0X6A,0XEA,0X72,0XEA,0X72,0XCA,0X31,0X03,0X29,0X03,0X83,0XEE,0XDE,0XB9,0XDE,0XD9,
0XD6,0X98,0XCE,0X37,0XC5,0XF7,0XAD,0X14,0XA4,0XF3,0XB5,0X95,0XB5,0X75,0XBD,0X95,
0XC5,0XB6,0XBD,0X95,0XA4,0XF3,0X94,0X71,0X7B,0XAE,0X7B,0XAE,0XA5,0X13,0X94,0X91,
0X84,0X0E,0X94,0X70,0X94,0X70,0XAD,0X34,0XAD,0X14,0X9C,0X71,0X6B,0X0C,0X31,0X45,
0X20,0XC3,0X20,0XA2,0X10,0X40,0X10,0X40,0X10,0X40,0X10,0X40,0X08,0X20,0X08,0X20,
0X08,0X40,0X08,0X40,0X08,0X20,0X10,0X20,0X08,0X00,0X10,0X20,0X10,0X40,0X10,0X40,
0X18,0X61,0X10,0X40,0X10,0X40,0X10,0X40,0X08,0X40,0X00,0X00,0X08,0X40,0X10,0X40,
0X18,0X81,0X10,0X40,0X10,0X61,0X10,0X61,0X18,0X81,0X10,0X60,0X18,0X80,0X10,0X60,
0X10,0X61,0X10,0X61,0X10,0X60,0X10,0X61,0X10,0X40,0X10,0X40,0X10,0X40,0X10,0X40,
0X10,0X40,0X10,0X60,0X10,0X60,0X10,0X40,0X10,0X40,0X10,0X41,0X10,0X61,0X18,0X61,
0X10,0X60,0X10,0X60,0X10,0X60,0X18,0X60,0X18,0X81,0X20,0XA1,0XBD,0X51,0XBD,0X30,
0XA4,0X4D,0XAC,0XCF,0XC5,0X71,0XC5,0X91,0XCD,0X91,0XCD,0XB1,0XCD,0XB1,0XCD,0XB1,
0XBD,0X0F,0XC5,0X71,0XCD,0XB1,0XC5,0X71,0X93,0XCC,0X7A,0XE9,0X7B,0X6B,0XA4,0XB0,
0XC5,0XB5,0XCE,0X17,0XD6,0X78,0XDE,0X99,0XD6,0X79,0XD6,0X78,0XD6,0X98,0XD6,0X78,
0XCE,0X57,0XCD,0XF7,0XC5,0XF7,0XC5,0XD6,0XBD,0X75,0XBD,0X95,0XDE,0X99,0XD6,0X79,
0XD6,0X79,0XD6,0X58,0XD6,0X37,0XCE,0X17,0XAC,0XF2,0X52,0X48,0X20,0XC2,0X18,0X60,
0X41,0XA5,0X52,0X07,0X5A,0X48,0X20,0X81,0X4A,0X47,0XD6,0XB9,0XE6,0XDA,0XDE,0XB9,
0XC5,0XD6,0XB5,0X54,0XA4,0XD2,0X9C,0XD2,0XAD,0X33,0XBD,0XD6,0XB5,0X95,0XB5,0X54,
0XAD,0X13,0XB5,0X75,0XB5,0X95,0XAD,0X34,0XB5,0X95,0X7B,0XCE,0X8C,0X0F,0X9C,0X91,
0X94,0X70,0X94,0X70,0X8C,0X2F,0X9C,0XB2,0X8C,0X30,0X9C,0X92,0X73,0X2C,0X20,0XA2,
0X18,0X82,0X10,0X20,0X18,0X81,0X10,0X60,0X10,0X40,0X10,0X60,0X08,0X20,0X08,0X20,
0X08,0X40,0X08,0X40,0X08,0X40,0X10,0X40,0X08,0X20,0X08,0X40,0X10,0X40,0X10,0X40,
0X10,0X40,0X10,0X60,0X10,0X40,0X10,0X60,0X10,0X40,0X08,0X20,0X08,0X40,0X08,0X40,
0X18,0X81,0X08,0X40,0X10,0X61,0X10,0X61,0X18,0X81,0X18,0X81,0X18,0XA1,0X18,0X80,
0X18,0X81,0X10,0X61,0X10,0X61,0X10,0X61,0X18,0X61,0X10,0X40,0X10,0X40,0X10,0X40,
0X10,0X60,0X10,0X61,0X10,0X60,0X10,0X60,0X10,0X20,0X10,0X40,0X10,0X61,0X18,0X61,
0X10,0X40,0X18,0X60,0X10,0X60,0X10,0X60,0X10,0X60,0X20,0XC1,0XAD,0X11,0XBD,0X51,
0X9C,0X4D,0XBD,0X30,0XAC,0XAE,0XBD,0X30,0XC5,0X71,0XCD,0XB1,0XCD,0XD1,0XD5,0XF2,
0XB4,0XCE,0XCD,0XB2,0XD5,0XD2,0XCD,0X91,0X8B,0X8A,0X7B,0X0A,0X83,0XAC,0XAD,0X12,
0XC5,0XB5,0XCE,0X16,0XCD,0XF7,0XC5,0XF6,0XDE,0X79,0XD6,0X79,0XD6,0X79,0XD6,0X79,
0XD6,0X58,0XCE,0X38,0XCE,0X38,0XBD,0X75,0XB5,0X34,0XC5,0XB6,0XDE,0X99,0XD6,0X58,
0XC5,0XD6,0XCE,0X17,0XE6,0XB9,0XDE,0X99,0XDE,0X99,0XD6,0X58,0XBD,0X95,0X52,0X27,
0X5A,0X68,0X31,0X23,0X39,0X84,0X4A,0X27,0XDE,0XB9,0XDE,0XDA,0XE6,0XBA,0XDE,0XB9,
0XD6,0X58,0XD6,0X79,0XCE,0X37,0XBD,0XD6,0X84,0X0F,0X9C,0XB1,0X9C,0XB1,0XA5,0X13,
0X9C,0XB1,0X94,0X70,0X94,0X91,0X84,0X0F,0X7B,0XAD,0X73,0X8D,0X7B,0XAE,0X94,0X50,
0X8C,0X2F,0X94,0X70,0X9C,0XB1,0X9C,0X91,0X94,0X30,0XA4,0XB2,0X5A,0X8A,0X18,0X82,
0X18,0X61,0X18,0X61,0X18,0X61,0X10,0X61,0X10,0X40,0X10,0X60,0X08,0X40,0X08,0X40,
0X08,0X40,0X08,0X40,0X08,0X40,0X08,0X40,0X08,0X20,0X08,0X20,0X08,0X40,0X10,0X40,
0X10,0X40,0X10,0X60,0X10,0X40,0X10,0X20,0X10,0X61,0X08,0X20,0X08,0X40,0X08,0X40,
0X10,0XA1,0X08,0X40,0X10,0X81,0X10,0X81,0X18,0XA1,0X18,0XA1,0X18,0X80,0X18,0X81,
0X18,0X81,0X10,0X61,0X10,0X60,0X10,0X40,0X10,0X61,0X10,0X40,0X10,0X61,0X10,0X61,
0X10,0X60,0X10,0X61,0X10,0X40,0X10,0X40,0X10,0X40,0X10,0X40,0X10,0X61,0X10,0X61,
0X18,0X81,0X10,0X60,0X10,0X60,0X10,0X60,0X18,0X60,0X18,0X80,0X73,0X4B,0XB5,0X11,
0XA4,0X6D,0XC5,0X51,0XBD,0X30,0XAC,0XAE,0XAC,0X8E,0XBD,0X2F,0XCD,0XB1,0XCD,0XD1,
0XBD,0X2F,0XD5,0XD2,0XD5,0XD2,0XCD,0X91,0X8B,0X6A,0X7B,0X09,0X83,0XAC,0XAD,0X32,
0XBD,0XB5,0XB5,0X74,0XB5,0X74,0XBD,0X96,0XD6,0X58,0XD6,0X59,0XD6,0X59,0XD6,0X59,
0XD6,0X38,0XD6,0X38,0XCE,0X18,0XBD,0X96,0XB5,0X55,0XC5,0XD7,0XA4,0XF3,0XCE,0X17,
0XD6,0X58,0XDE,0XB9,0XE6,0XB9,0XE6,0XB9,0XDE,0X99,0XDE,0X98,0XD6,0X78,0XC5,0XD5,
0X31,0X44,0X20,0XA1,0X20,0XC2,0XD6,0X58,0XDE,0X9A,0XDE,0X79,0XD6,0X58,0XD6,0X38,
0XC5,0XF7,0XC5,0XD7,0XCE,0X17,0XCE,0X37,0XD6,0X78,0XBD,0XD5,0X8C,0X2F,0X84,0X2F,
0X94,0X70,0X7B,0XEE,0X73,0X8C,0X73,0X6C,0X73,0X6C,0X73,0X6C,0X73,0X6D,0X83,0XCE,
0X83,0XCE,0X7B,0X6C,0X6B,0X4C,0X7B,0X8D,0X94,0X71,0X8B,0XEF,0X4A,0X08,0X20,0XA2,
0X18,0X61,0X18,0X61,0X18,0X81,0X10,0X40,0X08,0X40,0X10,0X60,0X08,0X40,0X08,0X40,
0X08,0X40,0X08,0X40,0X08,0X40,0X08,0X40,0X08,0X20,0X08,0X40,0X08,0X40,0X10,0X20,
0X10,0X40,0X10,0X60,0X10,0X61,0X10,0X40,0X10,0X40,0X08,0X20,0X08,0X40,0X08,0X40,
0X10,0X81,0X10,0X81,0X10,0X81,0X10,0X80,0X10,0X80,0X10,0X81,0X18,0X81,0X18,0X61,
0X18,0X61,0X10,0X61,0X10,0X60,0X10,0X60,0X10,0X61,0X10,0X61,0X10,0X61,0X10,0X61,
0X10,0X40,0X10,0X40,0X10,0X40,0X08,0X40,0X08,0X40,0X08,0X40,0X08,0X60,0X08,0X60,
0X10,0X80,0X10,0X60,0X18,0X60,0X18,0X60,0X18,0X60,0X18,0X80,0X31,0X43,0XAC,0XF1,
0XA4,0X8E,0XBD,0X51,0XBD,0X51,0XC5,0X71,0XBD,0X30,0X9C,0X4C,0XB4,0XEE,0XB4,0XEE,
0XC5,0X51,0XD5,0XD3,0XD5,0XD3,0XCD,0X92,0X7A,0XE9,0X83,0X4B,0X8B,0XED,0XA4,0XD1,
0XC5,0XB5,0XCE,0X17,0XCE,0X17,0XC5,0XF7,0XD6,0X58,0XD6,0X59,0XD6,0X59,0XDE,0X79,
0XDE,0X79,0XDE,0X7A,0XCE,0X18,0XCD,0XF7,0XC5,0XF7,0XDE,0X99,0XDE,0X9A,0XDE,0XBA,
0XD6,0X79,0XD6,0X38,0XDE,0X79,0XD6,0X58,0XDE,0X79,0XDE,0X99,0XDE,0XB9,0XDE,0X99,
0XB5,0X53,0X18,0XA1,0X6B,0X0B,0XD6,0X79,0XD6,0X59,0XD6,0X59,0XD6,0X59,0XD6,0X38,
0XD6,0X58,0XC5,0XF7,0XBD,0XB6,0XAD,0X54,0XB5,0X95,0XBD,0XF6,0XCE,0X37,0X9C,0XB1,
0X8C,0X4F,0X7B,0XAD,0X73,0X8C,0X73,0X8C,0X73,0X8C,0X6B,0X4B,0X6B,0X2B,0X6B,0X0A,
0X6A,0XEB,0X73,0X6D,0X73,0X4C,0X8C,0X2F,0X8C,0X10,0X6B,0X2C,0X31,0X24,0X18,0X61,
0X10,0X40,0X10,0X61,0X10,0X81,0X10,0X60,0X08,0X40,0X08,0X40,0X08,0X40,0X08,0X40,
0X08,0X40,0X08,0X40,0X08,0X40,0X08,0X40,0X08,0X20,0X08,0X40,0X08,0X40,0X08,0X40,
0X10,0X60,0X10,0X60,0X10,0X61,0X18,0X61,0X10,0X40,0X08,0X20,0X08,0X20,0X00,0X20,
0X10,0X81,0X10,0X81,0X08,0X60,0X08,0X60,0X08,0X60,0X08,0X40,0X10,0X60,0X18,0X81,
0X18,0X61,0X10,0X61,0X10,0X60,0X10,0X60,0X10,0X61,0X10,0X61,0X18,0X61,0X10,0X61,
0X10,0X40,0X10,0X40,0X08,0X40,0X08,0X40,0X08,0X60,0X08,0X40,0X08,0X60,0X08,0X60,
0X10,0X80,0X10,0X60,0X18,0X60,0X18,0X60,0X18,0X60,0X18,0X80,0X28,0XC2,0XB5,0X11,
0X94,0X2C,0XBD,0X51,0XBD,0X71,0XC5,0X71,0XBD,0X50,0XC5,0X70,0XB5,0X0F,0X93,0XEA,
0XB4,0XCF,0XD5,0XD3,0XD5,0XF3,0XB4,0XD0,0X7A,0XE9,0X83,0X4B,0X83,0XAC,0X9C,0X90,
0XB5,0X53,0XBD,0XB5,0XC5,0XD6,0XD6,0X58,0XCE,0X38,0XCE,0X18,0XCD,0XF7,0XCE,0X18,
0XD6,0X38,0XC5,0XD7,0X9C,0X71,0XDE,0X9A,0XEF,0X1B,0XE6,0XDA,0XDE,0X99,0XBD,0XB6,
0XAD,0X13,0XD6,0X38,0XDE,0X99,0XE6,0XBA,0XDE,0X99,0XDE,0X99,0XDE,0X99,0XB5,0X54,
0XAD,0X13,0X62,0XCA,0X94,0X30,0XBD,0XB6,0XC5,0XB7,0XCD,0XF7,0XCE,0X18,0XD6,0X38,
0XCE,0X38,0XD6,0X99,0XD6,0X99,0XCE,0X38,0XBD,0XB5,0X94,0X91,0XB5,0X74,0XA4,0XF2,
0X84,0X0F,0X7B,0XAD,0X73,0X8C,0X73,0X6C,0X73,0X6C,0X6B,0X4B,0X6B,0X2B,0X6B,0X0A,
0X73,0X4C,0X83,0XCE,0X83,0XCE,0X94,0X50,0XAD,0X34,0X62,0XCA,0X20,0XC2,0X18,0X82,
0X20,0XA2,0X10,0X81,0X10,0X60,0X08,0X60,0X08,0X60,0X08,0X60,0X08,0X60,0X08,0X60,
0X08,0X60,0X08,0X40,0X08,0X40,0X08,0X40,0X08,0X20,0X08,0X40,0X08,0X40,0X08,0X40,
0X10,0X60,0X10,0X60,0X10,0X61,0X18,0X61,0X10,0X40,0X08,0X20,0X08,0X20,0X00,0X20,
0X18,0XA2,0X08,0X61,0X10,0X81,0X10,0X81,0X08,0X60,0X08,0X40,0X10,0X40,0X10,0X61,
0X10,0X61,0X10,0X61,0X10,0X61,0X10,0X61,0X10,0X40,0X10,0X40,0X10,0X40,0X10,0X40,
0X10,0X40,0X10,0X40,0X10,0X40,0X08,0X40,0X08,0X40,0X08,0X60,0X08,0X60,0X10,0X60,
0X10,0X60,0X10,0X40,0X18,0X81,0X18,0X60,0X18,0X60,0X10,0X60,0X20,0XC2,0X8B,0XED,
0X9C,0X6E,0XBD,0X51,0XBD,0X71,0XBD,0X50,0XBD,0X30,0XCD,0XF2,0XCD,0XD1,0X8B,0XA9,
0XA4,0X6D,0XB4,0XCF,0XCD,0X92,0X9B,0XEC,0X72,0XC9,0X7B,0X4B,0X83,0XCD,0X9C,0XD1,
0XAD,0X12,0XAD,0X33,0XBD,0X95,0XC5,0XD6,0XBD,0X96,0XBD,0X75,0XBD,0X96,0XC5,0XB6,
0XBD,0X96,0XA4,0XB2,0XE6,0XDB,0XE6,0XBA,0XD6,0X38,0XC5,0XD6,0XBD,0X95,0XDE,0X79,
0XDE,0X79,0XE6,0XDB,0XE6,0XDB,0XD6,0X38,0XD6,0X58,0XC5,0XD7,0XBD,0X75,0XBD,0X95,
0X9C,0X71,0X4A,0X07,0X9C,0X71,0XC5,0XB6,0XC5,0XB7,0XBD,0X96,0XAC,0XF3,0XAD,0X34,
0XAD,0X14,0XAD,0X34,0XBD,0XB6,0XD6,0X99,0XD6,0XB9,0XD6,0X99,0XAD,0X33,0XBD,0XB5,
0XBD,0XD6,0X83,0XEE,0X73,0X8C,0X73,0X8C,0X6B,0X4B,0X73,0X8C,0X73,0X6C,0X6B,0X2B,
0X73,0X2C,0X7B,0XAE,0X7B,0X8D,0X94,0X50,0X83,0XAE,0X5A,0X69,0X28,0XE3,0X10,0X41,
0X10,0X41,0X10,0X60,0X10,0X60,0X08,0X60,0X10,0X60,0X08,0X60,0X08,0X60,0X08,0X40,
0X08,0X40,0X08,0X60,0X08,0X40,0X08,0X40,0X08,0X40,0X08,0X40,0X08,0X40,0X08,0X40,
0X10,0X60,0X10,0X40,0X10,0X40,0X10,0X40,0X10,0X40,0X08,0X20,0X08,0X40,0X08,0X00,
0X18,0XC2,0X08,0X40,0X08,0X60,0X08,0X60,0X10,0X60,0X08,0X40,0X10,0X40,0X10,0X41,
0X10,0X61,0X10,0X61,0X10,0X61,0X10,0X61,0X10,0X40,0X10,0X20,0X10,0X40,0X10,0X40,
0X10,0X40,0X10,0X40,0X10,0X40,0X08,0X60,0X08,0X60,0X08,0X60,0X08,0X60,0X10,0X60,
0X10,0X60,0X10,0X60,0X10,0X60,0X10,0X40,0X18,0X60,0X18,0X81,0X18,0X81,0X39,0X22,
0X94,0X0C,0XBD,0X51,0XBD,0X51,0XBD,0X30,0XBD,0X50,0XCD,0XD2,0XCD,0XB1,0XA4,0X6C,
0XBD,0X10,0XBD,0X11,0XAC,0X8F,0X6A,0X87,0X6A,0X88,0X7B,0X2A,0X83,0XCD,0X9C,0XD1,
0XB5,0X53,0XB5,0X74,0XB5,0X54,0XB5,0X54,0XAD,0X14,0XAC,0XF3,0XBD,0X96,0XCD,0XF7,
0XCE,0X18,0XDE,0X79,0XD6,0X59,0XD6,0X38,0XD6,0X59,0XE6,0XDA,0XE6,0XDA,0XDE,0X79,
0XE6,0XDA,0XDE,0X79,0XBD,0X75,0XC5,0XD7,0XB5,0X55,0XBD,0X96,0XC5,0XB6,0XAD,0X13,
0X83,0XAE,0X39,0X86,0X83,0XAE,0XA4,0XB2,0XAD,0X14,0XBD,0X75,0XAC,0XF3,0XBD,0X95,
0XB5,0X55,0XB5,0X75,0XAD,0X55,0X9C,0XB2,0X9C,0XB1,0XBD,0XB5,0XC6,0X17,0XB5,0X95,
0X7B,0XAD,0X8C,0X30,0XAD,0X53,0X8C,0X4F,0XA5,0X12,0X7B,0XCD,0X73,0X6C,0X6B,0X0B,
0X73,0X4C,0X8C,0X0F,0X9C,0XB1,0X7B,0XAD,0X73,0X4D,0X18,0X82,0X10,0X61,0X18,0X61,
0X10,0X41,0X10,0X60,0X10,0X80,0X08,0X60,0X10,0X60,0X08,0X60,0X08,0X60,0X08,0X40,
0X08,0X40,0X08,0X60,0X08,0X40,0X08,0X40,0X08,0X20,0X08,0X20,0X08,0X40,0X08,0X40,
0X10,0X60,0X10,0X40,0X10,0X40,0X10,0X40,0X10,0X40,0X08,0X20,0X08,0X40,0X08,0X20,
0X18,0XC2,0X08,0X40,0X08,0X60,0X08,0X40,0X08,0X40,0X08,0X40,0X08,0X40,0X08,0X40,
0X10,0X61,0X10,0X41,0X10,0X41,0X10,0X41,0X10,0X40,0X10,0X40,0X10,0X40,0X10,0X40,
0X10,0X40,0X10,0X40,0X10,0X40,0X10,0X40,0X10,0X20,0X10,0X40,0X10,0X60,0X10,0X60,
0X08,0X40,0X10,0X40,0X10,0X60,0X10,0X40,0X10,0X40,0X18,0X40,0X10,0X40,0X20,0XA0,
0X7B,0X6B,0XB5,0X11,0XB5,0X30,0XB4,0XEF,0XBD,0X4F,0XC5,0X91,0XBD,0X50,0XAC,0X8E,
0XBD,0X30,0XC5,0X51,0XBD,0X10,0X93,0XCB,0X72,0XC8,0X7B,0X2B,0X8C,0X0E,0XAD,0X13,
0XB5,0X55,0XBD,0X96,0XBD,0X75,0XAC,0XF3,0XAC,0XF3,0XBD,0X75,0XCD,0XF7,0XD6,0X59,
0XCD,0XF7,0XD6,0X38,0XDE,0X9A,0XDE,0X9A,0XE6,0XBA,0XDE,0X9A,0XCE,0X17,0XC5,0XB6,
0XBD,0X95,0XC5,0XF6,0XB5,0X75,0XBD,0XB6,0XC5,0XF7,0XB5,0X95,0XAD,0X13,0X8C,0X0F,
0X41,0XE7,0X20,0XA2,0X39,0X65,0X73,0X2C,0X94,0X51,0XA4,0XB2,0XA4,0XD3,0XAD,0X14,
0XB5,0X34,0XCE,0X17,0XCD,0XF7,0XBD,0X96,0XAD,0X14,0X8C,0X10,0X94,0X51,0XAD,0X14,
0X94,0X50,0X73,0X4C,0X6B,0X4B,0X73,0X6C,0XB5,0X74,0X8C,0X2F,0X7B,0X8D,0X94,0X70,
0X6B,0X4B,0X8C,0X4F,0X84,0X0F,0X6B,0X2C,0X39,0XA6,0X10,0X41,0X10,0X41,0X10,0X41,
0X10,0X61,0X08,0X61,0X08,0X60,0X08,0X60,0X08,0X40,0X08,0X40,0X08,0X40,0X08,0X40,
0X08,0X40,0X08,0X60,0X08,0X40,0X08,0X20,0X08,0X20,0X08,0X20,0X08,0X40,0X08,0X40,
0X08,0X40,0X08,0X40,0X10,0X40,0X10,0X40,0X10,0X40,0X10,0X20,0X08,0X20,0X08,0X20,
0X18,0XC2,0X08,0X40,0X08,0X60,0X08,0X40,0X08,0X60,0X08,0X60,0X08,0X40,0X08,0X40,
0X10,0X40,0X10,0X41,0X10,0X61,0X10,0X41,0X10,0X40,0X10,0X40,0X10,0X61,0X10,0X40,
0X10,0X40,0X10,0X40,0X10,0X40,0X10,0X40,0X10,0X20,0X10,0X40,0X10,0X60,0X08,0X40,
0X08,0X60,0X10,0X60,0X10,0X60,0X10,0X40,0X10,0X40,0X10,0X40,0X18,0X40,0X18,0X60,
0X39,0X43,0XA4,0X8F,0XAC,0XD0,0XB4,0XEF,0XBD,0X50,0XC5,0X92,0XB4,0XEF,0XAC,0XAE,
0XC5,0X51,0XCD,0X72,0XC5,0X71,0X9C,0X2C,0X6A,0XC8,0X7B,0X2A,0X94,0X0E,0XA4,0XF2,
0XBD,0X75,0XBD,0X96,0XAD,0X14,0XAD,0X14,0XA4,0XD3,0XCD,0XF7,0XD6,0X38,0XD6,0X59,
0XC5,0XD7,0XDE,0X79,0XE6,0XDB,0XDE,0X79,0XCE,0X18,0XB5,0X54,0XC5,0XD6,0XCD,0XF7,
0XD6,0X38,0XD6,0X38,0XD6,0X58,0XC5,0XD7,0XB5,0X75,0XAD,0X54,0X94,0X91,0X5A,0XCA,
0X39,0X85,0X31,0X44,0X39,0X65,0X41,0XA6,0X73,0X4D,0X9C,0X92,0X94,0X51,0X9C,0X92,
0XAC,0XF3,0XAC,0XF3,0XAC,0XF3,0XAC,0XF3,0XBD,0X75,0XCD,0XF7,0X94,0X31,0X94,0X30,
0X94,0X50,0X6A,0XEB,0X6B,0X2B,0X6B,0X2B,0X6B,0X4B,0X9C,0XD2,0XAD,0X33,0X73,0X6C,
0XA5,0X12,0X94,0X90,0X84,0X0F,0X7B,0X8E,0X29,0X24,0X10,0X20,0X10,0X41,0X10,0X40,
0X08,0X40,0X08,0X60,0X10,0X81,0X08,0X60,0X08,0X40,0X08,0X40,0X08,0X40,0X08,0X40,
0X08,0X40,0X08,0X40,0X08,0X40,0X08,0X40,0X08,0X20,0X08,0X20,0X08,0X40,0X08,0X40,
0X08,0X40,0X08,0X40,0X10,0X40,0X10,0X40,0X10,0X40,0X08,0X20,0X08,0X20,0X08,0X20,
0X18,0XE2,0X08,0X40,0X08,0X60,0X08,0X40,0X08,0X60,0X08,0X60,0X08,0X60,0X08,0X60,
0X08,0X40,0X10,0X41,0X10,0X61,0X10,0X61,0X10,0X61,0X10,0X61,0X18,0X61,0X18,0X61,
0X10,0X40,0X10,0X40,0X10,0X40,0X10,0X40,0X10,0X20,0X08,0X20,0X10,0X40,0X08,0X40,
0X08,0X60,0X10,0X60,0X10,0X60,0X10,0X40,0X10,0X40,0X10,0X40,0X10,0X40,0X20,0XE2,
0X20,0XA1,0X49,0XC5,0X94,0X2E,0XA4,0X8E,0XB5,0X31,0XBD,0X71,0XA4,0X6D,0XB4,0XEF,
0XBD,0X31,0XC5,0X51,0XC5,0X51,0X9C,0X2D,0X6A,0XA7,0X7B,0X4B,0X9C,0X4F,0XB5,0X54,
0XBD,0X75,0XAD,0X14,0XC5,0XB6,0XE6,0XDB,0XCE,0X18,0XA4,0XD3,0XBD,0X75,0XD6,0X38,
0XD6,0X59,0XDE,0X9A,0XD6,0X38,0XBD,0X96,0XAD,0X14,0XD6,0X38,0XD6,0X79,0XD6,0X38,
0XCE,0X18,0XC5,0XD6,0XA4,0XD2,0XB5,0X54,0XA4,0XF3,0X7B,0XAD,0X52,0X89,0X52,0X89,
0X42,0X07,0X4A,0X48,0X52,0X69,0X52,0X69,0X4A,0X08,0X73,0X4D,0X8C,0X10,0X94,0X51,
0XA4,0XD3,0XA4,0XB2,0X8B,0XEF,0X83,0XAE,0XAD,0X14,0XAD,0X14,0XBD,0X96,0X94,0X71,
0XA4,0XF3,0X7B,0XAD,0X7B,0XAD,0X73,0X6C,0X6B,0X4B,0X6B,0X4C,0XA4,0XF2,0X7B,0XAD,
0X9C,0XB1,0X84,0X0E,0XAD,0X33,0X62,0XEA,0X10,0X41,0X10,0X41,0X10,0X20,0X10,0X40,
0X08,0X40,0X08,0X60,0X08,0X80,0X08,0X60,0X08,0X40,0X08,0X40,0X08,0X40,0X08,0X40,
0X08,0X40,0X08,0X20,0X08,0X20,0X08,0X20,0X00,0X20,0X08,0X20,0X08,0X40,0X08,0X60,
0X08,0X40,0X08,0X40,0X10,0X40,0X10,0X40,0X10,0X40,0X08,0X20,0X08,0X00,0X08,0X20,
0X18,0XE1,0X08,0X40,0X08,0X60,0X08,0X40,0X08,0X40,0X08,0X40,0X08,0X60,0X08,0X60,
0X08,0X40,0X10,0X41,0X10,0X61,0X10,0X61,0X10,0X61,0X10,0X61,0X10,0X61,0X10,0X61,
0X10,0X40,0X10,0X40,0X10,0X40,0X10,0X40,0X10,0X40,0X08,0X20,0X10,0X40,0X08,0X40,
0X08,0X60,0X10,0X60,0X10,0X60,0X08,0X20,0X10,0X60,0X10,0X60,0X10,0X40,0X10,0X20,
0X18,0X61,0X28,0XE2,0X5A,0X67,0X94,0X0D,0XAC,0XF0,0XBD,0X31,0X9C,0X2C,0XB4,0XCF,
0XB4,0XAF,0XC5,0X31,0XC5,0X30,0X9C,0X2C,0X6A,0XC8,0X83,0X8C,0XA4,0XB1,0XCE,0X17,
0XE6,0XBA,0XDE,0X79,0XBD,0X96,0XBD,0X75,0XC5,0XB6,0XAC,0XF3,0XCD,0XF7,0XBD,0X96,
0XD6,0X38,0XD6,0X38,0XCD,0XF7,0XB5,0X55,0XD6,0X38,0XCE,0X18,0XB5,0X34,0XAD,0X14,
0XBD,0X75,0XAC,0XF3,0XB5,0X54,0XA4,0XB2,0X7B,0X8E,0X5A,0XCA,0X52,0X89,0X6B,0X2C,
0X73,0X6D,0X84,0X0F,0X84,0X0F,0X6B,0X4C,0X5A,0XAA,0X5A,0XAA,0X5A,0X8A,0X8B,0XEF,
0X83,0XAE,0X9C,0X71,0X94,0X51,0X8C,0X10,0X8C,0X10,0X9C,0X71,0X9C,0X92,0XBD,0X96,
0XAD,0X13,0XA4,0XB2,0X6B,0X4B,0X7B,0XAD,0X83,0XEE,0X6B,0X2B,0X73,0X4B,0X83,0XEE,
0X7B,0XAD,0X7B,0XEE,0X94,0X90,0X31,0X43,0X52,0X48,0X18,0X82,0X10,0X20,0X10,0X40,
0X10,0X60,0X08,0X60,0X08,0X60,0X08,0X40,0X08,0X40,0X08,0X40,0X08,0X40,0X08,0X40,
0X08,0X40,0X10,0X40,0X08,0X40,0X08,0X20,0X00,0X20,0X08,0X20,0X08,0X40,0X08,0X60,
0X08,0X40,0X08,0X40,0X10,0X40,0X10,0X40,0X10,0X40,0X08,0X20,0X08,0X00,0X08,0X20,
0X18,0XE1,0X08,0X60,0X08,0X40,0X08,0X40,0X08,0X40,0X08,0X40,0X08,0X40,0X08,0X40,
0X08,0X40,0X10,0X60,0X10,0X61,0X10,0X61,0X18,0X61,0X10,0X41,0X10,0X20,0X10,0X20,
0X10,0X40,0X10,0X40,0X10,0X40,0X10,0X40,0X10,0X40,0X08,0X20,0X08,0X40,0X08,0X60,
0X08,0X60,0X10,0X60,0X10,0X60,0X08,0X40,0X10,0X60,0X10,0X40,0X10,0X40,0X10,0X40,
0X10,0X41,0X18,0X61,0X28,0XE2,0X7B,0X6B,0X8C,0X0D,0XAC,0XAF,0XA4,0X8E,0XA4,0X4E,
0XB4,0XF0,0XBD,0X10,0XB4,0XCF,0XAC,0X8E,0XC5,0X73,0XAC,0XF1,0XB4,0XF2,0XC5,0XB6,
0XC5,0XD6,0XBD,0X95,0XBD,0X55,0XC5,0XB6,0XB5,0X34,0X94,0X50,0X9C,0X71,0XAD,0X13,
0XC5,0XB6,0XD6,0X38,0XC5,0XB6,0XDE,0X79,0XB5,0X34,0XA4,0XB2,0XBD,0X76,0X9C,0X71,
0XAD,0X34,0XA4,0XD2,0X8B,0XEF,0X62,0XCA,0X6B,0X2C,0X7B,0XAD,0X83,0XEE,0X8C,0X2F,
0X8C,0X2F,0X94,0X70,0XAD,0X34,0X94,0X91,0X83,0XEF,0X73,0X2C,0X5A,0X8A,0X6A,0XEB,
0X7B,0X8E,0X7B,0X8E,0X8B,0XEF,0X73,0X2C,0X7B,0X8E,0X73,0X4D,0XA4,0XB2,0X8C,0X30,
0XC5,0XD6,0XAD,0X13,0X73,0X8C,0XA4,0XF2,0X7B,0XCD,0X8C,0X4F,0X84,0X0E,0X8C,0X4F,
0XA5,0X12,0XB5,0X74,0X73,0X6C,0X29,0X03,0X62,0XCA,0X41,0XC7,0X29,0X03,0X18,0XA1,
0X08,0X60,0X08,0X60,0X08,0X60,0X10,0X61,0X08,0X40,0X08,0X40,0X08,0X40,0X08,0X40,
0X08,0X40,0X08,0X20,0X08,0X40,0X08,0X20,0X00,0X00,0X08,0X20,0X08,0X60,0X08,0X60,
0X08,0X40,0X08,0X40,0X08,0X60,0X10,0X60,0X08,0X40,0X08,0X40,0X08,0X00,0X08,0X00,
0X18,0XE1,0X08,0X60,0X08,0X60,0X08,0X60,0X08,0X40,0X08,0X40,0X08,0X40,0X08,0X40,
0X08,0X40,0X10,0X60,0X10,0X60,0X10,0X60,0X18,0X61,0X10,0X41,0X10,0X20,0X10,0X20,
0X10,0X40,0X10,0X40,0X10,0X40,0X10,0X40,0X10,0X40,0X08,0X20,0X08,0X20,0X08,0X40,
0X08,0X60,0X08,0X40,0X08,0X40,0X08,0X40,0X10,0X60,0X10,0X40,0X10,0X40,0X10,0X61,
0X10,0X41,0X18,0X40,0X18,0X60,0X28,0XE1,0X8C,0X0D,0X94,0X0D,0X94,0X2D,0XA4,0XAF,
0XC5,0X93,0XDE,0X14,0XBD,0X10,0XA4,0X4D,0XA4,0X6F,0X94,0X2E,0XA4,0XB1,0XAC,0XF2,
0XA4,0XF2,0XBD,0X95,0XC5,0XD6,0XB5,0X54,0X9C,0X50,0X94,0X50,0X94,0X2F,0XB5,0X34,
0XBD,0X75,0XA4,0XB2,0XC5,0XB6,0XB5,0X34,0XA4,0XB2,0XAC,0XF3,0X83,0XAF,0XB5,0X34,
0X9C,0X71,0X83,0XCE,0X7B,0X8D,0X6B,0X0B,0X83,0XCE,0X8B,0XEF,0X9C,0XB1,0XA4,0XD2,
0X9C,0XB1,0XA4,0XF2,0XAD,0X54,0X9C,0XB1,0X8C,0X0F,0X7B,0XAE,0X6B,0X0C,0X6B,0X0C,
0X73,0X2C,0X73,0X4D,0X62,0XAA,0X83,0XAE,0X8B,0XEF,0X8C,0X10,0X6B,0X2C,0X9C,0X91,
0X9C,0X91,0XAD,0X13,0X94,0X71,0X73,0X6C,0XAD,0X53,0X8C,0X2F,0X84,0X0E,0X9C,0XB1,
0X8C,0X2F,0X7B,0XCD,0X73,0X4B,0X31,0X44,0X20,0XA2,0X52,0X49,0X18,0X81,0X29,0X43,
0X10,0X80,0X08,0X40,0X08,0X20,0X08,0X20,0X08,0X40,0X08,0X40,0X08,0X40,0X08,0X40,
0X08,0X40,0X00,0X20,0X00,0X20,0X08,0X20,0X00,0X20,0X00,0X20,0X08,0X40,0X08,0X60,
0X08,0X40,0X08,0X40,0X08,0X60,0X08,0X60,0X08,0X40,0X08,0X40,0X00,0X20,0X00,0X20,
0X18,0XC1,0X08,0X40,0X10,0X60,0X08,0X40,0X08,0X40,0X08,0X40,0X08,0X40,0X08,0X40,
0X10,0X60,0X10,0X60,0X10,0X60,0X18,0X60,0X18,0X61,0X10,0X40,0X10,0X20,0X10,0X40,
0X08,0X20,0X08,0X20,0X08,0X20,0X08,0X20,0X08,0X20,0X08,0X00,0X08,0X20,0X08,0X20,
0X08,0X40,0X08,0X40,0X08,0X40,0X08,0X40,0X10,0X60,0X10,0X60,0X08,0X20,0X10,0X40,
0X08,0X20,0X10,0X40,0X18,0X81,0X29,0X22,0X94,0X6F,0X94,0X2E,0XA4,0XB0,0X94,0X2D,
0XAC,0XB0,0XAC,0X8F,0XB4,0XF0,0XB4,0XEF,0X93,0XCC,0X7B,0X2A,0XB5,0X12,0XA4,0XB1,
0X7B,0XAD,0X94,0X2F,0X8C,0X0F,0X9C,0X91,0X8B,0XEE,0X94,0X50,0XBD,0X74,0XA4,0XD2,
0X8C,0X30,0XA4,0XB2,0X83,0XCF,0X83,0XCF,0X83,0XCF,0X8B,0XEF,0X8C,0X10,0X9C,0X71,
0X83,0XAE,0X83,0XCE,0X8B,0XEE,0X83,0XEE,0X94,0X50,0X94,0X50,0X9C,0X91,0XA4,0XD2,
0XAD,0X33,0XA4,0XD2,0X9C,0XB1,0X94,0X70,0X8C,0X0F,0X8C,0X30,0X83,0XEF,0X6B,0X0B,
0X6B,0X0B,0X73,0X2C,0X6B,0X2C,0X8C,0X0F,0X7B,0X8D,0X94,0X50,0XB5,0X54,0X7B,0X8D,
0X8C,0X0F,0X9C,0X90,0X94,0X71,0XA4,0XD2,0X7B,0X8D,0XAD,0X33,0X84,0X0E,0X83,0XEE,
0X6B,0X4B,0X4A,0X27,0X29,0X03,0X5A,0X89,0X18,0XA2,0X10,0X41,0X10,0X40,0X31,0X64,
0X31,0X84,0X08,0X20,0X08,0X20,0X08,0X20,0X08,0X20,0X08,0X20,0X08,0X40,0X08,0X40,
0X08,0X40,0X08,0X20,0X00,0X00,0X08,0X20,0X08,0X20,0X00,0X20,0X08,0X40,0X08,0X40,
0X08,0X40,0X08,0X40,0X10,0X60,0X08,0X60,0X08,0X40,0X08,0X40,0X00,0X20,0X00,0X20,
0X20,0XC1,0X10,0X40,0X10,0X60,0X10,0X60,0X10,0X40,0X08,0X40,0X08,0X40,0X08,0X40,
0X08,0X40,0X10,0X60,0X10,0X60,0X10,0X60,0X10,0X61,0X10,0X20,0X10,0X20,0X10,0X20,
0X08,0X20,0X08,0X20,0X08,0X20,0X08,0X20,0X08,0X20,0X10,0X00,0X10,0X20,0X10,0X40,
0X10,0X40,0X08,0X40,0X08,0X40,0X08,0X40,0X08,0X40,0X08,0X40,0X00,0X00,0X18,0XA1,
0X39,0XA5,0X52,0X68,0X31,0X64,0X6B,0X2B,0X62,0XEA,0X8C,0X0E,0X9C,0X4F,0X94,0X0D,
0XA4,0X8F,0XC5,0X53,0XC5,0X51,0XC5,0X51,0XAC,0XAF,0X62,0X87,0X73,0X2A,0X83,0XCD,
0X83,0XEE,0X83,0XAD,0X83,0XAD,0X94,0X50,0X83,0XCD,0XAD,0X33,0XA4,0XF2,0X8B,0XEE,
0X8B,0XEF,0X9C,0X92,0X94,0X30,0X8C,0X10,0XB5,0X34,0XA4,0XB2,0X8C,0X0F,0X9C,0X91,
0X83,0XEE,0X8C,0X2F,0X94,0X70,0X94,0X4F,0X94,0X70,0X8C,0X0E,0X94,0X70,0X94,0X70,
0X94,0X50,0X83,0XEE,0X84,0X0E,0X83,0XEE,0X83,0XCE,0X83,0XEE,0X7B,0X8D,0X73,0X2B,
0X6B,0X0B,0X73,0X2B,0X73,0X2C,0X8C,0X0F,0X6A,0XEB,0X7B,0X6D,0X73,0X4C,0X83,0XCE,
0X7B,0XAD,0X73,0X4B,0XAC,0XF3,0X94,0X50,0XAD,0X13,0X7B,0X8C,0XA5,0X12,0X6B,0X4B,
0X52,0X88,0X10,0X80,0X52,0X48,0X10,0X40,0X49,0XE7,0X18,0X61,0X18,0X81,0X10,0X60,
0X41,0XA5,0X29,0X23,0X08,0X20,0X08,0X60,0X08,0X40,0X08,0X20,0X08,0X40,0X10,0X40,
0X08,0X20,0X08,0X20,0X08,0X20,0X08,0X20,0X08,0X20,0X08,0X20,0X08,0X40,0X10,0X40,
0X10,0X40,0X10,0X40,0X10,0X60,0X08,0X60,0X08,0X40,0X08,0X40,0X00,0X20,0X08,0X20,
0X18,0XA1,0X10,0X80,0X10,0X60,0X10,0X60,0X10,0X40,0X08,0X40,0X08,0X40,0X08,0X40,
0X08,0X40,0X10,0X60,0X10,0X60,0X10,0X60,0X10,0X60,0X10,0X40,0X10,0X20,0X10,0X20,
0X10,0X20,0X08,0X40,0X08,0X40,0X08,0X20,0X08,0X20,0X08,0X40,0X08,0X20,0X08,0X40,
0X08,0X20,0X08,0X40,0X08,0X20,0X08,0X20,0X31,0XA5,0X29,0X44,0X10,0X60,0X31,0X44,
0X4A,0X48,0X29,0X44,0X18,0XA2,0X10,0X61,0X4A,0X48,0XAD,0X12,0XA4,0XB1,0X94,0X2E,
0X8B,0XCD,0X8B,0XAB,0X9C,0X2D,0XAC,0X8E,0XAC,0X8F,0X93,0XEC,0X6A,0XA8,0X73,0X0A,
0X8B,0XCD,0X83,0XAD,0X83,0XAD,0X83,0XAD,0XC5,0XB5,0XA4,0XB1,0X8C,0X0E,0X8B,0XEE,
0XA4,0XB1,0X83,0XCE,0X8C,0X0F,0X94,0X50,0X9C,0X91,0X8C,0X0F,0X9C,0X91,0XA4,0XD1,
0X8C,0X0F,0X8C,0X2F,0X94,0X70,0X94,0X4F,0X8C,0X2F,0X94,0X70,0X8C,0X4F,0X8C,0X2F,
0X73,0X8C,0X73,0X6C,0X7B,0XED,0X7B,0XCD,0X73,0X8C,0X7B,0X8C,0X73,0X6C,0X73,0X4C,
0X6B,0X2B,0X6B,0X2B,0X73,0X6C,0X83,0XEE,0X73,0X4B,0X6B,0X4B,0X83,0XEE,0X94,0X70,
0X7B,0X8C,0X94,0X70,0X73,0X4C,0X9C,0X91,0X94,0X30,0X83,0XEE,0X6B,0X2B,0XA4,0XD2,
0X29,0X23,0X10,0X40,0X10,0X60,0X20,0XC2,0X41,0XE6,0X39,0X86,0X31,0X45,0X10,0X40,
0X18,0X81,0X28,0XE3,0X29,0X03,0X10,0X41,0X08,0X20,0X08,0X20,0X08,0X40,0X08,0X40,
0X10,0X40,0X10,0X40,0X08,0X00,0X08,0X20,0X08,0X20,0X08,0X20,0X10,0X40,0X08,0X40,
0X08,0X40,0X08,0X40,0X08,0X40,0X08,0X40,0X08,0X40,0X08,0X40,0X00,0X00,0X08,0X20,
0X18,0X80,0X18,0X81,0X10,0X40,0X10,0X40,0X10,0X40,0X08,0X40,0X08,0X40,0X08,0X40,
0X08,0X40,0X10,0X60,0X10,0X60,0X08,0X40,0X08,0X20,0X08,0X20,0X10,0X20,0X10,0X20,
0X08,0X20,0X08,0X40,0X08,0X40,0X08,0X40,0X08,0X20,0X08,0X40,0X08,0X20,0X08,0X40,
0X18,0X80,0X29,0X03,0X00,0X00,0X10,0X81,0X08,0X40,0X31,0X85,0X20,0XE3,0X08,0X40,
0X10,0X81,0X31,0X65,0X4A,0X48,0X18,0XA1,0X31,0X85,0X83,0XCD,0X8C,0X0E,0X94,0X0E,
0X94,0X0E,0X8B,0XCB,0X8B,0XAB,0X7B,0X29,0X8B,0XAB,0X93,0XEC,0X7B,0X29,0X83,0X8C,
0X7B,0X4B,0X83,0X8C,0X83,0XCD,0XC5,0XB5,0XBD,0X54,0X94,0X4F,0X83,0XCD,0X94,0X2F,
0XA4,0XB1,0X8C,0X0F,0X8C,0X0F,0XAD,0X13,0X94,0X50,0X8C,0X0F,0X9C,0X70,0XA4,0XB1,
0X94,0X50,0X94,0X2F,0X94,0X2F,0X8C,0X0E,0X94,0X4F,0X94,0X70,0X8C,0X4F,0X84,0X0E,
0X73,0X8C,0X73,0X8C,0X7B,0XAC,0X7B,0XAC,0X7B,0XAC,0X73,0X6B,0X6B,0X2B,0X6B,0X2B,
0X6B,0X0A,0X73,0X4B,0X73,0X6C,0X83,0XCD,0X6B,0X4B,0X6B,0X4B,0X83,0XEE,0X73,0X4B,
0X83,0XCD,0X7B,0X8C,0X7B,0X8D,0X83,0XCE,0X9C,0X70,0X7B,0XAD,0X39,0XA5,0X18,0XA1,
0X52,0X68,0X10,0X60,0X10,0X20,0X10,0X60,0X08,0X00,0X29,0X24,0X31,0X45,0X29,0X03,
0X18,0X81,0X18,0X81,0X10,0X40,0X20,0XA2,0X10,0X40,0X08,0X40,0X08,0X40,0X08,0X40,
0X08,0X20,0X10,0X20,0X10,0X20,0X08,0X20,0X08,0X20,0X08,0X00,0X10,0X40,0X08,0X40,
0X08,0X40,0X08,0X40,0X08,0X40,0X10,0X40,0X08,0X40,0X08,0X40,0X00,0X20,0X08,0X20,
0X10,0X60,0X10,0X40,0X10,0X40,0X10,0X40,0X10,0X40,0X08,0X40,0X08,0X40,0X08,0X40,
0X08,0X40,0X08,0X40,0X08,0X20,0X08,0X20,0X08,0X40,0X08,0X20,0X08,0X20,0X08,0X20,
0X08,0X40,0X08,0X40,0X08,0X40,0X08,0X40,0X08,0X40,0X00,0X20,0X00,0X00,0X08,0X20,
0X10,0X20,0X08,0X20,0X18,0X81,0X31,0X85,0X08,0X20,0X08,0X40,0X18,0X81,0X31,0X85,
0X18,0XA2,0X18,0XC2,0X10,0X81,0X21,0X03,0X29,0X44,0X7B,0XAC,0X8C,0X0E,0X94,0X2E,
0X94,0X0E,0X8B,0XCC,0X83,0X6A,0X83,0X8B,0X9C,0X4D,0X8B,0XCC,0X9C,0X2E,0X83,0X8B,
0X73,0X0A,0X8B,0XCD,0XAC,0XF2,0XBD,0X74,0X94,0X2F,0XA4,0XB1,0XA4,0XB1,0X9C,0X91,
0XA4,0X91,0X94,0X50,0XAD,0X33,0X94,0X4F,0X8C,0X0F,0X8C,0X2F,0X94,0X50,0X94,0X2F,
0X94,0X50,0X94,0X2F,0X8C,0X0F,0X8C,0X0F,0X8C,0X2F,0X8C,0X4F,0X84,0X2F,0X7B,0XCD,
0X73,0X6C,0X7B,0XAD,0X7B,0XAC,0X83,0XCD,0X7B,0XAC,0X6B,0X2B,0X6B,0X2B,0X73,0X4B,
0X73,0X4C,0X73,0X4C,0X73,0X4B,0X7B,0X8C,0X73,0X6C,0X6B,0X6B,0X6B,0X2B,0X7B,0X8D,
0X9C,0X90,0X7B,0X8C,0X7B,0XAD,0X62,0XEA,0X5A,0XA9,0X41,0XC5,0X62,0XCA,0X18,0X80,
0X18,0X81,0X29,0X23,0X18,0X81,0X10,0X60,0X10,0X61,0X10,0X20,0X10,0X41,0X29,0X03,
0X29,0X23,0X10,0X40,0X10,0X40,0X18,0XA2,0X08,0X00,0X08,0X40,0X08,0X40,0X08,0X20,
0X08,0X20,0X08,0X20,0X10,0X40,0X08,0X20,0X08,0X20,0X08,0X00,0X10,0X40,0X08,0X40,
0X08,0X40,0X08,0X40,0X08,0X40,0X10,0X40,0X08,0X40,0X08,0X20,0X00,0X00,0X08,0X20,
0X18,0X81,0X10,0X40,0X10,0X40,0X10,0X40,0X10,0X40,0X08,0X40,0X08,0X40,0X08,0X60,
0X08,0X40,0X10,0X60,0X08,0X40,0X08,0X40,0X08,0X40,0X08,0X20,0X08,0X40,0X08,0X40,
0X08,0X40,0X08,0X40,0X08,0X40,0X08,0X40,0X08,0X40,0X08,0X20,0X08,0X20,0X08,0X20,
0X18,0X81,0X20,0XC2,0X10,0X61,0X18,0XC2,0X21,0X03,0X08,0X20,0X08,0X20,0X10,0X40,
0X10,0X40,0X10,0X60,0X10,0X61,0X10,0XA1,0X39,0XC6,0X84,0X0E,0X8C,0X4F,0X94,0X4F,
0X94,0X4F,0X8B,0XCD,0X6A,0XC9,0X7B,0X4A,0X5A,0X66,0X9C,0X2D,0X9C,0X2E,0X8B,0XCD,
0X8B,0XED,0X94,0X2F,0XAC,0XD1,0X9C,0X90,0XA4,0X91,0XAD,0X13,0XB5,0X33,0XBD,0X95,
0XA4,0XD2,0X94,0X70,0XA4,0XD2,0X94,0X50,0X8B,0XEE,0X83,0XCE,0X8C,0X2F,0X8C,0X0F,
0X8C,0X0F,0X8C,0X0F,0X8C,0X2F,0X94,0X70,0X94,0X70,0X84,0X0E,0X84,0X0E,0X7B,0XCD,
0X7B,0XAD,0X7B,0XCD,0X83,0XAD,0X7B,0XAD,0X73,0X4B,0X7B,0X6C,0X7B,0X8D,0X7B,0XAD,
0X7B,0X8C,0X73,0X6C,0X73,0X6C,0X7B,0X8C,0X73,0X6C,0X73,0X6C,0X6B,0X2B,0X83,0XCE,
0X73,0X4C,0X73,0X6C,0X6B,0X0A,0X73,0X6C,0X39,0X84,0X83,0XCD,0X18,0X80,0X10,0X60,
0X08,0X20,0X52,0X68,0X18,0X81,0X10,0X40,0X10,0X40,0X10,0X40,0X10,0X40,0X10,0X60,
0X20,0XA2,0X39,0XA6,0X29,0X23,0X08,0X00,0X31,0X65,0X10,0X61,0X08,0X60,0X08,0X40,
0X08,0X20,0X08,0X20,0X10,0X20,0X10,0X20,0X10,0X20,0X08,0X00,0X10,0X20,0X08,0X40,
0X08,0X40,0X08,0X40,0X08,0X40,0X10,0X40,0X08,0X40,0X08,0X20,0X00,0X00,0X08,0X20,
0X10,0X60,0X08,0X20,0X10,0X40,0X10,0X40,0X08,0X40,0X08,0X40,0X08,0X60,0X08,0X60,
0X08,0X40,0X10,0X60,0X10,0X60,0X10,0X40,0X08,0X20,0X08,0X20,0X10,0X40,0X10,0X40,
0X08,0X20,0X08,0X20,0X08,0X20,0X08,0X20,0X00,0X00,0X00,0X20,0X08,0X20,0X18,0X81,
0X20,0XC1,0X10,0X60,0X08,0X20,0X08,0X20,0X08,0X40,0X08,0X40,0X08,0X40,0X08,0X40,
0X08,0X40,0X08,0X40,0X10,0X60,0X18,0XA1,0X39,0XC6,0X8C,0X4F,0X94,0X90,0X94,0X6F,
0X9C,0X6F,0X94,0X2F,0X83,0X8C,0X7B,0X4B,0X73,0X09,0X7B,0X29,0X9C,0X0D,0X8B,0XCD,
0X83,0XAC,0XAC,0XF1,0XA4,0XB1,0XA4,0XD1,0XA4,0XB1,0XA4,0XB1,0XA4,0XB1,0XB5,0X33,
0XB5,0X53,0XB5,0X54,0X9C,0X91,0X94,0X2F,0X8C,0X0E,0X83,0XEE,0X8C,0X0E,0X83,0XAD,
0X83,0XCE,0X83,0XCE,0X8C,0X0F,0X94,0X70,0X8C,0X2F,0X8C,0X2F,0X7B,0XCD,0X7B,0XCD,
0X73,0X8C,0X73,0XAD,0X7B,0X6C,0X7B,0X8C,0X7B,0X8C,0X7B,0X6C,0X7B,0X8C,0X7B,0X8C,
0X7B,0X8D,0X7B,0XAD,0X73,0X6C,0X7B,0XAD,0X73,0X6C,0X6B,0X4B,0X6B,0X2B,0X73,0X4B,
0X73,0X4B,0X62,0XC9,0X62,0XC9,0X83,0XCD,0X41,0XE6,0X31,0X44,0X10,0X60,0X62,0XEA,
0X20,0XE2,0X18,0X80,0X49,0XE6,0X18,0X61,0X10,0X40,0X10,0X40,0X10,0X20,0X10,0X40,
0X18,0XA1,0X18,0XA1,0X18,0XA1,0X39,0X65,0X20,0XE2,0X39,0XA6,0X08,0X40,0X10,0X40,
0X10,0X20,0X08,0X20,0X10,0X20,0X08,0X20,0X08,0X20,0X08,0X00,0X10,0X20,0X10,0X40,
0X08,0X40,0X08,0X40,0X08,0X40,0X08,0X40,0X08,0X40,0X08,0X20,0X00,0X00,0X08,0X20,
0X18,0X81,0X10,0X40,0X10,0X40,0X10,0X40,0X08,0X40,0X08,0X40,0X08,0X60,0X08,0X60,
0X10,0X40,0X10,0X40,0X10,0X20,0X10,0X20,0X10,0X40,0X08,0X20,0X08,0X20,0X10,0X20,
0X10,0X20,0X10,0X20,0X08,0X20,0X08,0X20,0X08,0X20,0X08,0X00,0X08,0X20,0X08,0X40,
0X08,0X40,0X08,0X40,0X08,0X40,0X08,0X40,0X08,0X40,0X08,0X40,0X08,0X40,0X08,0X40,
0X08,0X40,0X10,0X60,0X10,0X80,0X18,0XC1,0X31,0X84,0X94,0X6F,0XA4,0XF1,0X9C,0X90,
0X94,0X70,0X94,0X4F,0X8C,0X0E,0X94,0X2E,0X73,0X0A,0X83,0X8B,0X83,0XAC,0X93,0XED,
0XAC,0XD0,0XAC,0XD1,0X9C,0X4F,0X9C,0X70,0XA4,0XB0,0XAC,0XD2,0XAD,0X13,0XBD,0X95,
0XB5,0X74,0XB5,0X74,0XA4,0XD1,0X9C,0X90,0X94,0X4F,0X8C,0X0E,0X83,0XAD,0X83,0XCE,
0X7B,0XAD,0X7B,0XAD,0X83,0XAD,0X7B,0XAD,0X7B,0XAD,0X7B,0XCD,0X73,0X8C,0X73,0X8C,
0X73,0X6C,0X73,0X8C,0X7B,0X8C,0X7B,0X8C,0X7B,0X8C,0X7B,0X8C,0X73,0XAC,0X73,0X8C,
0X73,0XAC,0X7B,0XAC,0X73,0X4B,0X73,0X6C,0X5A,0XA9,0X62,0XA9,0X62,0XC9,0X5A,0X88,
0X4A,0X26,0X6B,0X2A,0X5A,0X88,0X52,0X27,0X49,0XE6,0X20,0X81,0X4A,0X07,0X29,0X03,
0X20,0XC2,0X18,0X60,0X20,0XA2,0X10,0X61,0X10,0X40,0X10,0X40,0X10,0X40,0X10,0X40,
0X10,0X40,0X10,0X40,0X18,0XA1,0X10,0X60,0X18,0X80,0X18,0XA1,0X31,0X24,0X18,0X61,
0X10,0X20,0X10,0X20,0X10,0X20,0X10,0X20,0X08,0X00,0X08,0X00,0X10,0X20,0X10,0X40,
0X10,0X40,0X08,0X40,0X08,0X40,0X08,0X60,0X08,0X60,0X08,0X40,0X00,0X20,0X08,0X20,
0X18,0X81,0X10,0X40,0X10,0X40,0X10,0X40,0X08,0X40,0X08,0X40,0X08,0X60,0X08,0X60,
0X10,0X60,0X08,0X20,0X10,0X40,0X10,0X40,0X10,0X40,0X08,0X20,0X10,0X20,0X10,0X40,
0X10,0X20,0X10,0X20,0X10,0X20,0X08,0X20,0X08,0X20,0X08,0X20,0X08,0X20,0X00,0X00,
0X08,0X20,0X08,0X20,0X10,0X40,0X08,0X40,0X08,0X40,0X08,0X40,0X10,0X40,0X08,0X40,
0X10,0X40,0X10,0X60,0X10,0X60,0X18,0XA1,0X42,0X06,0XA5,0X12,0XAD,0X53,0XAD,0X12,
0XA4,0XD1,0X9C,0X70,0X8C,0X0E,0X8B,0XED,0X83,0X8C,0X73,0X2A,0X7B,0X6B,0X7B,0X4B,
0XAC,0XF1,0X94,0X2E,0X94,0X2E,0X94,0X0E,0X9C,0X4F,0X9C,0X70,0XB5,0X13,0XAD,0X12,
0XB5,0X74,0XB5,0X74,0XA4,0XD1,0XA4,0XB1,0X94,0X4F,0X94,0X4F,0X94,0X50,0X8C,0X0E,
0X83,0XEE,0X83,0XCE,0X83,0XAD,0X7B,0XAD,0X7B,0XCD,0X7B,0XCD,0X73,0X6C,0X73,0X8C,
0X7B,0XAD,0X7B,0XAD,0X7B,0XAC,0X7B,0X8C,0X7B,0X8C,0X73,0X6C,0X73,0X8C,0X73,0X8C,
0X73,0X6B,0X62,0XE9,0X5A,0XA8,0X5A,0XA8,0X4A,0X06,0X52,0X27,0X52,0X27,0X52,0X47,
0X41,0XC5,0X7B,0X8C,0X42,0X06,0X41,0XE6,0X4A,0X07,0X4A,0X07,0X39,0X85,0X10,0X40,
0X39,0X64,0X18,0X60,0X10,0X40,0X5A,0X69,0X10,0X40,0X18,0X61,0X18,0X61,0X10,0X40,
0X10,0X40,0X08,0X20,0X10,0X60,0X08,0X60,0X08,0X20,0X18,0X81,0X31,0X44,0X10,0X61,
0X18,0X81,0X18,0XA2,0X10,0X41,0X10,0X20,0X08,0X00,0X08,0X00,0X10,0X20,0X10,0X40,
0X10,0X40,0X08,0X40,0X08,0X40,0X08,0X60,0X08,0X60,0X08,0X40,0X00,0X20,0X08,0X20,
0X18,0XA1,0X10,0X40,0X10,0X20,0X08,0X20,0X08,0X40,0X08,0X40,0X08,0X60,0X08,0X60,
0X08,0X40,0X10,0X40,0X08,0X40,0X10,0X40,0X10,0X40,0X10,0X40,0X10,0X20,0X10,0X20,
0X10,0X20,0X10,0X20,0X10,0X20,0X08,0X20,0X08,0X20,0X08,0X40,0X08,0X20,0X08,0X20,
0X08,0X20,0X08,0X40,0X08,0X40,0X08,0X40,0X08,0X40,0X08,0X40,0X08,0X40,0X08,0X40,
0X08,0X40,0X10,0X60,0X10,0X60,0X20,0XE2,0X63,0X0A,0XAD,0X74,0XB5,0XB5,0XBD,0XB5,
0XAD,0X13,0XA4,0XD1,0X94,0X4F,0X83,0XAD,0X83,0XAD,0X83,0X8C,0X83,0X8C,0X9C,0X90,
0X94,0X2E,0X9C,0X4E,0XAC,0XD0,0X9C,0X4E,0X8B,0XCC,0X83,0X8B,0X9C,0X2E,0XA4,0X90,
0XAC,0XD1,0X8B,0XEE,0X83,0XAD,0X62,0XC9,0X5A,0X88,0X5A,0X68,0X52,0X47,0X52,0X48,
0X52,0X48,0X6A,0XEA,0X52,0X68,0X62,0XC9,0X62,0XEA,0X62,0XEA,0X52,0X88,0X63,0X0A,
0X6B,0X2B,0X6B,0X2B,0X6B,0X2A,0X6B,0X0A,0X6B,0X0A,0X73,0X4B,0X6B,0X4B,0X63,0X0A,
0X52,0XA8,0X42,0X06,0X41,0XE5,0X39,0XA5,0X4A,0X06,0X4A,0X06,0X52,0X27,0X52,0X27,
0X5A,0X88,0X62,0XE9,0X52,0X88,0X52,0X88,0X73,0X4C,0X49,0XE7,0X49,0XE6,0X31,0X44,
0X49,0XE6,0X20,0XE2,0X10,0X40,0X20,0XC2,0X31,0X44,0X10,0X40,0X10,0X20,0X08,0X20,
0X08,0X20,0X08,0X40,0X08,0X60,0X08,0X60,0X10,0X60,0X10,0X60,0X10,0X40,0X18,0XA2,
0X10,0X61,0X10,0X41,0X08,0X20,0X10,0X20,0X10,0X40,0X10,0X20,0X10,0X20,0X10,0X60,
0X10,0X40,0X08,0X40,0X08,0X40,0X08,0X40,0X08,0X40,0X08,0X40,0X00,0X20,0X08,0X20,
0X18,0XA1,0X10,0X40,0X10,0X20,0X08,0X20,0X08,0X40,0X08,0X40,0X08,0X60,0X08,0X60,
0X08,0X40,0X08,0X40,0X08,0X20,0X08,0X40,0X10,0X40,0X10,0X40,0X08,0X20,0X08,0X20,
0X10,0X20,0X10,0X20,0X10,0X20,0X10,0X40,0X08,0X20,0X08,0X40,0X08,0X20,0X08,0X20,
0X08,0X20,0X08,0X40,0X08,0X40,0X08,0X40,0X08,0X20,0X08,0X40,0X08,0X40,0X08,0X40,
0X08,0X40,0X10,0X60,0X10,0X60,0X20,0XC1,0X73,0X6C,0XB5,0XB5,0XB5,0XB5,0XBD,0XD5,
0XB5,0X74,0XA4,0XF2,0X9C,0XB1,0X94,0X4F,0X94,0X2F,0X8B,0XED,0X83,0XCD,0XA4,0XB0,
0X8B,0XED,0X94,0X0D,0X9C,0X4E,0XAC,0XB0,0XBD,0X31,0X8B,0XCC,0X93,0XCD,0X83,0X8C,
0X73,0X0A,0X5A,0X47,0X49,0XC6,0X52,0X06,0X52,0X07,0X52,0X47,0X52,0X47,0X52,0X27,
0X4A,0X27,0X52,0X48,0X4A,0X07,0X4A,0X27,0X4A,0X27,0X39,0XC5,0X39,0XA5,0X39,0XA5,
0X41,0XE6,0X42,0X06,0X4A,0X26,0X4A,0X06,0X52,0X47,0X52,0X68,0X52,0X68,0X39,0XC5,
0X39,0XC5,0X39,0XC5,0X39,0XC5,0X39,0XA5,0X49,0XE6,0X52,0X27,0X4A,0X06,0X52,0X26,
0X62,0XC9,0X52,0X88,0X52,0X88,0X5A,0XA8,0X6B,0X2B,0X41,0XE6,0X41,0XC6,0X7B,0X8D,
0X20,0XE2,0X20,0XC1,0X10,0X40,0X08,0X00,0X41,0XA6,0X10,0X40,0X18,0X81,0X08,0X40,
0X08,0X40,0X08,0X40,0X08,0X60,0X08,0X60,0X08,0X60,0X08,0X40,0X08,0X20,0X10,0X81,
0X18,0XA2,0X10,0X61,0X08,0X20,0X10,0X20,0X10,0X20,0X08,0X00,0X10,0X20,0X10,0X61,
0X08,0X20,0X08,0X40,0X08,0X40,0X08,0X40,0X08,0X40,0X08,0X40,0X00,0X20,0X00,0X20,
0X18,0X81,0X08,0X20,0X08,0X20,0X08,0X20,0X08,0X40,0X08,0X40,0X08,0X40,0X08,0X40,
0X08,0X40,0X08,0X40,0X10,0X40,0X08,0X20,0X10,0X20,0X08,0X20,0X08,0X20,0X08,0X40,
0X10,0X40,0X08,0X20,0X10,0X40,0X10,0X20,0X08,0X20,0X08,0X20,0X00,0X00,0X08,0X20,
0X08,0X40,0X08,0X40,0X08,0X40,0X08,0X20,0X08,0X20,0X08,0X20,0X08,0X40,0X08,0X40,
0X08,0X40,0X10,0X20,0X10,0X40,0X20,0XE2,0XA4,0XD2,0XC6,0X17,0XC6,0X17,0XCE,0X37,
0XC6,0X17,0XC5,0XD6,0XB5,0X33,0XA4,0XB1,0X94,0X4F,0X94,0X4F,0X9C,0X70,0X9C,0X4F,
0X94,0X2E,0X94,0X0E,0X93,0XED,0X94,0X2E,0XAC,0XB0,0X9C,0X2E,0X83,0X6B,0X8B,0X8C,
0X83,0X8C,0X6A,0XC9,0X62,0X88,0X62,0X88,0X62,0XA8,0X62,0XA9,0X62,0XE9,0X62,0XC9,
0X6A,0XEA,0X5A,0XA8,0X5A,0X68,0X52,0X47,0X52,0X47,0X4A,0X26,0X4A,0X06,0X41,0XE6,
0X41,0XC6,0X41,0XE6,0X42,0X06,0X42,0X26,0X4A,0X26,0X4A,0X67,0X4A,0X07,0X41,0XE6,
0X39,0XC5,0X39,0XA5,0X39,0XC5,0X4A,0X27,0X52,0X47,0X52,0X48,0X52,0X68,0X5A,0X88,
0X5A,0XA9,0X52,0X88,0X5A,0XC9,0X52,0X88,0X5A,0XC9,0X42,0X06,0X41,0XC6,0X62,0XCA,
0X29,0X03,0X18,0X81,0X18,0XA1,0X10,0X40,0X10,0X40,0X29,0X02,0X08,0X20,0X10,0X40,
0X08,0X40,0X08,0X40,0X08,0X60,0X08,0X40,0X08,0X20,0X08,0X40,0X08,0X40,0X08,0X20,
0X29,0X43,0X18,0XC1,0X10,0X60,0X10,0X40,0X08,0X20,0X08,0X20,0X08,0X20,0X08,0X60,
0X08,0X40,0X08,0X40,0X08,0X40,0X08,0X40,0X08,0X40,0X08,0X20,0X08,0X20,0X00,0X20,
0X18,0X81,0X10,0X40,0X08,0X20,0X08,0X20,0X08,0X40,0X08,0X40,0X08,0X40,0X08,0X40,
0X08,0X40,0X08,0X40,0X08,0X20,0X08,0X00,0X08,0X00,0X08,0X00,0X08,0X00,0X08,0X20,
0X10,0X40,0X08,0X20,0X10,0X40,0X08,0X20,0X08,0X00,0X08,0X20,0X00,0X20,0X08,0X20,
0X08,0X40,0X08,0X40,0X08,0X40,0X08,0X20,0X08,0X00,0X08,0X20,0X08,0X40,0X08,0X40,
0X08,0X40,0X10,0X40,0X18,0XA1,0X5A,0X89,0XC5,0XF6,0XCE,0X17,0XCE,0X38,0XCE,0X37,
0XCE,0X37,0XCE,0X17,0XCE,0X17,0XB5,0X74,0XA4,0XD2,0X9C,0X90,0XA4,0XD1,0X94,0X2F,
0X94,0X2F,0X94,0X2E,0X8C,0X0E,0X8B,0XED,0X8B,0XED,0X94,0X0E,0X8B,0X8C,0X8B,0X8C,
0X83,0X8C,0X73,0X2B,0X73,0X2B,0X73,0X4B,0X73,0X2B,0X7B,0X6B,0X73,0X4B,0X73,0X4B,
0X73,0X6B,0X73,0X4B,0X6B,0X0A,0X62,0XC9,0X5A,0XC9,0X5A,0XC9,0X52,0X68,0X52,0X47,
0X4A,0X27,0X52,0X47,0X4A,0X47,0X52,0X47,0X52,0X47,0X52,0X88,0X52,0X68,0X52,0X47,
0X4A,0X27,0X4A,0X27,0X4A,0X27,0X4A,0X47,0X52,0X68,0X5A,0X89,0X5A,0XA9,0X62,0XA9,
0X62,0XC9,0X5A,0XA9,0X5A,0XC9,0X52,0X88,0X5A,0XC9,0X42,0X06,0X4A,0X06,0X62,0XEA,
0X62,0XEA,0X49,0XE6,0X18,0X81,0X10,0X40,0X08,0X00,0X31,0X44,0X10,0X60,0X10,0X40,
0X08,0X40,0X08,0X40,0X08,0X60,0X08,0X40,0X08,0X20,0X08,0X40,0X08,0X40,0X10,0X60,
0X18,0XA1,0X10,0X60,0X10,0X80,0X08,0X20,0X10,0X20,0X08,0X20,0X08,0X20,0X08,0X40,
0X08,0X40,0X08,0X40,0X08,0X40,0X10,0X60,0X08,0X40,0X08,0X40,0X08,0X00,0X00,0X20,
0X18,0X81,0X10,0X40,0X08,0X20,0X08,0X20,0X08,0X40,0X08,0X40,0X08,0X40,0X08,0X40,
0X08,0X40,0X08,0X20,0X08,0X00,0X08,0X00,0X08,0X00,0X08,0X20,0X08,0X20,0X08,0X40,
0X08,0X40,0X08,0X40,0X08,0X40,0X08,0X40,0X08,0X20,0X08,0X20,0X00,0X20,0X08,0X20,
0X08,0X40,0X08,0X40,0X08,0X20,0X08,0X20,0X08,0X20,0X00,0X00,0X08,0X40,0X08,0X40,
0X08,0X40,0X08,0X20,0X31,0X43,0X7B,0XAD,0XC5,0XD6,0XCE,0X38,0XD6,0X58,0XCE,0X38,
0XCE,0X18,0XCE,0X17,0XCE,0X37,0XC5,0XF6,0XBD,0X74,0XAD,0X12,0XA4,0XD2,0X9C,0X70,
0X9C,0X2F,0X94,0X2F,0X94,0X2F,0X94,0X0F,0X8B,0XEE,0X94,0X0E,0X8B,0XCD,0X8B,0XCD,
0X8B,0XEE,0X8C,0X0E,0X8C,0X0E,0X8B,0XEE,0X94,0X2E,0X94,0X2E,0X8C,0X0E,0X8C,0X0E,
0X83,0XED,0X83,0XCD,0X83,0XAD,0X73,0X6C,0X6B,0X4B,0X63,0X2A,0X62,0XC9,0X62,0XC9,
0X5A,0XA8,0X5A,0X88,0X5A,0X88,0X5A,0X88,0X5A,0X88,0X5A,0XA9,0X62,0XA9,0X5A,0XA9,
0X52,0X88,0X52,0X88,0X52,0X68,0X52,0X68,0X5A,0XA9,0X5A,0XA9,0X62,0XC9,0X62,0XC9,
0X62,0XC9,0X5A,0XC9,0X62,0XEA,0X52,0X88,0X5A,0XA9,0X42,0X06,0X39,0XA5,0X62,0XCA,
0X62,0XA9,0X5A,0X68,0X39,0X85,0X18,0X61,0X18,0X61,0X10,0X40,0X29,0X03,0X10,0X61,
0X10,0X61,0X08,0X40,0X08,0X40,0X08,0X40,0X08,0X40,0X08,0X40,0X08,0X40,0X08,0X40,
0X10,0X60,0X10,0X81,0X08,0X20,0X10,0X20,0X10,0X20,0X08,0X20,0X08,0X20,0X10,0X40,
0X10,0X40,0X10,0X40,0X10,0X40,0X08,0X40,0X08,0X40,0X08,0X20,0X00,0X00,0X00,0X20,
0X18,0X81,0X10,0X40,0X08,0X20,0X08,0X20,0X08,0X40,0X08,0X40,0X08,0X40,0X08,0X40,
0X08,0X20,0X08,0X20,0X08,0X20,0X08,0X00,0X08,0X00,0X08,0X20,0X08,0X20,0X08,0X40,
0X08,0X40,0X08,0X40,0X08,0X40,0X08,0X40,0X08,0X20,0X08,0X20,0X08,0X20,0X00,0X20,
0X08,0X40,0X08,0X20,0X08,0X20,0X08,0X20,0X08,0X20,0X08,0X20,0X10,0X60,0X08,0X40,
0X10,0X60,0X28,0XE2,0X31,0X23,0XBD,0X95,0XCE,0X17,0XD6,0X58,0XCE,0X18,0XCE,0X17,
0XCE,0X18,0XCE,0X38,0XCE,0X38,0XCE,0X17,0XCE,0X17,0XC5,0XB5,0XB5,0X33,0XA4,0XD2,
0XA4,0X91,0X9C,0X71,0X9C,0X30,0X9C,0X50,0X94,0X0F,0X9C,0X70,0X9C,0X4F,0XAC,0XB1,
0XA4,0XB0,0XA4,0XB1,0XA4,0XB1,0X9C,0X90,0X9C,0XB0,0XA4,0XD1,0XAD,0X12,0XA4,0XD1,
0X8C,0X2E,0X9C,0X90,0X8C,0X2E,0X83,0XCD,0X7B,0XCD,0X7B,0XAC,0X6B,0X4B,0X6B,0X0A,
0X62,0XE9,0X62,0XC9,0X62,0XC9,0X62,0XEA,0X6A,0XEA,0X6B,0X0A,0X62,0XCA,0X62,0XC9,
0X5A,0XC9,0X5A,0XC9,0X5A,0XA9,0X5A,0XA9,0X62,0XC9,0X62,0XC9,0X62,0XC9,0X62,0XC9,
0X62,0XC9,0X52,0XA9,0X5A,0XC9,0X5A,0X88,0X5A,0XA9,0X4A,0X27,0X4A,0X07,0X6A,0XEA,
0X5A,0XA9,0X5A,0X68,0X4A,0X27,0X29,0X03,0X18,0X82,0X18,0X81,0X29,0X24,0X08,0X20,
0X10,0X61,0X08,0X40,0X08,0X40,0X08,0X40,0X08,0X40,0X08,0X40,0X08,0X20,0X08,0X20,
0X08,0X20,0X08,0X40,0X18,0XA1,0X08,0X40,0X10,0X20,0X08,0X20,0X08,0X20,0X10,0X20,
0X10,0X40,0X10,0X40,0X08,0X40,0X08,0X40,0X08,0X40,0X08,0X20,0X00,0X00,0X00,0X20,
0X10,0X60,0X10,0X40,0X10,0X40,0X08,0X20,0X08,0X40,0X08,0X40,0X08,0X60,0X08,0X40,
0X08,0X40,0X00,0X20,0X00,0X20,0X00,0X00,0X00,0X00,0X00,0X00,0X08,0X40,0X08,0X40,
0X08,0X20,0X08,0X40,0X08,0X40,0X10,0X40,0X10,0X40,0X10,0X40,0X08,0X20,0X08,0X20,
0X08,0X40,0X08,0X40,0X00,0X20,0X00,0X20,0X08,0X40,0X08,0X40,0X10,0X81,0X42,0X07,
0X10,0X61,0X31,0X43,0X39,0XA5,0XC5,0XD6,0XD6,0X78,0XDE,0X79,0XDE,0X9A,0XDE,0XBA,
0XD6,0X99,0XCE,0X58,0XCE,0X18,0XD6,0X38,0XCE,0X18,0XD6,0X58,0XC5,0XF6,0XB5,0X54,
0XAC,0XF3,0XA4,0XB1,0X9C,0X70,0X9C,0X70,0X9C,0X50,0XA4,0X91,0XA4,0XB1,0XB5,0X53,
0XB5,0X73,0XBD,0X94,0XBD,0X94,0XB5,0X73,0XC5,0XD5,0XB5,0X94,0XAD,0X32,0X9C,0XB0,
0X94,0X2F,0X8C,0X4F,0X94,0X6F,0X94,0X6F,0X83,0XED,0X83,0XEE,0X7B,0X8C,0X6B,0X0A,
0X73,0X4B,0X73,0X4B,0X6B,0X4B,0X73,0X4B,0X63,0X0A,0X6B,0X4B,0X62,0XEA,0X62,0XEA,
0X62,0XEA,0X62,0XEA,0X62,0XEA,0X62,0XCA,0X62,0XEA,0X5A,0XA9,0X62,0XEA,0X62,0XEA,
0X5A,0XC9,0X52,0X68,0X62,0XEA,0X5A,0X88,0X6B,0X2A,0X5A,0XA9,0X52,0X68,0X6B,0X0A,
0X5A,0XA9,0X62,0XEA,0X42,0X07,0X31,0X65,0X29,0X03,0X20,0XA2,0X10,0X20,0X08,0X00,
0X08,0X20,0X00,0X00,0X08,0X40,0X08,0X40,0X00,0X00,0X08,0X40,0X00,0X00,0X08,0X00,
0X08,0X20,0X08,0X20,0X10,0X60,0X08,0X40,0X08,0X20,0X08,0X20,0X10,0X40,0X10,0X20,
0X10,0X40,0X08,0X60,0X08,0X40,0X10,0X40,0X10,0X40,0X08,0X20,0X08,0X00,0X08,0X20,
0X18,0X80,0X10,0X40,0X10,0X40,0X08,0X40,0X08,0X20,0X08,0X20,0X08,0X20,0X08,0X40,
0X08,0X40,0X08,0X40,0X18,0XE3,0X00,0X00,0X8C,0X71,0X18,0XC2,0X08,0X40,0X00,0X20,
0X08,0X20,0X08,0X20,0X00,0X00,0X00,0X00,0X00,0X00,0X00,0X00,0X00,0X00,0X00,0X00,
0X08,0X40,0X08,0X40,0X00,0X00,0X08,0X40,0X08,0X20,0X20,0XE2,0X10,0X60,0X10,0X40,
0X10,0X60,0X18,0X81,0X6B,0X2B,0XC5,0XF6,0XCE,0X37,0XDE,0X99,0XDE,0XBA,0XDE,0XBA,
0XE7,0X1C,0XDE,0XBA,0XDE,0XBA,0XD6,0X79,0XD6,0X79,0XD6,0X79,0XD6,0X58,0XCE,0X37,
0XB5,0X74,0XB5,0X75,0XAD,0X13,0XA4,0XD2,0XA4,0XB2,0XAC,0XD2,0XB5,0X13,0XD6,0X17,
0XCE,0X16,0XBD,0XD5,0XDE,0XD9,0XBD,0XB5,0XC5,0XF6,0XC5,0XF6,0XAD,0X53,0XA4,0XD1,
0XA4,0XD1,0X8C,0X4F,0XA4,0XD1,0X9C,0XD1,0X94,0X70,0XE6,0XFA,0X7B,0XAD,0X9C,0XD1,
0X73,0X8C,0X73,0X6C,0X6B,0X2B,0XDE,0XB9,0X63,0X0A,0X6B,0X4B,0X6B,0X4B,0XE6,0XFA,
0X6B,0X0B,0X6B,0X4B,0X62,0XEA,0X62,0XCA,0X62,0XEA,0XB5,0X54,0X62,0XCA,0X62,0XCA,
0X8C,0X0F,0X62,0XCA,0X62,0XEA,0X52,0X47,0X6B,0X2B,0X5A,0X89,0X6B,0X4B,0XBD,0XB5,
0X52,0X89,0X5A,0XA9,0X8C,0X70,0X31,0X85,0X41,0XC6,0X20,0XC3,0X10,0X40,0X20,0XC2,
0X10,0X61,0X94,0X91,0X10,0X61,0X08,0X20,0XB5,0X95,0X08,0X20,0X10,0X81,0X08,0X40,
0X08,0X20,0X08,0X00,0X08,0X40,0X08,0X40,0X10,0X60,0X29,0X23,0X08,0X20,0X08,0X20,
0X10,0X40,0X08,0X40,0X08,0X40,0X10,0X40,0X10,0X40,0X08,0X20,0X08,0X00,0X00,0X20,
0X10,0X81,0X08,0X40,0X08,0X40,0X08,0X40,0X08,0X20,0X00,0X20,0X08,0X40,0X6B,0X4C,
0XF7,0X9D,0XFF,0XDE,0XDE,0XBA,0X00,0X00,0XD6,0X99,0X63,0X2B,0X94,0XB2,0X08,0X40,
0X00,0X00,0X00,0X00,0XDE,0XDA,0XAD,0X34,0XA5,0X34,0XB5,0X95,0XB5,0X95,0XEF,0X5D,
0X18,0XA2,0X08,0X40,0X08,0X20,0X08,0X20,0X18,0XC2,0X08,0X20,0X10,0X40,0X10,0X40,
0X10,0X40,0X29,0X03,0XAD,0X13,0XCE,0X37,0XD6,0X78,0XCE,0X58,0XD6,0X79,0XEF,0X5C,
0XF7,0XBE,0XD6,0XBA,0XDE,0XBA,0XD6,0X99,0XD6,0X79,0XCE,0X38,0XFF,0XBE,0XE6,0XFB,
0XC6,0X37,0XFF,0XFE,0XEF,0X5C,0XF7,0X7C,0XC5,0XD6,0XB5,0X75,0XBD,0X95,0XCE,0X37,
0XCE,0X37,0XCE,0X57,0XD6,0XB9,0XBD,0XF6,0XCE,0X78,0XC6,0X37,0XBD,0XD6,0XA5,0X13,
0XA5,0X13,0XB5,0X94,0XB5,0X95,0XBD,0XD6,0XAD,0X54,0XEF,0X3B,0X9C,0XB1,0XB5,0X94,
0X8C,0X4F,0X7B,0XAD,0X84,0X0E,0XE7,0X1A,0X6B,0X6C,0XFF,0XFE,0XFF,0XBD,0XF7,0X9C,
0XFF,0XDE,0XFF,0XFE,0XA4,0XB2,0X6A,0XEB,0X62,0XEA,0XFF,0XDE,0X5A,0X89,0X62,0XCA,
0XCE,0X17,0X62,0XEA,0X62,0XEA,0X62,0XEA,0X62,0XEA,0XFF,0X9D,0XF7,0X7D,0XF7,0X9D,
0XEF,0X7C,0XF7,0XBD,0XE7,0X3C,0XEF,0X5C,0XFF,0X9D,0X39,0X85,0X08,0X00,0XD6,0X39,
0XC5,0XF7,0XF7,0X9E,0XCE,0X79,0XBD,0XD6,0XFF,0XDE,0XAD,0X95,0XBD,0XD6,0X08,0X40,
0X00,0X00,0X00,0X00,0XFF,0XFE,0X00,0X00,0X00,0X00,0X42,0X07,0X08,0X20,0X08,0X20,
0X10,0X40,0X10,0X40,0X10,0X40,0X10,0X40,0X10,0X40,0X08,0X20,0X08,0X00,0X00,0X20,
0X10,0X81,0X08,0X40,0X08,0X40,0X08,0X40,0X08,0X40,0X08,0X20,0X00,0X00,0X00,0X00,
0X08,0X20,0XF7,0XBE,0X00,0X20,0X08,0X40,0XEF,0X9D,0X10,0X81,0X52,0XA9,0X10,0X81,
0X00,0X00,0X00,0X20,0XE7,0X3C,0XFF,0XFF,0XFF,0XFF,0XFF,0XFE,0XFF,0XFF,0XEF,0X3C,
0X08,0X40,0X08,0X40,0X08,0X40,0X08,0X40,0X08,0X40,0X10,0X40,0X10,0X40,0X10,0X40,
0X10,0X60,0X52,0X48,0XC5,0XD6,0XD6,0X58,0XD6,0X58,0XCE,0X58,0XEF,0X5C,0XE7,0X5C,
0XDF,0X1B,0XEF,0X5C,0XD6,0X99,0XDE,0XBA,0XD6,0X79,0XD6,0X59,0XCE,0X58,0XD6,0XBA,
0XC6,0X58,0XFF,0XDE,0XC6,0X17,0XCE,0X78,0XCE,0X79,0XBD,0XF6,0XC6,0X37,0XDF,0X1A,
0XD6,0XB8,0XEF,0X9C,0XD6,0XB9,0XDE,0XDA,0XDE,0XDA,0XD6,0X99,0XD6,0X99,0XAD,0X54,
0XB5,0X95,0XFF,0XDE,0XA4,0XF2,0XA4,0XF2,0X94,0X91,0XE7,0X3B,0X9C,0XD2,0X7B,0XCE,
0X94,0X70,0X8C,0X2F,0XE7,0X1B,0XFF,0XFE,0X9C,0XF2,0XDE,0XFA,0XDE,0XDA,0XFF,0XBD,
0XE6,0XFA,0XDE,0XBA,0X6B,0X2B,0X6B,0X0B,0XF7,0X7D,0XF7,0X5C,0XF7,0X9D,0X5A,0XCA,
0XF7,0X9D,0XFF,0XDE,0XF7,0X5C,0XFF,0XBE,0X7B,0X8D,0X62,0XCA,0X6B,0X4C,0XEF,0X7C,
0X73,0X6D,0X63,0X2B,0XA5,0X33,0X41,0XE7,0X4A,0X68,0X39,0X85,0X20,0XC2,0X10,0X41,
0X10,0X82,0XCE,0X79,0X08,0X61,0X00,0X20,0XFF,0XFF,0X08,0X40,0X00,0X00,0X00,0X00,
0X00,0X00,0X10,0X81,0X08,0X40,0XD6,0XBA,0X00,0X00,0X42,0X07,0X08,0X20,0X08,0X20,
0X10,0X40,0X10,0X40,0X10,0X20,0X10,0X40,0X10,0X40,0X10,0X40,0X08,0X20,0X00,0X20,
0X10,0X61,0X00,0X00,0X08,0X40,0X08,0X40,0X10,0X40,0X10,0X40,0X18,0X81,0XEF,0X5C,
0XEF,0X5C,0XFF,0XFF,0XEF,0X5C,0XEF,0X5C,0XFF,0XFE,0XE7,0X3B,0XFF,0XFE,0XC6,0X38,
0X00,0X20,0X08,0X40,0XB5,0X75,0X7B,0XAE,0X73,0XAE,0X7B,0XCE,0X7B,0XCE,0XEF,0X5D,
0X00,0X20,0X08,0X40,0X08,0X40,0X08,0X61,0X08,0X61,0X10,0X61,0X10,0X61,0X08,0X00,
0X18,0XC2,0X8C,0X30,0XC6,0X17,0XCE,0X58,0XD6,0X99,0XFF,0XDE,0XEF,0X5C,0XDE,0XDA,
0XDE,0XFB,0XE6,0XFB,0XFF,0XBE,0XE6,0XFB,0XDE,0XDA,0XEF,0X5C,0XD6,0XBA,0XD6,0X99,
0XF7,0X9D,0XDE,0XFB,0XCE,0X79,0XDE,0XDA,0XF7,0X9D,0XF7,0X9C,0XD6,0X98,0XC6,0X17,
0XC6,0X38,0XEF,0X5C,0XE7,0X1B,0XE7,0X3B,0XDE,0XFB,0XD6,0X99,0XBD,0XF7,0XAD,0X75,
0XC6,0X18,0XFF,0XDE,0XA5,0X34,0XBD,0XB6,0XB5,0X95,0XB5,0XB6,0XCE,0X58,0XCE,0X58,
0X94,0X90,0X9C,0XD1,0XEF,0X5B,0XF7,0XBD,0X9C,0XD2,0X94,0X91,0X94,0X91,0XFF,0XFF,
0X84,0X0F,0X8C,0X30,0X84,0X0F,0X5A,0XEA,0XC6,0X37,0X63,0X2B,0XD6,0XB9,0X94,0X91,
0X83,0XEF,0X6B,0X4C,0X73,0X8D,0XFF,0XFE,0X6B,0X4C,0X6B,0X6C,0XEF,0X5C,0X7B,0XCE,
0XD6,0X99,0XD6,0X99,0XEF,0X5C,0XC6,0X38,0XCE,0X58,0X5A,0XEA,0X4A,0X68,0XC5,0XF7,
0X6B,0X4C,0X84,0X30,0X6B,0X6D,0X63,0X2C,0X6B,0X4C,0X6B,0X4C,0XE7,0X1B,0X08,0X40,
0X08,0X40,0XDE,0XDA,0XD6,0X99,0X08,0X40,0X00,0X00,0X4A,0X28,0X00,0X20,0X08,0X20,
0X08,0X40,0X10,0X40,0X10,0X40,0X10,0X40,0X10,0X40,0X10,0X40,0X08,0X20,0X00,0X20,
0X10,0X61,0X00,0X00,0X08,0X20,0X08,0X40,0X10,0X40,0X10,0X40,0X10,0X40,0X00,0X00,
0X00,0X00,0XEF,0X7D,0X00,0X00,0X10,0X81,0XF7,0X9D,0X10,0XA2,0X73,0XAE,0X00,0X40,
0X10,0X81,0X08,0X61,0X08,0X40,0X00,0X00,0X00,0X00,0X00,0X00,0X00,0X00,0X00,0X00,
0X10,0X81,0X08,0X61,0XFF,0XFF,0XFF,0XDE,0XFF,0XDE,0XFF,0XFE,0XFF,0XFE,0XFF,0XDE,
0XFF,0XDE,0XFF,0XDE,0XFF,0XDE,0XCE,0X38,0XF7,0X9D,0XCE,0X58,0XD6,0X99,0XD6,0X99,
0XDE,0XFB,0XD6,0X99,0XD6,0X99,0XEF,0X5D,0XE7,0X1B,0XDE,0XDA,0XE7,0X3C,0XD6,0X99,
0XD6,0X99,0XCE,0X38,0XCE,0X58,0XC6,0X38,0XCE,0X58,0XD6,0X98,0XCE,0X78,0XDE,0XDA,
0XFF,0XBE,0XDE,0XFB,0XDE,0XDA,0XD6,0XB9,0XCE,0X78,0XCE,0X78,0XAD,0X54,0XAD,0X75,
0XCE,0X38,0XF7,0X7D,0XFF,0XDE,0XBD,0XD6,0XF7,0X9D,0XAD,0X75,0XF7,0X9D,0XD6,0XB9,
0XB5,0XB5,0X9C,0XD1,0XDE,0XFA,0XF7,0X9D,0XAD,0X54,0X94,0X91,0X8C,0X50,0X7B,0XEF,
0X73,0X8D,0X73,0X8D,0X6B,0X4C,0X6B,0X6C,0XC6,0X37,0X73,0X8D,0XD6,0X99,0X7B,0XAE,
0XE7,0X1B,0X73,0X8D,0X73,0XAD,0XFF,0XDE,0X73,0X8D,0XBD,0XB5,0X73,0X8D,0X7B,0XCE,
0XDE,0XFB,0X7B,0XEF,0XF7,0XBE,0X8C,0X71,0XD6,0XB9,0X7B,0XCE,0X63,0X0B,0XCE,0X58,
0XF7,0X9D,0XEF,0X5C,0XFF,0XFF,0XF7,0X9D,0XF7,0XBD,0XE7,0X1B,0XD6,0X99,0X10,0X81,
0X08,0X61,0X10,0X81,0X08,0X00,0X00,0X00,0X31,0XA6,0X21,0X24,0X00,0X20,0X08,0X40,
0X08,0X20,0X08,0X20,0X10,0X40,0X10,0X60,0X10,0X40,0X10,0X40,0X08,0X20,0X00,0X20,
0X18,0X81,0X08,0X20,0X08,0X20,0X10,0X40,0X10,0X40,0X10,0X40,0X08,0X00,0X10,0X81,
0X00,0X00,0XF7,0X9D,0XBD,0XF6,0XD6,0X99,0XB5,0X95,0X29,0X44,0XCE,0X58,0X10,0X81,
0X00,0X20,0X39,0XC7,0X62,0XEB,0X39,0XC6,0X39,0XA6,0X39,0XA6,0X31,0XA6,0X29,0X45,
0X29,0X44,0X00,0X20,0X00,0X00,0X00,0X00,0X00,0X00,0X00,0X20,0X08,0X20,0X21,0X03,
0X63,0X0B,0XCE,0X58,0XC6,0X17,0XCE,0X38,0XCE,0X58,0XD6,0X79,0XD6,0X99,0XD6,0X99,
0XD6,0XBA,0XDE,0XBA,0XDE,0XBA,0XDE,0XBA,0XDE,0XBA,0XDE,0XBA,0XD6,0XBA,0XDE,0XDA,
0XEF,0X7D,0XE7,0X3C,0XDE,0XBA,0XE7,0X1B,0XF7,0XBE,0XD6,0X99,0XDE,0XDA,0XF7,0XBD,
0XDE,0XBA,0XEF,0X9D,0XF7,0XDE,0XF7,0X9D,0XFF,0XDE,0XF7,0XBD,0XB5,0XB6,0XD6,0X99,
0XE6,0XFB,0XDE,0XDB,0XF7,0XBE,0XF7,0X7D,0XFF,0XDE,0XE6,0XFB,0XEF,0X3C,0XDE,0XFA,
0XE7,0X3B,0XB5,0X94,0XB5,0XB5,0XEF,0X7C,0XA5,0X33,0XF7,0X9D,0X9C,0XD2,0XAD,0X34,
0XA5,0X13,0XFF,0XDE,0X94,0X91,0X94,0X90,0XD6,0XB9,0XAD,0X74,0XE6,0XFB,0X84,0X0F,
0X83,0XEF,0XE6,0XFB,0X83,0XEF,0XFF,0XDE,0X73,0X6C,0X7B,0XEE,0XFF,0XFE,0X73,0X6D,
0XF7,0X9D,0XEF,0X5C,0XFF,0XFF,0XFF,0XFF,0XF7,0XBD,0X94,0X90,0X8C,0X70,0X73,0X8E,
0X31,0X85,0XBD,0XF7,0X42,0X07,0X10,0XA2,0X10,0XA2,0X18,0XE3,0X10,0XA2,0X10,0XA2,
0XC6,0X17,0XBD,0XD6,0XC5,0XF7,0XBD,0XD6,0XFF,0XDE,0XC6,0X17,0XC5,0XF7,0XCE,0X38,
0X8C,0X30,0X08,0X40,0X10,0X40,0X10,0X40,0X10,0X40,0X08,0X20,0X08,0X00,0X00,0X20,
0X18,0X81,0X08,0X20,0X08,0X20,0X10,0X40,0X10,0X40,0X10,0X40,0X00,0X00,0XFF,0XFE,
0X6B,0X4C,0XF7,0XBE,0X00,0X20,0X08,0X61,0X52,0XAA,0XDE,0XFB,0X10,0X81,0X10,0X81,
0X00,0X00,0X00,0X20,0XFF,0XBE,0X18,0XA2,0X10,0XA2,0XB5,0X96,0XBD,0XF7,0XBD,0XF7,
0X31,0XA6,0X00,0X00,0X08,0X61,0X08,0X61,0X08,0X61,0X10,0X61,0X18,0X82,0X18,0XA2,
0X83,0XEF,0XC6,0X37,0XC6,0X17,0XC6,0X37,0XC6,0X37,0XC6,0X38,0XCE,0X58,0XCE,0X58,
0XD6,0X99,0XD6,0X79,0XD6,0X99,0XD6,0X9A,0XD6,0X9A,0XD6,0X99,0XE7,0X3C,0XE7,0X1B,
0XD6,0X99,0XF7,0XBE,0XDE,0XDA,0XEF,0X5C,0XE7,0X1B,0XD6,0X99,0XD6,0X99,0XD6,0X99,
0XDE,0XBA,0XE7,0X3C,0XD6,0XBA,0XD6,0XBA,0XDE,0XDA,0XDE,0XFB,0XCE,0X79,0XDE,0XDA,
0XE6,0XFB,0XDE,0XDA,0XD6,0X99,0XD6,0X99,0XEF,0X5C,0XD6,0XBA,0XCE,0X79,0XDE,0XFA,
0XDE,0XD9,0XC6,0X16,0XC6,0X16,0XF7,0XBD,0XCE,0X58,0XF7,0XBE,0XDE,0XBA,0XE6,0XFB,
0XBD,0XF7,0XF7,0X9D,0XBD,0XD6,0XAD,0X74,0XEF,0X7C,0XA5,0X33,0XE7,0X1B,0XA4,0XF3,
0XA4,0XF3,0XD6,0X79,0X94,0XB1,0XFF,0XBE,0X8C,0X2F,0X7B,0XCD,0XAD,0X33,0X7B,0XCE,
0XC5,0XF7,0XF7,0XDE,0XA5,0X13,0XCE,0X58,0XAD,0X54,0XA5,0X33,0XAD,0X74,0XCE,0X38,
0XFF,0XFF,0X5A,0XCA,0X21,0X03,0X29,0X44,0X31,0XA6,0XFF,0XFF,0X08,0X40,0X10,0X81,
0X00,0X20,0X08,0X20,0X08,0X40,0X10,0XA2,0XF7,0XBE,0X52,0X89,0X08,0X40,0X08,0X20,
0X10,0X81,0X08,0X40,0X10,0X40,0X10,0X40,0X10,0X40,0X08,0X20,0X08,0X00,0X00,0X20,
0X10,0X61,0X10,0X40,0X08,0X20,0X08,0X40,0X08,0X60,0X08,0X60,0X08,0X40,0X10,0X81,
0X00,0X20,0XF7,0XBE,0X18,0XE3,0X6B,0X6D,0XCE,0X59,0XD6,0XBA,0X10,0XA2,0XD6,0X99,
0X08,0X40,0X08,0X61,0XA5,0X34,0X9C,0XB2,0X18,0XC2,0X08,0X61,0X10,0XA2,0X08,0X61,
0X18,0XA2,0X08,0X40,0X10,0X81,0X10,0X41,0X10,0X41,0X10,0X61,0X10,0X81,0X21,0X03,
0XB5,0X75,0XCE,0X58,0XC6,0X17,0XC6,0X16,0XC5,0XF6,0XC5,0XF7,0XC5,0XF7,0XC6,0X17,
0XCE,0X58,0XCE,0X38,0XD6,0X79,0XDE,0X9A,0XDE,0X9A,0XDE,0X9A,0XFF,0X9E,0XDE,0X9A,
0XDE,0XBA,0XDE,0XBA,0XFF,0XBE,0XF7,0X9D,0XD6,0X99,0XD6,0XB9,0XDE,0XD9,0XDE,0XD9,
0XD6,0XB9,0XDE,0XFB,0XD6,0XBA,0XD6,0XBA,0XDE,0XFB,0XEF,0X5C,0XD6,0X99,0XDE,0XBA,
0XDE,0XBA,0XFF,0XBE,0XEF,0X7D,0XD6,0XBA,0XDE,0XFB,0XE6,0XFB,0XDE,0XDA,0XE7,0X3B,
0XDE,0XFA,0XB5,0XB5,0XB5,0X94,0XF7,0XBD,0XC6,0X37,0XFF,0XDE,0XF7,0X9D,0XE7,0X3C,
0XEF,0X7D,0XEF,0X9D,0XBD,0XD5,0XB5,0X95,0XEF,0X5C,0XDE,0XDA,0XDF,0X3B,0XAD,0X54,
0XA5,0X13,0X8C,0X30,0X9C,0XD2,0XFF,0XDE,0X9C,0XD2,0X9C,0XD2,0XF7,0X9D,0XB5,0X95,
0XA5,0X33,0XB5,0X75,0XF7,0XBE,0XD6,0XBA,0XBD,0XF6,0XB5,0XB5,0XAD,0X74,0XA4,0XF2,
0X42,0X07,0X4A,0X49,0XCE,0X79,0X9C,0XD3,0XE7,0X3C,0X08,0X41,0X00,0X20,0X10,0X61,
0X08,0X40,0X08,0X20,0X18,0XA2,0XFF,0XFF,0X10,0X81,0X29,0X44,0XE7,0X3C,0X20,0XE3,
0X18,0XA2,0X08,0X20,0X08,0X40,0X08,0X40,0X08,0X40,0X08,0X40,0X08,0X00,0X00,0X20,
0X10,0X61,0X10,0X40,0X08,0X40,0X10,0X40,0X08,0X60,0X08,0X60,0X18,0XA2,0X10,0X61,
0X7B,0XCE,0XFF,0XFF,0X4A,0X69,0X73,0XAD,0X08,0X61,0X7B,0XCF,0X9C,0XF3,0XAD,0X75,
0X29,0X24,0XF7,0X9E,0X10,0X82,0X39,0XC7,0XFF,0XDE,0XE7,0X3C,0XDE,0XFB,0XD6,0XBA,
0XDE,0XDA,0X10,0XA2,0X08,0X40,0X10,0X41,0X10,0X41,0X10,0X80,0X10,0X81,0X52,0X68,
0XC5,0XF6,0XCE,0X38,0XCE,0X37,0XC6,0X17,0XC6,0X17,0XCE,0X17,0XC5,0XD7,0XC5,0XF7,
0XCE,0X38,0XC5,0XF7,0XCE,0X38,0XCE,0X18,0XD6,0X39,0XDE,0X9A,0XD6,0X79,0XE6,0XFB,
0XFF,0X7E,0XF7,0X5D,0XDE,0X9A,0XEF,0X3C,0XF7,0XBE,0XEF,0X5C,0XDE,0XDA,0XDE,0XD9,
0XDE,0XB9,0XDE,0XD9,0XDE,0XB9,0XDE,0XDA,0XEF,0X5C,0XEF,0X5C,0XDE,0XB9,0XE6,0XFB,
0XEF,0X3C,0XE6,0XDB,0XF7,0X7D,0XEF,0X3C,0XEF,0X5C,0XF7,0X7D,0XF7,0X9D,0XCE,0X78,
0XEF,0X5C,0XC6,0X37,0XC6,0X37,0XF7,0X9C,0XCE,0X37,0XF7,0XBD,0XC6,0X38,0XCE,0X58,
0XDE,0XDA,0XFF,0XDE,0XBE,0X16,0XC6,0X57,0XE7,0X1B,0XB5,0XB6,0XBD,0XD6,0XA4,0XF3,
0X9C,0XD2,0XC5,0XF7,0XE7,0X1B,0XCE,0X58,0XBD,0XD6,0XDE,0XFA,0XB5,0X75,0XFF,0XBE,
0XCE,0X38,0XFF,0XDE,0XD6,0X99,0XE7,0X1B,0XE7,0X1B,0XC6,0X17,0XB5,0X74,0XC5,0XF6,
0X9C,0XB1,0XE6,0XFB,0XB5,0X75,0X21,0X03,0X08,0X61,0X08,0X61,0X18,0XC2,0X08,0X60,
0X63,0X0B,0XCE,0X58,0XA5,0X33,0X00,0X20,0X10,0X80,0X00,0X20,0X00,0X00,0XBD,0XD6,
0X73,0X8D,0X08,0X40,0X08,0X40,0X08,0X40,0X08,0X40,0X08,0X40,0X08,0X00,0X00,0X20,
0X10,0X61,0X10,0X61,0X10,0X61,0X10,0X81,0X10,0X81,0X10,0X81,0X10,0X82,0X18,0XC3,
0X10,0XA2,0X10,0XC2,0X18,0XE2,0X10,0X81,0X10,0XA2,0X18,0XC3,0X10,0X82,0X18,0XE3,
0X21,0X24,0X10,0X82,0X21,0X04,0X18,0XC3,0X18,0XC3,0X29,0X44,0X18,0XC2,0X18,0XA2,
0X18,0XA2,0X18,0XA3,0X10,0X82,0X18,0XC3,0X20,0XC3,0X18,0XE2,0X29,0X24,0X63,0X0B,
0XB5,0X74,0XCE,0X38,0XCE,0X38,0XCE,0X58,0XCE,0X58,0XD6,0X59,0XD6,0X59,0XC5,0XF7,
0XBD,0XB6,0XC6,0X18,0XC6,0X18,0XC5,0XF7,0XC5,0XF7,0XCD,0XF8,0XC5,0XD7,0XCD,0XF7,
0XCE,0X18,0XDE,0X99,0XDE,0X99,0XDE,0XBA,0XDE,0XBA,0XDE,0XBA,0XDE,0XBA,0XDE,0XBA,
0XD6,0X99,0XDE,0XBA,0XDE,0XBA,0XDE,0XBA,0XDE,0XBA,0XDE,0XB9,0XDE,0XBA,0XDE,0XBA,
0XDE,0X9A,0XE6,0XBB,0XDE,0XDA,0XD6,0X99,0XDE,0X9A,0XD6,0X79,0XD6,0X99,0XC6,0X37,
0XD6,0X98,0XCE,0X78,0XDE,0XB9,0XDE,0XB9,0XD6,0X99,0XD6,0X78,0XCE,0X38,0XC6,0X17,
0XBD,0XD6,0XBD,0XD6,0XBD,0XD5,0XB5,0X95,0XB5,0X75,0XAD,0X54,0XA4,0XF3,0XA4,0XD3,
0XB5,0X75,0XC5,0XD6,0XBD,0XB6,0XAD,0X54,0XAD,0X54,0XB5,0X96,0XC5,0XF7,0XBD,0XB6,
0XBD,0XD6,0XC5,0XF7,0XC5,0XF6,0XBD,0XD6,0XB5,0X75,0XB5,0X95,0XB5,0X54,0X94,0X91,
0X4A,0X48,0X18,0XC2,0X10,0X61,0X10,0X61,0X08,0X60,0X08,0X40,0X08,0X40,0X08,0X20,
0X00,0X00,0X10,0X60,0X10,0X60,0X00,0X20,0X00,0X00,0X00,0X20,0X00,0X20,0X08,0X41,
0X00,0X00,0X08,0X40,0X08,0X40,0X08,0X40,0X08,0X40,0X08,0X40,0X00,0X00,0X00,0X20,
0X39,0XA6,0X4A,0X28,0X41,0XE7,0X42,0X07,0X4A,0X07,0X52,0X49,0X5A,0X8A,0X5A,0X6A,
0X5A,0XEB,0X5B,0X0B,0X6B,0X6C,0X63,0X2C,0X73,0X8E,0X6B,0X4D,0X7B,0XCE,0X7B,0XCF,
0X63,0X2C,0X5A,0XEB,0X6B,0X6D,0X5A,0XCB,0X63,0X0C,0X63,0X2C,0X63,0X2C,0X5A,0XCA,
0X5A,0XCA,0X63,0X0C,0X73,0X6E,0X6B,0X2C,0X73,0X4D,0X73,0X8D,0X7B,0XCF,0XAD,0X55,
0XC5,0XF7,0XD6,0X79,0XD6,0X99,0XD6,0X99,0XD6,0X99,0XDE,0X99,0XD6,0X79,0XD6,0X79,
0XCE,0X38,0XBD,0XD7,0XBD,0XD7,0XBD,0X96,0XC5,0XD7,0XCD,0XF8,0XCD,0XF7,0XC5,0XB7,
0XC5,0XD7,0XC5,0XB6,0XBD,0XB6,0XBD,0X95,0XB5,0X95,0XBD,0XB6,0XCE,0X17,0XCE,0X38,
0XD6,0X58,0XD6,0X59,0XDE,0XBA,0XDE,0X9A,0XE6,0XBA,0XE6,0XBA,0XDE,0XBA,0XD6,0X58,
0XDE,0X9A,0XDE,0XBA,0XDE,0XBA,0XDE,0X99,0XDE,0X9A,0XD6,0X99,0XD6,0X99,0XCE,0X58,
0XD6,0X98,0XD6,0X98,0XDE,0XB9,0XDE,0X99,0XDE,0X99,0XD6,0X58,0XD6,0X78,0XC6,0X17,
0XBD,0XB5,0XBD,0XB5,0XBD,0XB5,0XB5,0X75,0XBD,0X95,0XC5,0XB6,0XC5,0XD7,0XCE,0X18,
0XCE,0X17,0XAD,0X34,0XA5,0X13,0XAD,0X54,0XBD,0XD6,0XCE,0X58,0XBD,0XD6,0XBD,0XF6,
0XC6,0X17,0XC5,0XF7,0XBD,0XD6,0XBD,0X95,0XBD,0X95,0XBD,0XB6,0XBD,0XD6,0XA5,0X13,
0X7B,0XEE,0X20,0XE3,0X10,0X81,0X08,0X20,0X08,0X00,0X08,0X40,0X08,0X40,0X08,0X20,
0X10,0X60,0X08,0X20,0X08,0X40,0X00,0X20,0X00,0X00,0X00,0X20,0X00,0X20,0X00,0X00,
0X10,0X61,0X08,0X40,0X08,0X40,0X08,0X40,0X08,0X40,0X08,0X20,0X08,0X00,0X08,0X00,
0X83,0XCF,0X83,0XD0,0X83,0XCF,0X8C,0X31,0X9C,0X92,0XA4,0XD3,0XAD,0X34,0XAD,0X35,
0XAD,0X35,0XAD,0X55,0XBD,0XB6,0XB5,0X96,0XB5,0X96,0XB5,0XB6,0XBD,0XB7,0XBD,0XB6,
0XAD,0X55,0X9C,0XF3,0X9C,0XD3,0X9C,0XD3,0X9C,0XD3,0X9C,0XF3,0X9C,0XD3,0X9C,0XF3,
0XA5,0X14,0XA5,0X14,0XA5,0X15,0XA5,0X14,0XA5,0X14,0XB5,0X96,0XBD,0XF8,0XC6,0X18,
0XCE,0X7A,0XD6,0X9A,0XD6,0X9A,0XDE,0X7A,0XDE,0X7A,0XD6,0X7A,0XD6,0X9A,0XD6,0X9A,
0XD6,0X79,0XC6,0X17,0XBD,0XB7,0XBD,0XD7,0XC5,0XF8,0XC5,0XD8,0XC5,0XB8,0XBD,0X96,
0XBD,0X96,0XBD,0X96,0XBD,0X96,0XBD,0X96,0XBD,0X96,0XCE,0X18,0XD6,0X79,0XD6,0X9A,
0XD6,0X79,0XD6,0X79,0XDE,0X9A,0XDE,0X9A,0XE6,0XBA,0XDE,0X9A,0XD6,0X59,0XCE,0X39,
0XDE,0XBB,0XDE,0X7A,0XDE,0X7A,0XD6,0X79,0XD6,0X79,0XD6,0X79,0XD6,0X38,0XCE,0X17,
0XDE,0X79,0XDE,0X79,0XD6,0X99,0XD6,0X99,0XD6,0X79,0XCE,0X58,0XCE,0X57,0XCE,0X37,
0XCE,0X16,0XC5,0XF6,0XC5,0XF7,0XC5,0XD6,0XC5,0XB6,0XC5,0XD7,0XCD,0XF7,0XD6,0X38,
0XD6,0X59,0XD6,0X58,0XCE,0X38,0XC5,0XF7,0XC5,0XF7,0XB5,0X95,0XBD,0X95,0XCE,0X17,
0XCD,0XF7,0XC5,0XD6,0XBD,0XB6,0XBD,0XB6,0XC5,0XD7,0XBD,0XB6,0XBD,0X95,0XAD,0X34,
0X73,0X6D,0X39,0X85,0X21,0X03,0X08,0X40,0X08,0X40,0X10,0X60,0X10,0X60,0X08,0X20,
0X08,0X20,0X08,0X40,0X08,0X20,0X08,0X40,0X00,0X20,0X00,0X20,0X00,0X20,0X00,0X20,
0X08,0X40,0X08,0X40,0X08,0X20,0X08,0X40,0X08,0X40,0X00,0X20,0X08,0X20,0X00,0X00,
0XBD,0XB7,0XBD,0XB7,0XBD,0X96,0XC5,0XF8,0XD6,0X79,0XD6,0X7A,0XD6,0X9A,0XD6,0X7A,
0XD6,0X9A,0XD6,0X9A,0XDE,0XBA,0XDE,0XDB,0XDE,0XDB,0XD6,0XBA,0XDE,0XBB,0XD6,0X9A,
0XC6,0X39,0XBD,0XD7,0XBD,0XF7,0XBD,0XD7,0XBD,0XD7,0XB5,0XB7,0XB5,0XB7,0XBD,0XD7,
0XBD,0XD7,0XBD,0XB7,0XB5,0XB7,0XBD,0XB7,0XC6,0X18,0XCE,0X7A,0XD6,0XBB,0XDE,0XFC,
0XDE,0XFC,0XDE,0XDB,0XDE,0XDB,0XDE,0XDB,0XDE,0XBB,0XDE,0XDB,0XDE,0XBB,0XDE,0XDB,
0XD6,0X9A,0XC6,0X18,0XB5,0XB6,0XBD,0XD7,0XBD,0XD7,0XBD,0XB7,0XBD,0XB7,0XB5,0X96,
0XBD,0XD7,0XBD,0XD7,0XBD,0XD7,0XBD,0XB6,0XBD,0XD7,0XCE,0X59,0XDE,0XBA,0XDE,0XBA,
0XDE,0XBA,0XDE,0XBA,0XDE,0X9A,0XDE,0X9A,0XDE,0X9A,0XDE,0X7A,0XD6,0X79,0XDE,0X9A,
0XD6,0X59,0XD6,0X59,0XD6,0X39,0XCE,0X38,0XCE,0X18,0XC6,0X17,0XBD,0XF7,0XC6,0X18,
0XCE,0X59,0XCE,0X59,0XCE,0X59,0XD6,0X79,0XCE,0X59,0XCE,0X58,0XCE,0X59,0XD6,0X59,
0XD6,0X58,0XCE,0X38,0XCE,0X18,0XD6,0X38,0XD6,0X59,0XCE,0X38,0XCE,0X38,0XCE,0X38,
0XCE,0X17,0XC5,0XD7,0XC5,0XF7,0XBD,0X75,0XA4,0XF3,0XB5,0X54,0XBD,0X95,0XBD,0XB6,
0XBD,0X96,0XBD,0XB6,0XBD,0XD6,0XC5,0XD7,0XBD,0XB6,0XB5,0X75,0XAD,0X14,0X94,0X71,
0X5A,0XAA,0X18,0XA2,0X18,0X82,0X10,0X81,0X08,0X40,0X10,0X61,0X10,0X40,0X08,0X40,
0X08,0X40,0X08,0X40,0X08,0X40,0X08,0X40,0X08,0X40,0X00,0X20,0X00,0X20,0X00,0X20,
0X08,0X40,0X08,0X60,0X08,0X60,0X08,0X40,0X08,0X40,0X08,0X20,0X08,0X00,0X00,0X00,
0XBD,0XB7,0XBD,0XB7,0XBD,0XD8,0XCE,0X5A,0XDE,0XBB,0XDE,0XBB,0XDE,0XDB,0XDE,0XBB,
0XD6,0X9A,0XD6,0X9A,0XDE,0XBB,0XDE,0XBB,0XD6,0X9A,0XD6,0XBB,0XDE,0XBB,0XD6,0X7A,
0XC6,0X18,0XBD,0XD7,0XBD,0XD7,0XBD,0XF7,0XBD,0XF7,0XBD,0XD7,0XB5,0XB7,0XB5,0XB7,
0XB5,0XB7,0XB5,0XB7,0XB5,0X97,0XB5,0X97,0XC6,0X19,0XD6,0X9A,0XD6,0XDB,0XDE,0XDB,
0XDE,0XFC,0XDE,0XDB,0XDE,0XDB,0XDE,0XDB,0XDE,0XBB,0XDE,0XBB,0XDE,0XDB,0XDE,0XBB,
0XD6,0X9A,0XC6,0X18,0XB5,0XB7,0XBD,0XB7,0XBD,0XD8,0XB5,0XB7,0XB5,0XB7,0XB5,0XB7,
0XBD,0XD7,0XBD,0XD7,0XB5,0XD7,0XBD,0XF7,0XBD,0XF8,0XD6,0X9A,0XDE,0XDB,0XDE,0XDB,
0XDE,0XBA,0XDE,0XBA,0XDE,0XBA,0XDE,0XBA,0XDE,0X9A,0XDE,0X9A,0XD6,0X9A,0XDE,0X9A,
0XCE,0X59,0XBD,0XD7,0XBD,0XF8,0XBD,0XD7,0XB5,0XB6,0XB5,0X96,0XB5,0X96,0XB5,0XB7,
0XB5,0XB8,0XB5,0XB8,0XBD,0XB7,0XC5,0XF8,0XD6,0X7A,0XD6,0X9A,0XD6,0X9B,0XD6,0X7A,
0XD6,0X7A,0XD6,0X5A,0XD6,0X5A,0XDE,0X7A,0XDE,0X9A,0XDE,0X9A,0XCD,0XF8,0XC5,0XF7,
0XC5,0XB7,0XBD,0XB6,0XBD,0X96,0XBD,0X75,0XBD,0X96,0XBD,0XB6,0XB5,0X96,0XB5,0X95,
0XBD,0XB6,0XBD,0XD6,0XB5,0X95,0XB5,0X96,0XB5,0X96,0XB5,0X75,0XA5,0X13,0X94,0X51,
0X73,0X6D,0X41,0XE7,0X29,0X24,0X18,0XA2,0X18,0XA2,0X10,0X61,0X08,0X40,0X10,0X60,
0X08,0X40,0X10,0X40,0X10,0X40,0X10,0X40,0X08,0X40,0X08,0X20,0X08,0X20,0X08,0X20,
0X08,0X20,0X08,0X40,0X08,0X40,0X08,0X40,0X08,0X20,0X08,0X20,0X08,0X00,0X00,0X00,
0XB5,0X77,0XAD,0X36,0XBD,0XB7,0XCE,0X5A,0XD6,0XDB,0XDE,0XBB,0XD6,0XBB,0XDE,0X9B,
0XD6,0X7A,0XDE,0XBB,0XDE,0XBB,0XDE,0XBB,0XD6,0XBB,0XDE,0XBB,0XDE,0XBB,0XCE,0X59,
0XBD,0XD7,0XB5,0XB6,0XB5,0XB6,0XB5,0XB7,0XB5,0XB7,0XB5,0X97,0XAD,0X76,0XAD,0X76,
0XAD,0X76,0XB5,0X76,0XAD,0X77,0XB5,0X97,0XC6,0X39,0XD6,0X9A,0XD6,0XBB,0XD6,0XDB,
0XDE,0XDB,0XD6,0XDB,0XDE,0XDB,0XDE,0XDB,0XDE,0XDB,0XDE,0XBB,0XDE,0XDB,0XDE,0XBB,
0XCE,0X59,0XBD,0XD7,0XB5,0XB7,0XBD,0XB7,0XBD,0XB8,0XB5,0XB8,0XB5,0XB7,0XB5,0XB7,
0XBD,0XD7,0XBD,0XB7,0XBD,0XB7,0XBD,0XB7,0XC6,0X39,0XDE,0XBB,0XDE,0XDB,0XDE,0XBB,
0XDE,0XDB,0XDE,0XBB,0XDE,0XBB,0XDE,0XBB,0XDE,0X9A,0XDE,0XBB,0XD6,0X9A,0XD6,0X7A,
0XC5,0XF8,0XB5,0X76,0XAD,0X76,0XAD,0X76,0XAD,0X75,0XB5,0X96,0XB5,0X76,0XB5,0X96,
0XAD,0X56,0XAD,0X56,0XB5,0X97,0XBD,0XF8,0XD6,0X9A,0XD6,0XBB,0XDE,0XBB,0XDE,0X9B,
0XDE,0X7A,0XDE,0X7A,0XDE,0X9B,0XDE,0X9B,0XDE,0XBB,0XDE,0X9B,0XC5,0XF8,0XB5,0X76,
0XB5,0X76,0XB5,0X75,0XAD,0X75,0XAD,0X75,0XAD,0X55,0XAD,0X75,0XBD,0XB6,0XB5,0X96,
0XB5,0X95,0XCE,0X38,0XD6,0X9A,0XCE,0X79,0XCE,0X59,0XCE,0X39,0XCE,0X39,0XC5,0XD7,
0XBD,0XB6,0XB5,0X55,0XA4,0XF4,0X83,0XCF,0X62,0XEC,0X52,0X49,0X39,0XC7,0X31,0X86,
0X29,0X24,0X20,0XC3,0X20,0XC3,0X18,0XA2,0X18,0X81,0X10,0X60,0X10,0X60,0X10,0X61,
0X08,0X40,0X08,0X60,0X08,0X40,0X08,0X40,0X08,0X20,0X08,0X20,0X08,0X00,0X00,0X00,
0XAD,0X35,0XAD,0X55,0XBD,0XF8,0XD6,0X9A,0XDE,0XBB,0XD6,0XBB,0XDE,0XBB,0XDE,0XBB,
0XDE,0X9B,0XDE,0XBB,0XDE,0XBB,0XDE,0XBB,0XDE,0XBB,0XDE,0XBB,0XD6,0X9B,0XC6,0X19,
0XBD,0XB7,0XB5,0XB6,0XB5,0X97,0XB5,0XB7,0XB5,0X97,0XAD,0X77,0XAD,0X77,0XA5,0X36,
0XA5,0X35,0XAD,0X56,0XAD,0X57,0XB5,0X97,0XCE,0X59,0XD6,0X9A,0XD6,0XDB,0XDE,0XDB,
0XD6,0XBB,0XD6,0XBB,0XDE,0XDB,0XDE,0XBB,0XDE,0XBB,0XDE,0XDB,0XDE,0XDB,0XDE,0XBB,
0XCE,0X59,0XBD,0XB7,0XBD,0XB7,0XBD,0XB8,0XBD,0XB8,0XBD,0XB8,0XB5,0XB7,0XB5,0XB7,
0XBD,0XB7,0XB5,0XB6,0XB5,0XB6,0XB5,0XB7,0XCE,0X59,0XDE,0XDB,0XDE,0XFB,0XDE,0XBA,
0XD6,0XBA,0XD6,0X9A,0XD6,0X9A,0XD6,0X9A,0XD6,0X7A,0XD6,0X9A,0XD6,0X9A,0XCE,0X39,
0XB5,0XB7,0XA5,0X35,0XA5,0X56,0XAD,0X77,0XAD,0X36,0XA5,0X15,0XA5,0X35,0XAD,0X55,
0X9C,0XF4,0X9C,0XF5,0XB5,0X97,0XBD,0XF8,0XCE,0X5A,0XCE,0X5A,0XCE,0X3A,0XCE,0X39,
0XCE,0X39,0XCE,0X39,0XCE,0X59,0XCE,0X5A,0XCE,0X59,0XCE,0X39,0XAD,0X76,0XA4,0XF4,
0XA5,0X14,0XA4,0XF4,0X9C,0XF4,0XA5,0X14,0XA5,0X35,0XA5,0X35,0XA5,0X55,0XA5,0X35,
0XB5,0X96,0XCE,0X39,0XD6,0X9A,0XD6,0X9A,0XCE,0X7A,0XCE,0X7A,0XCE,0X7A,0XCE,0X59,
0XCE,0X59,0XCE,0X59,0XCE,0X7A,0XBD,0XF8,0XAD,0X76,0X9D,0X14,0X9D,0X34,0X9D,0X14,
0X8C,0X51,0X8C,0X10,0X84,0X10,0X83,0XF0,0X6B,0X4D,0X5A,0XCB,0X63,0X0C,0X62,0XAA,
0X41,0XC7,0X31,0X45,0X29,0X24,0X20,0XE3,0X18,0XA1,0X18,0X81,0X10,0X20,0X08,0X20,
};
/* USER CODE END 0 */

int main(void)
{

  /* MCU Configuration--------------------------------------------------------*/

  /* Reset of all peripherals, Initializes the Flash interface and the Systick. */
  HAL_Init();

  /* Configure the system clock */
  SystemClock_Config();

  /* Initialize all configured peripherals */
  MX_GPIO_Init();
  MX_SPI1_Init();
  /* USER CODE BEGIN 2 */
  SPI_CS_Enable();
 // uint8_t cmd[10] = {0x10,0x10,0x10,0x10,0x10,0x10,0x10,0x10,0x10,0x10};
HAL_SPI_Transmit(&hspi1,gImage_1,32768,100);
  /* USER CODE END 2 */

  /* Infinite loop */
  while (1)
  {

  }
}

void SystemClock_Config(void)
{
  RCC_OscInitTypeDef RCC_OscInitStruct = {0};
  RCC_ClkInitTypeDef RCC_ClkInitStruct = {0};

  /** Initializes the RCC Oscillators according to the specified parameters
  * in the RCC_OscInitTypeDef structure.
  */
  RCC_OscInitStruct.OscillatorType = RCC_OSCILLATORTYPE_HSE;
  RCC_OscInitStruct.HSEState = RCC_HSE_ON;
  RCC_OscInitStruct.HSEPredivValue = RCC_HSE_PREDIV_DIV1;
  RCC_OscInitStruct.HSIState = RCC_HSI_ON;
  RCC_OscInitStruct.PLL.PLLState = RCC_PLL_ON;
  RCC_OscInitStruct.PLL.PLLSource = RCC_PLLSOURCE_HSE;
  RCC_OscInitStruct.PLL.PLLMUL = RCC_PLL_MUL9;
  if (HAL_RCC_OscConfig(&RCC_OscInitStruct) != HAL_OK)
  {
    Error_Handler();
  }

  /** Initializes the CPU, AHB and APB buses clocks
  */
  RCC_ClkInitStruct.ClockType = RCC_CLOCKTYPE_HCLK|RCC_CLOCKTYPE_SYSCLK
                              |RCC_CLOCKTYPE_PCLK1|RCC_CLOCKTYPE_PCLK2;
  RCC_ClkInitStruct.SYSCLKSource = RCC_SYSCLKSOURCE_PLLCLK;
  RCC_ClkInitStruct.AHBCLKDivider = RCC_SYSCLK_DIV1;
  RCC_ClkInitStruct.APB1CLKDivider = RCC_HCLK_DIV2;
  RCC_ClkInitStruct.APB2CLKDivider = RCC_HCLK_DIV1;

  if (HAL_RCC_ClockConfig(&RCC_ClkInitStruct, FLASH_LATENCY_2) != HAL_OK)
  {
    Error_Handler();
  }
}

void Error_Handler(void)
{
  __disable_irq();
  while (1)
  {
  }
}
